VERSION ""

NS_ :

BS_:

BU_: RLPSU DPSU APSU PSB SHVU_RR vHS_B2 FCS EMCU SLB RCM CGW_CCU vDummy_HS_B ATS RLHV PFSU SGU ALBCU DSAU SWRC SHVU_FR RCS RRPSU BLTN_CAM SCM DLBCU OHCL RWPC RRHV WPC HOD ASAU

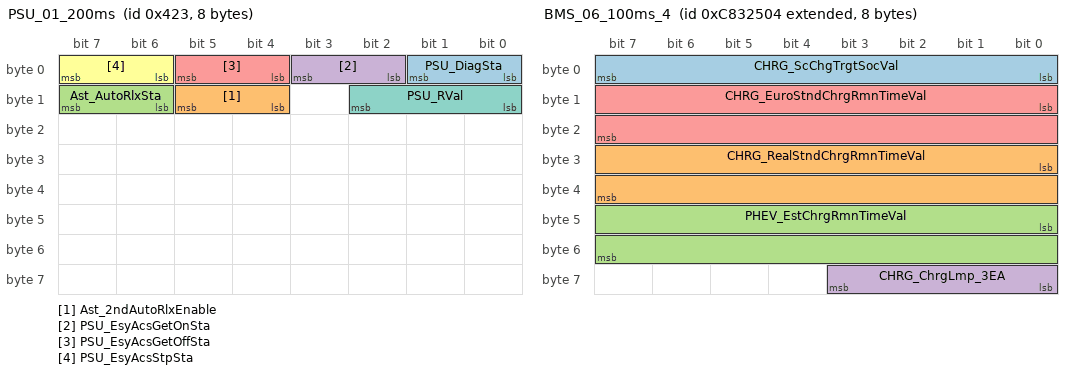
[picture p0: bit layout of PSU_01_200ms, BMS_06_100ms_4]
BO_ 1059 PSU_01_200ms: 8 APSU
 SG_ PSU_DiagSta : 0|2@1+ (1,0) [0|0] ""  Vector__XXX
 SG_ Ast_2ndAutoRlxEnable : 12|2@1+ (1,0) [0|0] ""  RLPSU,RRPSU
 SG_ Ast_AutoRlxSta : 14|2@1+ (1,0) [0|0] ""  RLPSU,RRPSU
 SG_ PSU_EsyAcsGetOnSta : 2|2@1+ (1,0) [0|0] ""  SLB
 SG_ PSU_EsyAcsGetOffSta : 4|2@1+ (1,0) [0|0] ""  SLB
 SG_ PSU_EsyAcsStpSta : 6|2@1+ (1,0) [0|0] ""  SLB
 SG_ PSU_RVal : 8|3@1+ (1,0) [0|0] ""  Vector__XXX

BO_ 2357404932 BMS_06_100ms_4: 8 CGW_CCU
 SG_ CHRG_ScChgTrgtSocVal : 0|8@1+ (0.5,0) [0|0] "%"  Vector__XXX
 SG_ CHRG_RealStndChrgRmnTimeVal : 24|16@1+ (1,0) [0|0] "minute"  Vector__XXX
 SG_ PHEV_EstChrgRmnTimeVal : 40|16@1+ (1,0) [0|0] "min"  Vector__XXX
 SG_ CHRG_ChrgLmp_3EA : 56|4@1+ (1,0) [0|0] "minute"  Vector__XXX
 SG_ CHRG_EuroStndChrgRmnTimeVal : 8|16@1+ (1,0) [0|0] "minute"  Vector__XXX

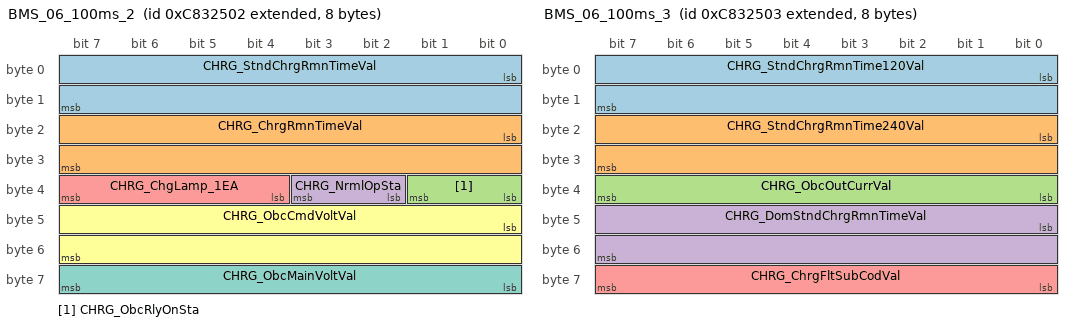
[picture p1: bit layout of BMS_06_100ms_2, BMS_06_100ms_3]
BO_ 2357404930 BMS_06_100ms_2: 8 CGW_CCU
 SG_ CHRG_StndChrgRmnTimeVal : 0|16@1+ (1,0) [0|0] "minute"  Vector__XXX
 SG_ CHRG_ChrgRmnTimeVal : 16|16@1+ (1,0) [0|0] "min"  Vector__XXX
 SG_ CHRG_ObcRlyOnSta : 32|2@1+ (1,0) [0|0] ""  Vector__XXX
 SG_ CHRG_NrmlOpSta : 34|2@1+ (1,0) [0|0] ""  Vector__XXX
 SG_ CHRG_ChgLamp_1EA : 36|4@1+ (1,0) [0|0] ""  Vector__XXX
 SG_ CHRG_ObcCmdVoltVal : 40|16@1+ (0.1,0) [0|0] "V"  Vector__XXX
 SG_ CHRG_ObcMainVoltVal : 56|8@1+ (2,0) [0|0] "V"  Vector__XXX

BO_ 2357404931 BMS_06_100ms_3: 8 CGW_CCU
 SG_ CHRG_StndChrgRmnTime120Val : 0|16@1+ (1,0) [0|0] "minute"  Vector__XXX
 SG_ CHRG_StndChrgRmnTime240Val : 16|16@1+ (1,0) [0|0] "minute"  Vector__XXX
 SG_ CHRG_ObcOutCurrVal : 32|8@1+ (0.1,0) [0|0] "A"  Vector__XXX
 SG_ CHRG_DomStndChrgRmnTimeVal : 40|16@1+ (1,0) [0|0] "minute"  Vector__XXX
 SG_ CHRG_ChrgFltSubCodVal : 56|8@1+ (1,0) [0|0] ""  Vector__XXX

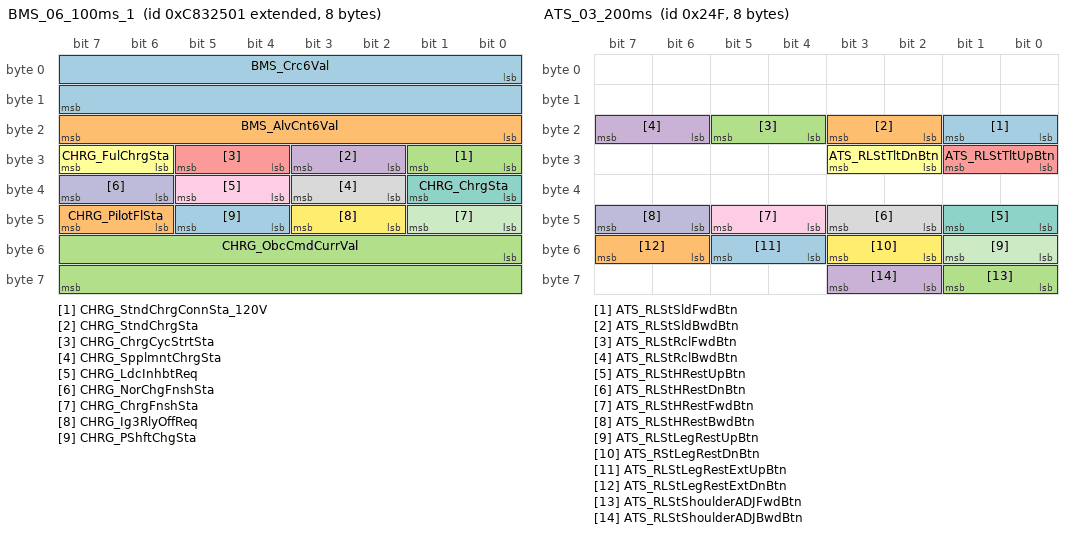
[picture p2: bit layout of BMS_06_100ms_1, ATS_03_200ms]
BO_ 2357404929 BMS_06_100ms_1: 8 CGW_CCU
 SG_ BMS_Crc6Val : 0|16@1+ (1,0) [0|0] ""  Vector__XXX
 SG_ BMS_AlvCnt6Val : 16|8@1+ (1,0) [0|0] ""  Vector__XXX
 SG_ CHRG_StndChrgConnSta_120V : 24|2@1+ (1,0) [0|0] "flag"  Vector__XXX
 SG_ CHRG_StndChrgSta : 26|2@1+ (1,0) [0|0] ""  Vector__XXX
 SG_ CHRG_ChrgCycStrtSta : 28|2@1+ (1,0) [0|0] ""  Vector__XXX
 SG_ CHRG_FulChrgSta : 30|2@1+ (1,0) [0|0] ""  Vector__XXX
 SG_ CHRG_ChrgSta : 32|2@1+ (1,0) [0|0] ""  SWRC
 SG_ CHRG_SpplmntChrgSta : 34|2@1+ (1,0) [0|0] ""  Vector__XXX
 SG_ CHRG_LdcInhbtReq : 36|2@1+ (1,0) [0|0] ""  Vector__XXX
 SG_ CHRG_NorChgFnshSta : 38|2@1+ (1,0) [0|0] ""  Vector__XXX
 SG_ CHRG_ChrgFnshSta : 40|2@1+ (1,0) [0|0] ""  Vector__XXX
 SG_ CHRG_Ig3RlyOffReq : 42|2@1+ (1,0) [0|0] ""  Vector__XXX
 SG_ CHRG_PShftChgSta : 44|2@1+ (1,0) [0|0] "flag"  Vector__XXX
 SG_ CHRG_PilotFlSta : 46|2@1+ (1,0) [0|0] "flag"  Vector__XXX
 SG_ CHRG_ObcCmdCurrVal : 48|16@1+ (0.1,0) [0|0] "A"  Vector__XXX

BO_ 591 ATS_03_200ms: 8 ATS
 SG_ ATS_RLStSldFwdBtn : 16|2@1+ (1,0) [0|0] ""  Vector__XXX
 SG_ ATS_RLStSldBwdBtn : 18|2@1+ (1,0) [0|0] ""  Vector__XXX
 SG_ ATS_RLStRclFwdBtn : 20|2@1+ (1,0) [0|0] ""  Vector__XXX
 SG_ ATS_RLStRclBwdBtn : 22|2@1+ (1,0) [0|0] ""  Vector__XXX
 SG_ ATS_RLStTltUpBtn : 24|2@1+ (1,0) [0|0] ""  Vector__XXX
 SG_ ATS_RLStTltDnBtn : 26|2@1+ (1,0) [0|0] ""  Vector__XXX
 SG_ ATS_RLStHRestUpBtn : 40|2@1+ (1,0) [0|0] ""  Vector__XXX
 SG_ ATS_RLStHRestDnBtn : 42|2@1+ (1,0) [0|0] ""  Vector__XXX
 SG_ ATS_RLStHRestFwdBtn : 44|2@1+ (1,0) [0|0] ""  Vector__XXX
 SG_ ATS_RLStHRestBwdBtn : 46|2@1+ (1,0) [0|0] ""  Vector__XXX
 SG_ ATS_RLStLegRestUpBtn : 48|2@1+ (1,0) [0|0] ""  Vector__XXX
 SG_ ATS_RStLegRestDnBtn : 50|2@1+ (1,0) [0|0] ""  Vector__XXX
 SG_ ATS_RLStLegRestExtUpBtn : 52|2@1+ (1,0) [0|0] ""  Vector__XXX
 SG_ ATS_RLStLegRestExtDnBtn : 54|2@1+ (1,0) [0|0] ""  Vector__XXX
 SG_ ATS_RLStShoulderADJFwdBtn : 56|2@1+ (1,0) [0|0] ""  Vector__XXX
 SG_ ATS_RLStShoulderADJBwdBtn : 58|2@1+ (1,0) [0|0] ""  Vector__XXX

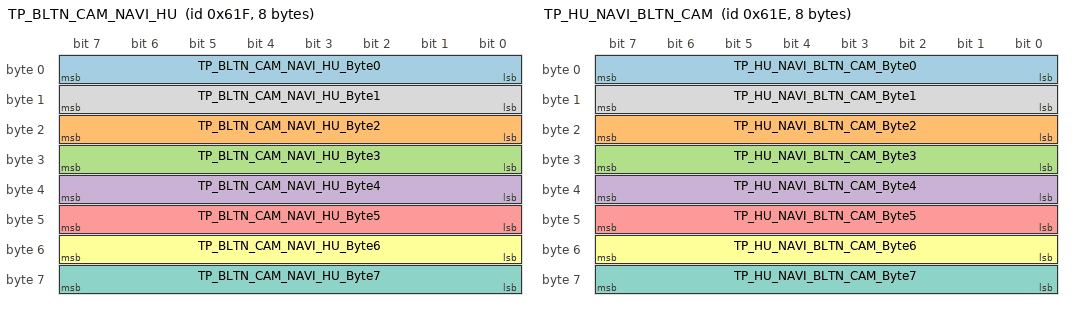
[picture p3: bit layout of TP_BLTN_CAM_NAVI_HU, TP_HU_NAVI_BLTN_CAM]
BO_ 1567 TP_BLTN_CAM_NAVI_HU: 8 BLTN_CAM
 SG_ TP_BLTN_CAM_NAVI_HU_Byte0 : 0|8@1+ (1,0) [0|0] ""  CGW_CCU
 SG_ TP_BLTN_CAM_NAVI_HU_Byte2 : 16|8@1+ (1,0) [0|0] ""  CGW_CCU
 SG_ TP_BLTN_CAM_NAVI_HU_Byte3 : 24|8@1+ (1,0) [0|0] ""  CGW_CCU
 SG_ TP_BLTN_CAM_NAVI_HU_Byte4 : 32|8@1+ (1,0) [0|0] ""  CGW_CCU
 SG_ TP_BLTN_CAM_NAVI_HU_Byte5 : 40|8@1+ (1,0) [0|0] ""  CGW_CCU
 SG_ TP_BLTN_CAM_NAVI_HU_Byte6 : 48|8@1+ (1,0) [0|0] ""  CGW_CCU
 SG_ TP_BLTN_CAM_NAVI_HU_Byte7 : 56|8@1+ (1,0) [0|0] ""  CGW_CCU
 SG_ TP_BLTN_CAM_NAVI_HU_Byte1 : 8|8@1+ (1,0) [0|0] ""  CGW_CCU

BO_ 1566 TP_HU_NAVI_BLTN_CAM: 8 CGW_CCU
 SG_ TP_HU_NAVI_BLTN_CAM_Byte0 : 0|8@1+ (1,0) [0|0] ""  BLTN_CAM
 SG_ TP_HU_NAVI_BLTN_CAM_Byte2 : 16|8@1+ (1,0) [0|0] ""  BLTN_CAM
 SG_ TP_HU_NAVI_BLTN_CAM_Byte3 : 24|8@1+ (1,0) [0|0] ""  BLTN_CAM
 SG_ TP_HU_NAVI_BLTN_CAM_Byte4 : 32|8@1+ (1,0) [0|0] ""  BLTN_CAM
 SG_ TP_HU_NAVI_BLTN_CAM_Byte5 : 40|8@1+ (1,0) [0|0] ""  BLTN_CAM
 SG_ TP_HU_NAVI_BLTN_CAM_Byte6 : 48|8@1+ (1,0) [0|0] ""  BLTN_CAM
 SG_ TP_HU_NAVI_BLTN_CAM_Byte7 : 56|8@1+ (1,0) [0|0] ""  BLTN_CAM
 SG_ TP_HU_NAVI_BLTN_CAM_Byte1 : 8|8@1+ (1,0) [0|0] ""  BLTN_CAM

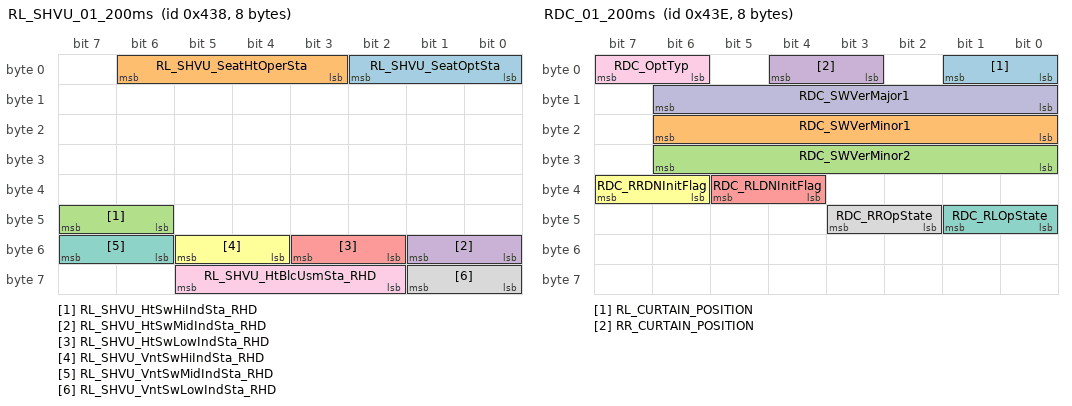
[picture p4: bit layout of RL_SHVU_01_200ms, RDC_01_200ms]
BO_ 1080 RL_SHVU_01_200ms: 8 RLHV
 SG_ RL_SHVU_SeatOptSta : 0|3@1+ (1,0) [0|0] ""  ATS,CGW_CCU
 SG_ RL_SHVU_SeatHtOperSta : 3|4@1+ (1,0) [0|0] ""  ATS,CGW_CCU
 SG_ RL_SHVU_HtSwHiIndSta_RHD : 46|2@1+ (1,0) [0|0] ""  ATS,CGW_CCU,CGW_CCU
 SG_ RL_SHVU_HtSwMidIndSta_RHD : 48|2@1+ (1,0) [0|0] ""  ATS,CGW_CCU
 SG_ RL_SHVU_HtSwLowIndSta_RHD : 50|2@1+ (1,0) [0|0] ""  ATS,CGW_CCU
 SG_ RL_SHVU_VntSwHiIndSta_RHD : 52|2@1+ (1,0) [0|0] ""  ATS,CGW_CCU
 SG_ RL_SHVU_VntSwMidIndSta_RHD : 54|2@1+ (1,0) [0|0] ""  ATS,CGW_CCU
 SG_ RL_SHVU_VntSwLowIndSta_RHD : 56|2@1+ (1,0) [0|0] ""  ATS,CGW_CCU
 SG_ RL_SHVU_HtBlcUsmSta_RHD : 58|4@1+ (1,0) [0|0] ""  ATS,CGW_CCU

BO_ 1086 RDC_01_200ms: 8 CGW_CCU
 SG_ RL_CURTAIN_POSITION : 0|2@1+ (1,0) [0|0] ""  ATS
 SG_ RDC_SWVerMinor1 : 16|7@1+ (1,0) [0|0] ""  Vector__XXX
 SG_ RDC_SWVerMinor2 : 24|7@1+ (1,0) [0|0] ""  Vector__XXX
 SG_ RR_CURTAIN_POSITION : 3|2@1+ (1,0) [0|0] ""  ATS
 SG_ RDC_RLDNInitFlag : 36|2@1+ (1,0) [0|0] ""  Vector__XXX
 SG_ RDC_RRDNInitFlag : 38|2@1+ (1,0) [0|0] ""  Vector__XXX
 SG_ RDC_RLOpState : 40|2@1+ (1,0) [0|0] ""  Vector__XXX
 SG_ RDC_RROpState : 42|2@1+ (1,0) [0|0] ""  Vector__XXX
 SG_ RDC_OptTyp : 6|2@1+ (1,0) [0|0] ""  ATS
 SG_ RDC_SWVerMajor1 : 8|7@1+ (1,0) [0|0] ""  Vector__XXX

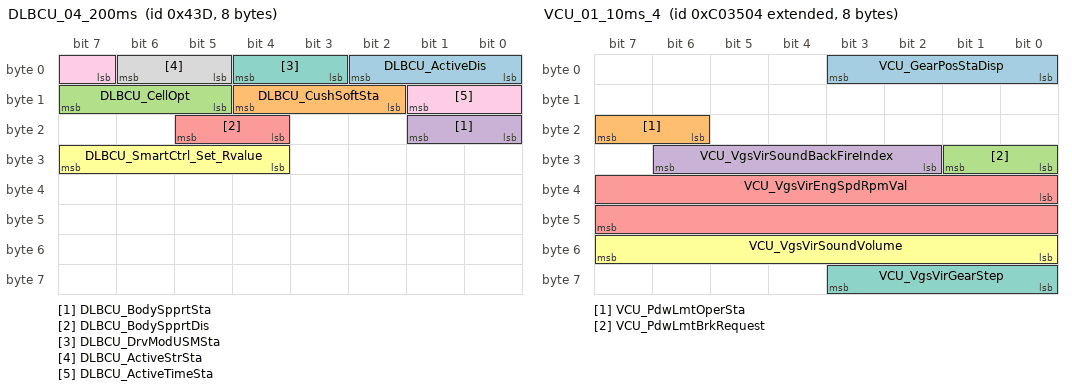
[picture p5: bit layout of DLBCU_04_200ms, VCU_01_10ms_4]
BO_ 1085 DLBCU_04_200ms: 8 DLBCU
 SG_ DLBCU_ActiveDis : 0|3@1+ (1,0) [0|0] ""  DPSU,CGW_CCU
 SG_ DLBCU_CushSoftSta : 10|3@1+ (1,0) [0|0] ""  CGW_CCU
 SG_ DLBCU_CellOpt : 13|3@1+ (1,0) [0|0] ""  Vector__XXX
 SG_ DLBCU_BodySpprtSta : 16|2@1+ (1,0) [0|0] ""  CGW_CCU
 SG_ DLBCU_BodySpprtDis : 20|2@1+ (1,0) [0|0] ""  CGW_CCU
 SG_ DLBCU_SmartCtrl_Set_Rvalue : 28|4@1+ (1,0) [0|0] ""  CGW_CCU
 SG_ DLBCU_DrvModUSMSta : 3|2@1+ (1,0) [0|0] ""  CGW_CCU
 SG_ DLBCU_ActiveStrSta : 5|2@1+ (1,0) [0|0] ""  CGW_CCU
 SG_ DLBCU_ActiveTimeSta : 7|3@1+ (1,0) [0|0] ""  CGW_CCU

BO_ 2160080132 VCU_01_10ms_4: 8 CGW_CCU
 SG_ VCU_GearPosStaDisp : 0|4@1+ (1,0) [0|0] ""  BLTN_CAM
 SG_ VCU_PdwLmtOperSta : 22|2@1+ (1,0) [0|0] ""  Vector__XXX
 SG_ VCU_PdwLmtBrkRequest : 24|2@1+ (1,0) [0|0] ""  Vector__XXX
 SG_ VCU_VgsVirSoundBackFireIndex : 26|5@1+ (1,0) [0|0] ""  Vector__XXX
 SG_ VCU_VgsVirEngSpdRpmVal : 32|16@1- (1,0) [0|0] ""  Vector__XXX
 SG_ VCU_VgsVirSoundVolume : 48|8@1+ (0.392156863,0) [0|0] ""  Vector__XXX
 SG_ VCU_VgsVirGearStep : 56|4@1+ (1,0) [0|0] ""  Vector__XXX

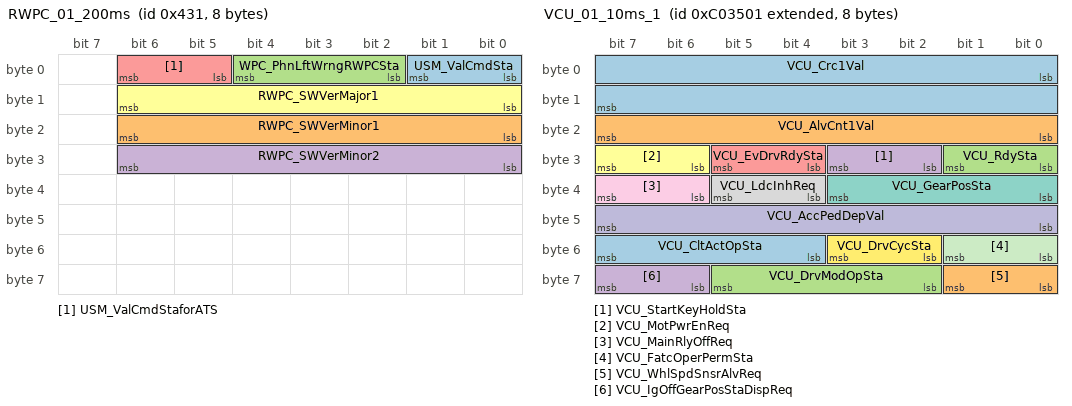
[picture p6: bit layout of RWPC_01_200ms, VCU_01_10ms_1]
BO_ 1073 RWPC_01_200ms: 8 RWPC
 SG_ USM_ValCmdSta : 0|2@1+ (1,0) [0|0] ""  ATS,CGW_CCU
 SG_ RWPC_SWVerMinor1 : 16|7@1+ (1,0) [0|0] ""  CGW_CCU
 SG_ WPC_PhnLftWrngRWPCSta : 2|3@1+ (1,0) [0|0] ""  ATS,CGW_CCU
 SG_ RWPC_SWVerMinor2 : 24|7@1+ (1,0) [0|0] ""  CGW_CCU
 SG_ USM_ValCmdStaforATS : 5|2@1+ (1,0) [0|0] ""  ATS
 SG_ RWPC_SWVerMajor1 : 8|7@1+ (1,0) [0|0] ""  CGW_CCU

BO_ 2160080129 VCU_01_10ms_1: 8 CGW_CCU
 SG_ VCU_Crc1Val : 0|16@1+ (1,0) [0|0] ""  Vector__XXX
 SG_ VCU_AlvCnt1Val : 16|8@1+ (1,0) [0|0] ""  Vector__XXX
 SG_ VCU_RdySta : 24|2@1+ (1,0) [0|3] ""  Vector__XXX
 SG_ VCU_StartKeyHoldSta : 26|2@1+ (1,0) [0|3] ""  Vector__XXX
 SG_ VCU_EvDrvRdySta : 28|2@1+ (1,0) [0|3] ""  WPC,RWPC,SWRC,HOD,BLTN_CAM
 SG_ VCU_MotPwrEnReq : 30|2@1+ (1,0) [0|3] ""  Vector__XXX
 SG_ VCU_GearPosSta : 32|4@1+ (1,0) [0|15] ""  SWRC,APSU,DPSU,PFSU,RRPSU,RLPSU,BLTN_CAM
 SG_ VCU_LdcInhReq : 36|2@1+ (1,0) [0|3] ""  Vector__XXX
 SG_ VCU_MainRlyOffReq : 38|2@1+ (1,0) [0|3] ""  Vector__XXX
 SG_ VCU_AccPedDepVal : 40|8@1+ (0.3921568627,0) [0|100] "%"  BLTN_CAM
 SG_ VCU_FatcOperPermSta : 48|2@1+ (1,0) [0|3] ""  Vector__XXX
 SG_ VCU_DrvCycSta : 50|2@1+ (1,0) [0|3] ""  Vector__XXX
 SG_ VCU_CltActOpSta : 52|4@1+ (1,0) [0|15] ""  Vector__XXX
 SG_ VCU_WhlSpdSnsrAlvReq : 56|2@1+ (1,0) [0|0] "flag"  Vector__XXX
 SG_ VCU_DrvModOpSta : 58|4@1+ (1,0) [0|0] ""  Vector__XXX
 SG_ VCU_IgOffGearPosStaDispReq : 62|2@1+ (1,0) [0|0] "flag"  Vector__XXX

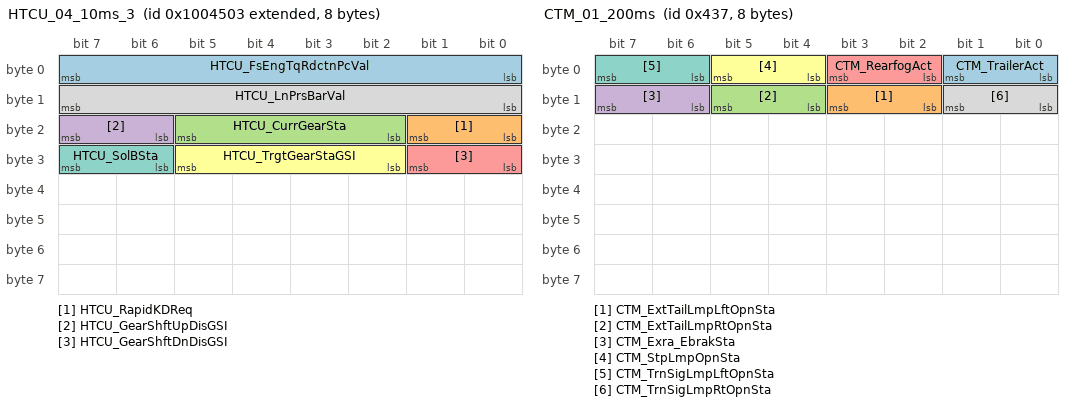
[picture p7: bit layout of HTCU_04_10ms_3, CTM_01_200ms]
BO_ 2164278531 HTCU_04_10ms_3: 8 CGW_CCU
 SG_ HTCU_FsEngTqRdctnPcVal : 0|8@1+ (0.390625,0) [0|0] "%"  Vector__XXX
 SG_ HTCU_RapidKDReq : 16|2@1+ (1,0) [0|0] ""  Vector__XXX
 SG_ HTCU_CurrGearSta : 18|4@1+ (1,0) [0|0] ""  Vector__XXX
 SG_ HTCU_GearShftUpDisGSI : 22|2@1+ (1,0) [0|0] ""  Vector__XXX
 SG_ HTCU_GearShftDnDisGSI : 24|2@1+ (1,0) [0|0] ""  Vector__XXX
 SG_ HTCU_TrgtGearStaGSI : 26|4@1+ (1,0) [0|0] ""  Vector__XXX
 SG_ HTCU_SolBSta : 30|2@1+ (1,0) [0|0] ""  Vector__XXX
 SG_ HTCU_LnPrsBarVal : 8|8@1+ (0.1,0) [0|0] "Bar"  Vector__XXX

BO_ 1079 CTM_01_200ms: 8 CGW_CCU
 SG_ CTM_TrailerAct : 0|2@1+ (1,0) [0|0] ""  BLTN_CAM
 SG_ CTM_ExtTailLmpLftOpnSta : 10|2@1+ (1,0) [0|0] ""  Vector__XXX
 SG_ CTM_ExtTailLmpRtOpnSta : 12|2@1+ (1,0) [0|0] ""  Vector__XXX
 SG_ CTM_Exra_EbrakSta : 14|2@1+ (1,0) [0|0] ""  Vector__XXX
 SG_ CTM_RearfogAct : 2|2@1+ (1,0) [0|0] ""  Vector__XXX
 SG_ CTM_StpLmpOpnSta : 4|2@1+ (1,0) [0|0] ""  Vector__XXX
 SG_ CTM_TrnSigLmpLftOpnSta : 6|2@1+ (1,0) [0|0] ""  Vector__XXX
 SG_ CTM_TrnSigLmpRtOpnSta : 8|2@1+ (1,0) [0|0] ""  Vector__XXX

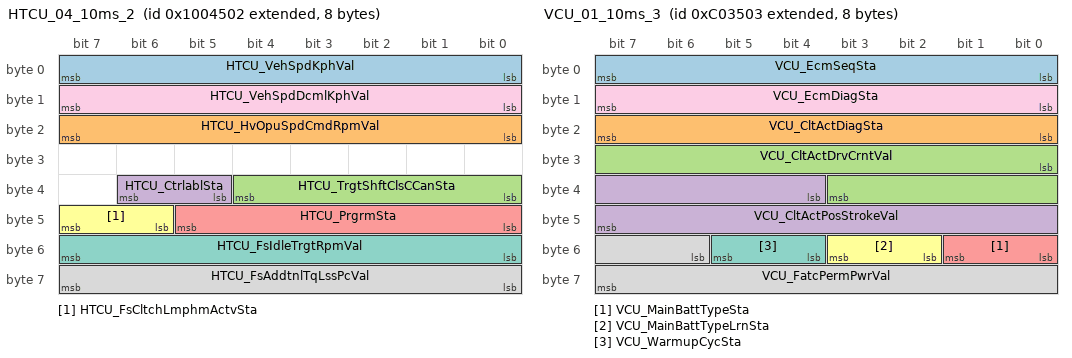
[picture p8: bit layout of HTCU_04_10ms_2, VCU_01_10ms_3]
BO_ 2164278530 HTCU_04_10ms_2: 8 CGW_CCU
 SG_ HTCU_VehSpdKphVal : 0|8@1+ (1,0) [0|0] "kph"  Vector__XXX
 SG_ HTCU_HvOpuSpdCmdRpmVal : 16|8@1+ (20,0) [0|0] "rpm"  Vector__XXX
 SG_ HTCU_TrgtShftClsCCanSta : 32|5@1+ (1,0) [0|0] ""  Vector__XXX
 SG_ HTCU_CtrlablSta : 37|2@1+ (1,0) [0|0] ""  Vector__XXX
 SG_ HTCU_PrgrmSta : 40|6@1+ (1,0) [0|0] ""  Vector__XXX
 SG_ HTCU_FsCltchLmphmActvSta : 46|2@1+ (1,0) [0|0] ""  Vector__XXX
 SG_ HTCU_FsIdleTrgtRpmVal : 48|8@1+ (10,0) [0|0] "rpm"  Vector__XXX
 SG_ HTCU_FsAddtnlTqLssPcVal : 56|8@1+ (0.390625,0) [0|0] "%"  Vector__XXX
 SG_ HTCU_VehSpdDcmlKphVal : 8|8@1+ (0.0078125,0) [0|0] "kph"  Vector__XXX

BO_ 2160080131 VCU_01_10ms_3: 8 CGW_CCU
 SG_ VCU_EcmSeqSta : 0|8@1+ (1,0) [0|255] ""  Vector__XXX
 SG_ VCU_CltActDiagSta : 16|8@1+ (1,0) [0|255] ""  Vector__XXX
 SG_ VCU_CltActDrvCrntVal : 24|12@1- (0.025,0) [-51.2|51.175] "A"  Vector__XXX
 SG_ VCU_CltActPosStrokeVal : 36|12@1- (0.0125,0) [-25.6|25.5875] "mm"  Vector__XXX
 SG_ VCU_MainBattTypeSta : 48|2@1+ (1,0) [0|3] ""  Vector__XXX
 SG_ VCU_MainBattTypeLrnSta : 50|2@1+ (1,0) [0|3] ""  Vector__XXX
 SG_ VCU_WarmupCycSta : 52|2@1+ (1,0) [0|3] ""  Vector__XXX
 SG_ VCU_FatcPermPwrVal : 54|10@1+ (20,0) [0|12700] "W"  Vector__XXX
 SG_ VCU_EcmDiagSta : 8|8@1+ (1,0) [0|255] ""  Vector__XXX

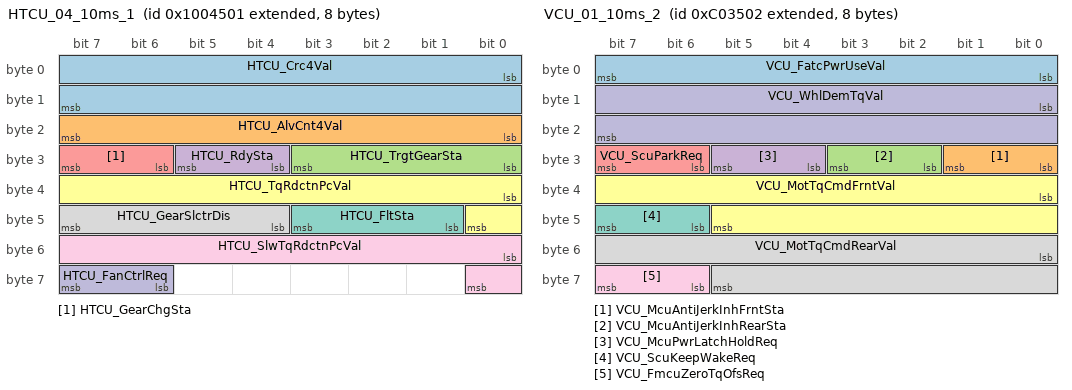
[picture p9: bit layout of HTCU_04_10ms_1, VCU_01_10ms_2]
BO_ 2164278529 HTCU_04_10ms_1: 8 CGW_CCU
 SG_ HTCU_Crc4Val : 0|16@1+ (1,0) [0|0] ""  Vector__XXX
 SG_ HTCU_AlvCnt4Val : 16|8@1+ (1,0) [0|0] ""  Vector__XXX
 SG_ HTCU_TrgtGearSta : 24|4@1+ (1,0) [0|0] ""  Vector__XXX
 SG_ HTCU_RdySta : 28|2@1+ (1,0) [0|0] ""  Vector__XXX
 SG_ HTCU_GearChgSta : 30|2@1+ (1,0) [0|0] ""  Vector__XXX
 SG_ HTCU_TqRdctnPcVal : 32|9@1+ (0.390625,0) [0|0] "%"  Vector__XXX
 SG_ HTCU_FltSta : 41|3@1+ (1,0) [0|0] ""  Vector__XXX
 SG_ HTCU_GearSlctrDis : 44|4@1+ (1,0) [0|0] ""  BLTN_CAM
 SG_ HTCU_SlwTqRdctnPcVal : 48|9@1+ (0.390625,0) [0|0] "%"  Vector__XXX
 SG_ HTCU_FanCtrlReq : 62|2@1+ (1,0) [0|0] ""  Vector__XXX

BO_ 607 ATS_04_200ms: 8 ATS
 SG_ ATS_RRStSldFwdBtn : 16|2@1+ (1,0) [0|0] ""  Vector__XXX
 SG_ ATS_RRStSldBwdBtn : 18|2@1+ (1,0) [0|0] ""  Vector__XXX
 SG_ ATS_RRStRclFwdBtn : 20|2@1+ (1,0) [0|0] ""  Vector__XXX
 SG_ ATS_RRStRclBwdBtn : 22|2@1+ (1,0) [0|0] ""  Vector__XXX
 SG_ ATS_RRStTltUpBtn : 24|2@1+ (1,0) [0|0] ""  Vector__XXX
 SG_ ATS_RRStTltDnBtn : 26|2@1+ (1,0) [0|0] ""  Vector__XXX
 SG_ ATS_RRStLegRestPopBtn : 32|2@1+ (1,0) [0|0] ""  Vector__XXX
 SG_ ATS_RRStFRestPopBtn : 34|2@1+ (1,0) [0|0] ""  Vector__XXX
 SG_ ATS_RRStAstPopBtn : 36|2@1+ (1,0) [0|0] ""  Vector__XXX
 SG_ ATS_RRFauCondiBtn : 38|2@1+ (1,0) [0|0] ""  Vector__XXX
 SG_ ATS_RRStHRestUpBtn : 40|2@1+ (1,0) [0|0] ""  Vector__XXX
 SG_ ATS_RRStHRestDnBtn : 42|2@1+ (1,0) [0|0] ""  Vector__XXX
 SG_ ATS_RRStHRestFwdBtn : 44|2@1+ (1,0) [0|0] ""  Vector__XXX
 SG_ ATS_RRStHRestBwdBtn : 46|2@1+ (1,0) [0|0] ""  Vector__XXX
 SG_ ATS_RRStShoulderADJFwdBtn : 48|2@1+ (1,0) [0|0] ""  Vector__XXX
 SG_ ATS_RRStShoulderADJBwdBtn : 50|2@1+ (1,0) [0|0] ""  Vector__XXX
 SG_ ATS_RRStLegRestUpBtn : 56|2@1+ (1,0) [0|0] ""  Vector__XXX
 SG_ ATS_RRStLegRestDnBtn : 58|2@1+ (1,0) [0|0] ""  Vector__XXX
 SG_ ATS_RRStLegRestExtUpBtn : 60|2@1+ (1,0) [0|0] ""  Vector__XXX
 SG_ ATS_RRStLegRestExtDnBtn : 62|2@1+ (1,0) [0|0] ""  Vector__XXX

BO_ 2160080130 VCU_01_10ms_2: 8 CGW_CCU
 SG_ VCU_FatcPwrUseVal : 0|8@1+ (10,0) [0|2550] "W"  Vector__XXX
 SG_ VCU_McuAntiJerkInhFrntSta : 24|2@1+ (1,0) [0|3] ""  Vector__XXX
 SG_ VCU_McuAntiJerkInhRearSta : 26|2@1+ (1,0) [0|3] ""  Vector__XXX
 SG_ VCU_McuPwrLatchHoldReq : 28|2@1+ (1,0) [0|0] ""  Vector__XXX
 SG_ VCU_ScuParkReq : 30|2@1+ (1,0) [0|0] "flag"  Vector__XXX
 SG_ VCU_MotTqCmdFrntVal : 32|14@1- (0.125,0) [-1024|1023.875] "Nm"  Vector__XXX
 SG_ VCU_ScuKeepWakeReq : 46|2@1+ (1,0) [0|0] "flag"  Vector__XXX
 SG_ VCU_MotTqCmdRearVal : 48|14@1- (0.125,0) [-1024|1023.875] "Nm"  Vector__XXX
 SG_ VCU_FmcuZeroTqOfsReq : 62|2@1+ (1,0) [0|0] "flag"  Vector__XXX
 SG_ VCU_WhlDemTqVal : 8|16@1- (1,0) [-32768|32767] "Nm"  Vector__XXX

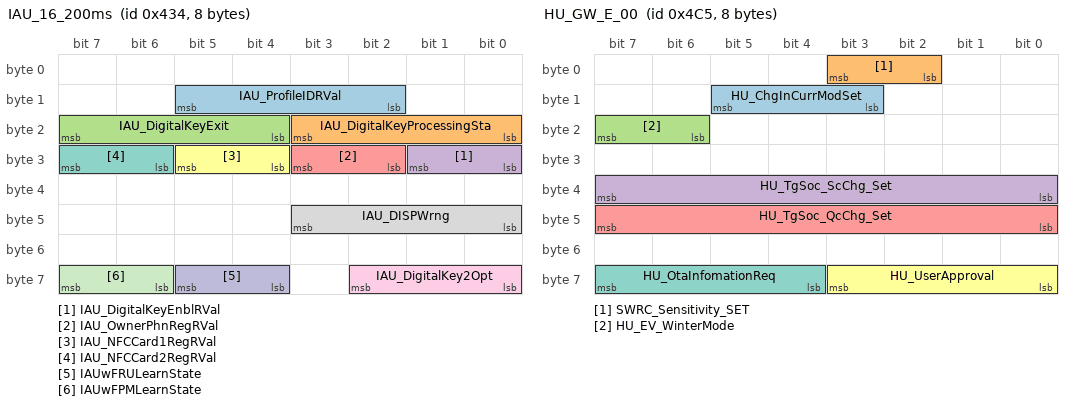
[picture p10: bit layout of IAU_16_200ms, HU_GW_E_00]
BO_ 1076 IAU_16_200ms: 8 CGW_CCU
 SG_ IAU_ProfileIDRVal : 10|4@1+ (1,0) [0|0] ""  WPC,RWPC,DPSU,BLTN_CAM,SGU
 SG_ IAU_DigitalKeyProcessingSta : 16|4@1+ (1,0) [0|0] ""  Vector__XXX
 SG_ IAU_DigitalKeyExit : 20|4@1+ (1,0) [0|0] ""  Vector__XXX
 SG_ IAU_DigitalKeyEnblRVal : 24|2@1+ (1,0) [0|0] ""  Vector__XXX
 SG_ IAU_OwnerPhnRegRVal : 26|2@1+ (1,0) [0|0] ""  Vector__XXX
 SG_ IAU_NFCCard1RegRVal : 28|2@1+ (1,0) [0|0] ""  Vector__XXX
 SG_ IAU_NFCCard2RegRVal : 30|2@1+ (1,0) [0|0] ""  Vector__XXX
 SG_ IAU_DISPWrng : 40|4@1+ (1,0) [0|0] ""  Vector__XXX
 SG_ IAU_DigitalKey2Opt : 56|3@1+ (1,0) [0|0] ""  WPC
 SG_ IAUwFRULearnState : 60|2@1+ (1,0) [0|0] ""  Vector__XXX
 SG_ IAUwFPMLearnState : 62|2@1+ (1,0) [0|0] ""  Vector__XXX

BO_ 1221 HU_GW_E_00: 8 CGW_CCU
 SG_ HU_ChgInCurrModSet : 11|3@1+ (1,0) [0|0] ""  Vector__XXX
 SG_ SWRC_Sensitivity_SET : 2|2@1+ (1,0) [0|0] ""  SWRC
 SG_ HU_EV_WinterMode : 22|2@1+ (1,0) [0|0] ""  Vector__XXX
 SG_ HU_TgSoc_ScChg_Set : 32|8@1+ (0.5,0) [0|100] "%"  Vector__XXX
 SG_ HU_TgSoc_QcChg_Set : 40|8@1+ (0.5,0) [0|100] "%"  Vector__XXX
 SG_ HU_UserApproval : 56|4@1+ (1,0) [0|0] ""  Vector__XXX
 SG_ HU_OtaInfomationReq : 60|4@1+ (1,0) [0|0] ""  Vector__XXX

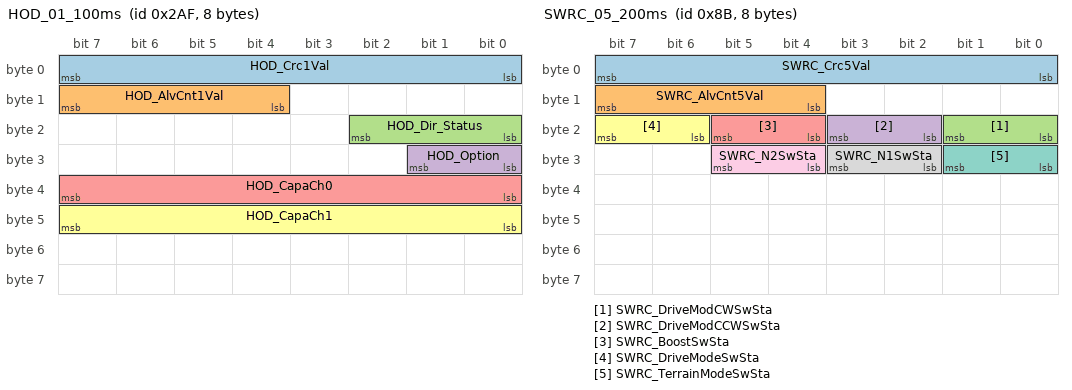
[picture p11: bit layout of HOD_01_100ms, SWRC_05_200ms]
BO_ 687 HOD_01_100ms: 8 HOD
 SG_ HOD_Crc1Val : 0|8@1+ (1,0) [0|0] ""  CGW_CCU
 SG_ HOD_AlvCnt1Val : 12|4@1+ (1,0) [0|0] ""  CGW_CCU
 SG_ HOD_Dir_Status : 16|3@1+ (1,0) [0|0] ""  CGW_CCU
 SG_ HOD_Option : 24|2@1+ (1,0) [0|0] ""  CGW_CCU
 SG_ HOD_CapaCh0 : 32|8@1+ (1,0) [0|0] ""  CGW_CCU
 SG_ HOD_CapaCh1 : 40|8@1+ (1,0) [0|0] ""  CGW_CCU

BO_ 139 SWRC_05_200ms: 8 SWRC
 SG_ SWRC_Crc5Val : 0|8@1+ (1,0) [0|0] ""  CGW_CCU
 SG_ SWRC_AlvCnt5Val : 12|4@1+ (1,0) [0|0] ""  CGW_CCU
 SG_ SWRC_DriveModCWSwSta : 16|2@1+ (1,0) [0|0] ""  CGW_CCU
 SG_ SWRC_DriveModCCWSwSta : 18|2@1+ (1,0) [0|0] ""  CGW_CCU
 SG_ SWRC_BoostSwSta : 20|2@1+ (1,0) [0|0] ""  CGW_CCU
 SG_ SWRC_DriveModeSwSta : 22|2@1+ (1,0) [0|0] ""  CGW_CCU
 SG_ SWRC_TerrainModeSwSta : 24|2@1+ (1,0) [0|0] ""  CGW_CCU
 SG_ SWRC_N1SwSta : 26|2@1+ (1,0) [0|0] ""  CGW_CCU
 SG_ SWRC_N2SwSta : 28|2@1+ (1,0) [0|0] ""  CGW_CCU

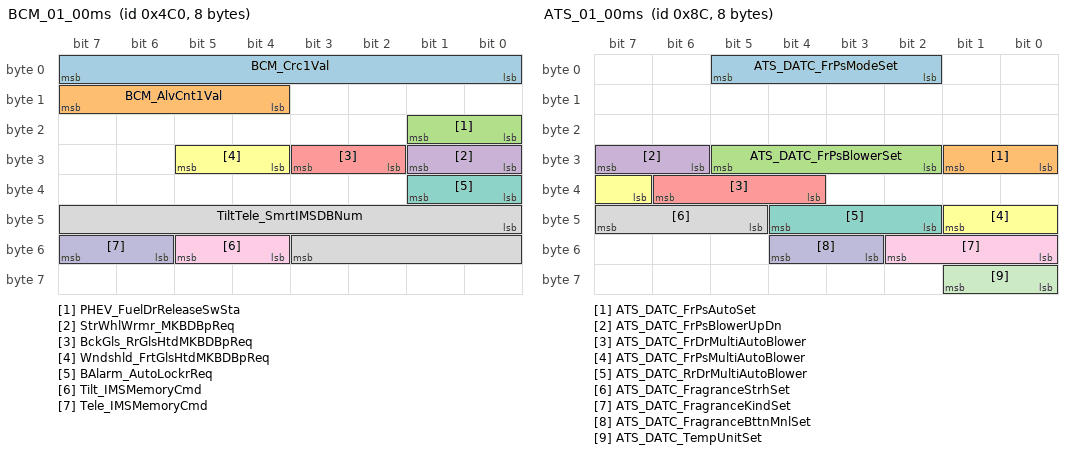
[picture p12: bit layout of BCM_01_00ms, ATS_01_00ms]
BO_ 1216 BCM_01_00ms: 8 CGW_CCU
 SG_ BCM_Crc1Val : 0|8@1+ (1,0) [0|0] ""  Vector__XXX
 SG_ BCM_AlvCnt1Val : 12|4@1+ (1,0) [0|0] ""  Vector__XXX
 SG_ PHEV_FuelDrReleaseSwSta : 16|2@1+ (1,0) [0|0] ""  Vector__XXX
 SG_ StrWhlWrmr_MKBDBpReq : 24|2@1+ (1,0) [0|0] ""  Vector__XXX
 SG_ BckGls_RrGlsHtdMKBDBpReq : 26|2@1+ (1,0) [0|0] ""  Vector__XXX
 SG_ Wndshld_FrtGlsHtdMKBDBpReq : 28|2@1+ (1,0) [0|0] ""  Vector__XXX
 SG_ BAlarm_AutoLockrReq : 32|2@1+ (1,0) [0|0] ""  Vector__XXX
 SG_ TiltTele_SmrtIMSDBNum : 40|12@1+ (1,0) [0|0] ""  SCM
 SG_ Tilt_IMSMemoryCmd : 52|2@1+ (1,0) [0|0] ""  SCM
 SG_ Tele_IMSMemoryCmd : 54|2@1+ (1,0) [0|0] ""  SCM

BO_ 140 ATS_01_00ms: 8 ATS
 SG_ ATS_DATC_FrPsModeSet : 2|4@1+ (1,0) [0|0] ""  CGW_CCU
 SG_ ATS_DATC_FrPsAutoSet : 24|2@1+ (1,0) [0|0] ""  CGW_CCU
 SG_ ATS_DATC_FrPsBlowerSet : 26|4@1+ (1,0) [0|0] ""  CGW_CCU
 SG_ ATS_DATC_FrPsBlowerUpDn : 30|2@1+ (1,0) [0|0] ""  CGW_CCU
 SG_ ATS_DATC_FrDrMultiAutoBlower : 36|3@1+ (1,0) [0|0] ""  CGW_CCU
 SG_ ATS_DATC_FrPsMultiAutoBlower : 39|3@1+ (1,0) [0|0] ""  CGW_CCU
 SG_ ATS_DATC_RrDrMultiAutoBlower : 42|3@1+ (1,0) [0|0] ""  CGW_CCU
 SG_ ATS_DATC_FragranceStrhSet : 45|3@1+ (1,0) [0|0] ""  CGW_CCU
 SG_ ATS_DATC_FragranceKindSet : 48|3@1+ (1,0) [0|0] ""  CGW_CCU
 SG_ ATS_DATC_FragranceBttnMnlSet : 51|2@1+ (1,0) [0|0] ""  CGW_CCU
 SG_ ATS_DATC_TempUnitSet : 56|2@1+ (1,0) [0|0] ""  CGW_CCU

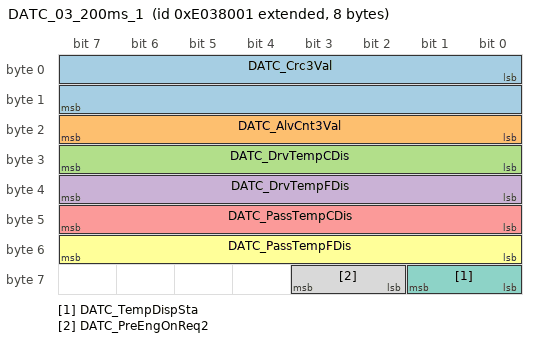
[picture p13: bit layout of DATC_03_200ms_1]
BO_ 2382594049 DATC_03_200ms_1: 8 CGW_CCU
 SG_ DATC_Crc3Val : 0|16@1+ (1,0) [0|0] ""  Vector__XXX
 SG_ DATC_AlvCnt3Val : 16|8@1+ (1,0) [0|0] ""  Vector__XXX
 SG_ DATC_DrvTempCDis : 24|8@1+ (0.5,14) [0|0] "¡É"  ATS
 SG_ DATC_DrvTempFDis : 32|8@1+ (1,56) [0|0] "¢µ"  ATS
 SG_ DATC_PassTempCDis : 40|8@1+ (0.5,14) [0|0] "¡É"  ATS
 SG_ DATC_PassTempFDis : 48|8@1+ (1,56) [0|0] "¢µ"  ATS
 SG_ DATC_TempDispSta : 56|2@1+ (1,0) [0|0] ""  Vector__XXX
 SG_ DATC_PreEngOnReq2 : 58|2@1+ (1,0) [0|0] ""  Vector__XXX

BO_ 1219 HU_BLTN_CAM_E_00: 8 CGW_CCU
 SG_ BLTN_CAM_Rec_OWD_NvalueSet : 0|2@1+ (1,0) [0|0] ""  BLTN_CAM
 SG_ BLTN_CAM_Time_Stm_NvalueSet : 10|2@1+ (1,0) [0|0] ""  BLTN_CAM
 SG_ BLTN_CAM_Spd_Stm_NvalueSet : 12|2@1+ (1,0) [0|0] ""  BLTN_CAM
 SG_ BLTN_CAM_Locatn_Stm_NvalueSet : 14|2@1+ (1,0) [0|0] ""  BLTN_CAM
 SG_ BLTN_CAM_TrnSig_Stm_NvalueSet : 16|2@1+ (1,0) [0|0] ""  BLTN_CAM
 SG_ BLTN_CAM_AclBrk_Stm_NvalueSet : 18|2@1+ (1,0) [0|0] ""  BLTN_CAM
 SG_ BLTN_CAM_Rec_DEV_NvalueSet : 2|2@1+ (1,0) [0|0] ""  BLTN_CAM
 SG_ BLTN_CAM_GearPos_Stm_NvalueSet : 20|2@1+ (1,0) [0|0] ""  BLTN_CAM
 SG_ BLTN_CAM_EVSen_Stm_NvalueSet : 22|2@1+ (1,0) [0|0] ""  BLTN_CAM
 SG_ BLTN_CAM_Strangl_Stm_NvalueSet : 24|2@1+ (1,0) [0|0] ""  BLTN_CAM
 SG_ BLTN_CAM_PrkTime_NvalueSet : 30|8@1+ (1,0) [0|0] "Hour"  BLTN_CAM
 SG_ BLTN_CAM_EV_BfrTime_NvalueSet : 38|5@1+ (1,0) [0|0] ""  BLTN_CAM
 SG_ BLTN_CAM_Rec_OWP_NvalueSet : 4|2@1+ (1,0) [0|0] ""  BLTN_CAM
 SG_ BLTN_CAM_EV_AftTime_NvalueSet : 43|5@1+ (1,0) [0|0] ""  BLTN_CAM
 SG_ BLTN_CAM_TML_Int_NvalueSet : 48|4@1+ (1,0) [0|0] ""  BLTN_CAM
 SG_ BLTN_CAM_Sen_DEV_NvalueSet : 52|4@1+ (1,0) [0|0] ""  BLTN_CAM
 SG_ BLTN_CAM_Sen_PEV_NvalueSet : 56|4@1+ (1,0) [0|0] ""  BLTN_CAM
 SG_ BLTN_CAM_Rec_PEV_NvalueSet : 6|2@1+ (1,0) [0|0] ""  BLTN_CAM
 SG_ BLTN_CAM_AudRec_NvalueSet : 8|2@1+ (1,0) [0|0] ""  BLTN_CAM

BO_TX_BU_ 1080 : RLHV,SHVU_RR,SHVU_FR,RLPSU;
CM_ BO_ 140 "[EC] On Event and On Change";
CM_ SG_ 140 ATS_DATC_FrPsModeSet "Front Passenger side Mode Set";
CM_ SG_ 140 ATS_DATC_FrPsAutoSet "Front Passenger side Auto Set";
CM_ SG_ 140 ATS_DATC_FrPsBlowerSet "Front Passenger side Blower Set";
CM_ SG_ 140 ATS_DATC_FrPsBlowerUpDn "Front Passenger side Blower Up Down";
CM_ SG_ 140 ATS_DATC_FrDrMultiAutoBlower "Front Driver side Multi-Auto Blower set";
CM_ SG_ 140 ATS_DATC_FrPsMultiAutoBlower "Front Passenger side Multi-Auto Blower set";
CM_ SG_ 140 ATS_DATC_RrDrMultiAutoBlower "Rear Driver side Multi-Auto Blower set";
CM_ SG_ 140 ATS_DATC_FragranceStrhSet "Fragrance Strength Set (¹ßÇâ ±â´É Çâ ¼¼±â ¼³Á¤)";
CM_ SG_ 140 ATS_DATC_FragranceKindSet "Fragrance Kind Set (¹ßÇâ ±â´É Çâ Á¾·ù ¼³Á¤)";
CM_ SG_ 140 ATS_DATC_FragranceBttnMnlSet "Fragrance Button Manual Set (¹ßÇâ ±â´É ¹öÆ° ¼öµ¿ ÀÔ·Â)";
CM_ SG_ 140 ATS_DATC_TempUnitSet "Temp Unit Set (¿Âµµ ´ÜÀ§ ¼³Á¤)";
CM_ BO_ 591 "[PE] Periodic and On Event";
CM_ SG_ 591 ATS_RLStSldFwdBtn "Rear Left Power Seat Slide Forward Touch Button";
CM_ SG_ 591 ATS_RLStSldBwdBtn "Rear Left Power Seat Slide Backward Touch Button";
CM_ SG_ 591 ATS_RLStRclFwdBtn "Rear Left Power Seat Recline Forward Touch Button";
CM_ SG_ 591 ATS_RLStRclBwdBtn "Rear Left Power Seat Recline Backward Touch Button";
CM_ SG_ 591 ATS_RLStTltUpBtn "Rear Left Power Seat Tilt Up Touch Button";
CM_ SG_ 591 ATS_RLStTltDnBtn "Rear Left Power Seat Tilt Down Touch Button";
CM_ SG_ 591 ATS_RLStHRestUpBtn "Rear Left Power Seat Head Rest Up Touch Button";
CM_ SG_ 591 ATS_RLStHRestDnBtn "Rear Left Power Seat Head Rest Down Touch Button";
CM_ SG_ 591 ATS_RLStHRestFwdBtn "Rear Left Power Seat Head Rest Forward Touch Button";
CM_ SG_ 591 ATS_RLStHRestBwdBtn "Rear Left Power Seat Head Rest Backward Touch Button";
CM_ SG_ 591 ATS_RLStLegRestUpBtn "Rear Left Power Seat Leg Rest Up Touch Button";
CM_ SG_ 591 ATS_RStLegRestDnBtn "Rear Left Power Seat Leg Rest Down Touch Button";
CM_ SG_ 591 ATS_RLStLegRestExtUpBtn "Rear Left Power Seat Leg Rest Ext. Up Touch Button";
CM_ SG_ 591 ATS_RLStLegRestExtDnBtn "Rear Left Power Seat Leg Rest Ext. Down Touch Button";
CM_ SG_ 591 ATS_RLStShoulderADJFwdBtn "Rear Left Power Seat Shoulder Adjuster Forward Touch Button";
CM_ SG_ 591 ATS_RLStShoulderADJBwdBtn "Rear Left Power Seat Shoulder Adjuster Backward Touch Button";
CM_ BO_ 607 "[PE] Periodic and On Event";
CM_ SG_ 607 ATS_RRStSldFwdBtn "Rear Right Power Seat Slide Forward Touch Button";
CM_ SG_ 607 ATS_RRStSldBwdBtn "Rear Right Power Seat Slide Backward Touch Button";
CM_ SG_ 607 ATS_RRStRclFwdBtn "Rear Right Power Seat Recline Forward Touch Button";
CM_ SG_ 607 ATS_RRStRclBwdBtn "Rear Right Power Seat Recline Backward Touch Button";
CM_ SG_ 607 ATS_RRStTltUpBtn "Rear Right Power Seat Tilt Up Touch Button";
CM_ SG_ 607 ATS_RRStTltDnBtn "Rear Right Power Seat Tilt Down Touch Button";
CM_ SG_ 607 ATS_RRStLegRestPopBtn "Rear Right Leg Rest Move Pop Up Button";
CM_ SG_ 607 ATS_RRStFRestPopBtn "Rear Right Foot Rest Move Pop Up Button";
CM_ SG_ 607 ATS_RRStAstPopBtn "Rear Right Assist Seat Move Pop Up Button";
CM_ SG_ 607 ATS_RRFauCondiBtn "Rear Right FAU Operational Condition Move Button";
CM_ SG_ 607 ATS_RRStHRestUpBtn "Rear Right Power Seat Head Rest Up Touch Button";
CM_ SG_ 607 ATS_RRStHRestDnBtn "Rear Right Power Seat Head Rest Down Touch Button";
CM_ SG_ 607 ATS_RRStHRestFwdBtn "Rear Right Power Seat Head Rest Forward Touch Button";
CM_ SG_ 607 ATS_RRStHRestBwdBtn "Rear Right Power Seat Head Rest Backward Touch Button";
CM_ SG_ 607 ATS_RRStShoulderADJFwdBtn "Rear Right Power Seat Shoulder Adjuster Forward Touch Button";
CM_ SG_ 607 ATS_RRStShoulderADJBwdBtn "Rear Right Power Seat Shoulder Adjuster Backward Touch Button";
CM_ SG_ 607 ATS_RRStLegRestUpBtn "Rear Right Power Seat Leg Rest Up Touch Button";
CM_ SG_ 607 ATS_RRStLegRestDnBtn "Rear Right Power Seat Leg Rest Down Touch Button";
CM_ SG_ 607 ATS_RRStLegRestExtUpBtn "Rear Right Power Seat Leg Rest Ext. Up Touch Button";
CM_ SG_ 607 ATS_RRStLegRestExtDnBtn "Rear Right Power Seat Leg Rest Ext. Down Touch Button";
CM_ BO_ 1216 "[EC] On Event and On Change";
CM_ SG_ 1216 BCM_Crc1Val "BCM_CyclicRedundancyCheck1Value";
CM_ SG_ 1216 BCM_AlvCnt1Val "BCM_AliveCounter1Value";
CM_ SG_ 1216 PHEV_FuelDrReleaseSwSta "PHEV_FuelDoorReleaseSwitchStatus ##2G##BCM - BCMmsg01 - C_FuelDrReleaseSw";
CM_ SG_ 1216 BAlarm_AutoLockrReq "BAlarm_AutoLockRequest ##2G##BCM - BCMmsg01 - C_AutoLockCmd";
CM_ BO_ 2357404929 "[P] Periodic";
CM_ SG_ 2357404929 BMS_Crc6Val "BMS_CyclicRedundancyCheck6Value";
CM_ SG_ 2357404929 BMS_AlvCnt6Val "BMS_AliveCounter6Value";
CM_ SG_ 2357404929 CHRG_StndChrgConnSta_120V "CHRG_StandardChargeConnectStatus";
CM_ SG_ 2357404929 CHRG_StndChrgSta "CHRG_StandardChargeStatus";
CM_ SG_ 2357404929 CHRG_ChrgCycStrtSta "CHRG_ChargingCycleStartStatus";
CM_ SG_ 2357404929 CHRG_FulChrgSta "CHRG_FullyChargeStatus";
CM_ SG_ 2357404929 CHRG_ChrgSta "CHRG_ChargeStatus";
CM_ SG_ 2357404929 CHRG_SpplmntChrgSta "CHRG_SupplementaryChargeStatus";
CM_ SG_ 2357404929 CHRG_LdcInhbtReq "CHRG_LdcInhibitRequest";
CM_ SG_ 2357404929 CHRG_NorChgFnshSta "CHRG_ChargeNormalFinishConditionStatus";
CM_ SG_ 2357404929 CHRG_ChrgFnshSta "CHRG_ChargeFinishStatus";
CM_ SG_ 2357404929 CHRG_Ig3RlyOffReq "CHRG_Ig3RelayOffRequest";
CM_ SG_ 2357404929 CHRG_PShftChgSta "CHRG_PShiftChangeStatus";
CM_ SG_ 2357404929 CHRG_PilotFlSta "CHRG_PilotlineFailStatus";
CM_ SG_ 2357404929 CHRG_ObcCmdCurrVal "CHRG_ObcCommandCurrentValue";
CM_ BO_ 2357404930 "[P] Periodic";
CM_ SG_ 2357404930 CHRG_StndChrgRmnTimeVal "CHRG_StandardChargeRemainedTimeValue";
CM_ SG_ 2357404930 CHRG_ChrgRmnTimeVal "CHRG_ChargeRemainedTimeValue";
CM_ SG_ 2357404930 CHRG_ObcRlyOnSta "CHRG_ObcRelayOnStatus";
CM_ SG_ 2357404930 CHRG_NrmlOpSta "CHRG_NormalOperationStatus";
CM_ SG_ 2357404930 CHRG_ChgLamp_1EA "CHRG_ChargeLampRequest (1EA Lamp)";
CM_ SG_ 2357404930 CHRG_ObcCmdVoltVal "CHRG_ObcCommandVoltageValue";
CM_ SG_ 2357404930 CHRG_ObcMainVoltVal "CHRG_ObcMainVoltageValue";
CM_ BO_ 2357404931 "[P] Periodic";
CM_ SG_ 2357404931 CHRG_StndChrgRmnTime120Val "CHRG_StandardChargeRemainedTime120Value";
CM_ SG_ 2357404931 CHRG_StndChrgRmnTime240Val "CHRG_StandardChargeRemainedTime240Value";
CM_ SG_ 2357404931 CHRG_ObcOutCurrVal "CHRG_ObcOutputCurrentValue";
CM_ SG_ 2357404931 CHRG_DomStndChrgRmnTimeVal "CHRG_DomesticStandardChargeRemainedTime";
CM_ SG_ 2357404931 CHRG_ChrgFltSubCodVal "CHRG_ChargeFaultSubCodeValue";
CM_ BO_ 2357404932 "[P] Periodic";
CM_ SG_ 2357404932 CHRG_ScChgTrgtSocVal "CHRG_TargetStateOfScChargeValue";
CM_ SG_ 2357404932 CHRG_RealStndChrgRmnTimeVal "CHRG_RealStandardChargeRemainedTime";
CM_ SG_ 2357404932 PHEV_EstChrgRmnTimeVal "PHEV_EstimatedChargeRemainedTimeValue";
CM_ SG_ 2357404932 CHRG_ChrgLmp_3EA "CHRG_Charge Lamp(3EA Lamp)";
CM_ SG_ 2357404932 CHRG_EuroStndChrgRmnTimeVal "CHRG_EuroStandardChargeRemainedTime";
CM_ BO_ 1079 "[PE] Periodic and On Event";
CM_ SG_ 1079 CTM_TrailerAct "This signal is used for control the Trailer Act function.";
CM_ SG_ 1079 CTM_ExtTailLmpLftOpnSta "Trailer Exterior Tail Lamp Left OpenStatus";
CM_ SG_ 1079 CTM_ExtTailLmpRtOpnSta "Trailer Exterior Tail Lamp Right OpenStatus";
CM_ SG_ 1079 CTM_Exra_EbrakSta "Trailer Exterior Ebrake Out OnOffStatus";
CM_ SG_ 1079 CTM_RearfogAct "This signal is used for display the rear fog lamp mounted on the trailer.";
CM_ SG_ 1079 CTM_StpLmpOpnSta "Trailer Stop Lamp OpenStatus";
CM_ SG_ 1079 CTM_TrnSigLmpLftOpnSta "Trailer T/SIG Lamp Left OpenStatus";
CM_ SG_ 1079 CTM_TrnSigLmpRtOpnSta "Trailer T/SIG Lamp Right OpenStatus";
CM_ BO_ 2382594049 "[PE] Periodic and On Event";
CM_ SG_ 2382594049 DATC_Crc3Val "DATC_CyclicRedundancyCheck3Value";
CM_ SG_ 2382594049 DATC_AlvCnt3Val "DATC_AliveCounter3Value";
CM_ SG_ 2382594049 DATC_DrvTempCDis "DATC_DriverTemperatureCelciusDisplay";
CM_ SG_ 2382594049 DATC_DrvTempFDis "DATC_DriverTemperatureFahrenheitDisplay";
CM_ SG_ 2382594049 DATC_PassTempCDis "DATC_PassengerTemperatureCelciusDisplay";
CM_ SG_ 2382594049 DATC_PassTempFDis "DATC_PassengerTemperatureFahrenheitDisplay";
CM_ SG_ 2382594049 DATC_TempDispSta "DATCTempDisplayStatus";
CM_ SG_ 2382594049 DATC_PreEngOnReq2 "Pre Engine On Request";
CM_ BO_ 1085 "[PE] Periodic and On Event";
CM_ SG_ 1085 DLBCU_ActiveDis "DLBCU_ActiveModeDisplay";
CM_ SG_ 1085 DLBCU_CushSoftSta "DLBCU_CushionSoftnessStatus";
CM_ SG_ 1085 DLBCU_CellOpt "DLBCU_CellOption Status";
CM_ SG_ 1085 DLBCU_BodySpprtSta "Seat Body Support Function USM R Value";
CM_ SG_ 1085 DLBCU_BodySpprtDis "Seat body Support Function Display Request";
CM_ SG_ 1085 DLBCU_SmartCtrl_Set_Rvalue "ÁÖÇà Áß Çã¸® º¸È£ ±â´É USM µ¿ÀÛ ¼³Á¤ °ª (R Value)";
CM_ SG_ 1085 DLBCU_DrvModUSMSta "DLBCU_DriveModeStatus";
CM_ SG_ 1085 DLBCU_ActiveStrSta "DLBCU_ActiveStrengthStatus";
CM_ SG_ 1085 DLBCU_ActiveTimeSta "DLBCU_ActiveTimeStatus";
CM_ BO_ 687 "[P] Periodic";
CM_ SG_ 687 HOD_Crc1Val "HOD_CyclicRedundancyCheck1Value";
CM_ SG_ 687 HOD_AlvCnt1Val "HOD_AliveCounter1Value";
CM_ SG_ 687 HOD_Dir_Status "hands on-off status";
CM_ SG_ 687 HOD_Option "HOD_Option";
CM_ SG_ 687 HOD_CapaCh0 "Front zone Capacitance value(pF)";
CM_ SG_ 687 HOD_CapaCh1 "Rear zone Capacitance value(pF)";
CM_ BO_ 2164278529 "[P] Periodic";
CM_ SG_ 2164278529 HTCU_Crc4Val "HTCU_CyclicRedundancyCheck4Value";
CM_ SG_ 2164278529 HTCU_AlvCnt4Val "HTCU_AliveCounter4Value";
CM_ SG_ 2164278529 HTCU_TrgtGearSta "HTCU_TargetGearStatus";
CM_ SG_ 2164278529 HTCU_RdySta "HTCU_ReadyStatus";
CM_ SG_ 2164278529 HTCU_GearChgSta "HTCU_GearChangeStatus";
CM_ SG_ 2164278529 HTCU_TqRdctnPcVal "HTCU_TorqueReductionPcValue";
CM_ SG_ 2164278529 HTCU_FltSta "HTCU_FaultStatus";
CM_ SG_ 2164278529 HTCU_GearSlctrDis "HTCU_GearSelectDisplay";
CM_ SG_ 2164278529 HTCU_SlwTqRdctnPcVal "HTCU_SlowTorqueReductionPcValue";
CM_ SG_ 2164278529 HTCU_FanCtrlReq "Fan control request by OPU";
CM_ BO_ 2164278530 "[P] Periodic";
CM_ SG_ 2164278530 HTCU_VehSpdKphVal "HTCU_VehicleSpeedKphValue";
CM_ SG_ 2164278530 HTCU_HvOpuSpdCmdRpmVal "HTCU_HvOpuSpeedCommandRpmValue";
CM_ SG_ 2164278530 HTCU_TrgtShftClsCCanSta "HTCU_TargetShiftClassCCanStatus";
CM_ SG_ 2164278530 HTCU_PrgrmSta "HTCU_ProgramStatus";
CM_ SG_ 2164278530 HTCU_FsCltchLmphmActvSta "HTCU_FsClutchLimphomeActivationStatus";
CM_ SG_ 2164278530 HTCU_FsIdleTrgtRpmVal "HTCU_FsIdleTargetRpmValue";
CM_ SG_ 2164278530 HTCU_FsAddtnlTqLssPcVal "HTCU_FsAdditionalTorqueLossPcValue";
CM_ SG_ 2164278530 HTCU_VehSpdDcmlKphVal "HTCU_VehicleSpeedDecimalKphValue";
CM_ BO_ 2164278531 "[P] Periodic";
CM_ SG_ 2164278531 HTCU_FsEngTqRdctnPcVal "HTCU_FsEngineTorqueReductionPcValue";
CM_ SG_ 2164278531 HTCU_RapidKDReq "HTCU_RapidKDRequest";
CM_ SG_ 2164278531 HTCU_CurrGearSta "HTCU_CurrentGearStatus";
CM_ SG_ 2164278531 HTCU_GearShftUpDisGSI "HTCU_GearShiftUpDisplayGSI";
CM_ SG_ 2164278531 HTCU_GearShftDnDisGSI "HTCU_GearShiftDownDisplayGSI";
CM_ SG_ 2164278531 HTCU_TrgtGearStaGSI "HTCU_TargetGearStatusGSI";
CM_ SG_ 2164278531 HTCU_SolBSta "HTCU_SolenoidBStatus";
CM_ SG_ 2164278531 HTCU_LnPrsBarVal "HTCU_LinePressureBarValue";
CM_ BO_ 1219 "[EC] On Event and On Change";
CM_ SG_ 1219 BLTN_CAM_Rec_OWD_NvalueSet "Record On/Off Set of On While Driving";
CM_ SG_ 1219 BLTN_CAM_Time_Stm_NvalueSet "Record Set of Date and Time Stamp";
CM_ SG_ 1219 BLTN_CAM_Spd_Stm_NvalueSet "Record Set of Speed Stamp";
CM_ SG_ 1219 BLTN_CAM_Locatn_Stm_NvalueSet "Record Set of Location Stamp";
CM_ SG_ 1219 BLTN_CAM_TrnSig_Stm_NvalueSet "Record Set of Turn Signal Stamp";
CM_ SG_ 1219 BLTN_CAM_AclBrk_Stm_NvalueSet "Record Set of Accelerator Brake Stamp";
CM_ SG_ 1219 BLTN_CAM_Rec_DEV_NvalueSet "Record On/Off Set of Driving Event";
CM_ SG_ 1219 BLTN_CAM_GearPos_Stm_NvalueSet "Record Set of Gear Position Stamp";
CM_ SG_ 1219 BLTN_CAM_EVSen_Stm_NvalueSet "Record Set of Event Sensitivity Stamp";
CM_ SG_ 1219 BLTN_CAM_Strangl_Stm_NvalueSet "Record Set of Steering Angle Stamp";
CM_ SG_ 1219 BLTN_CAM_PrkTime_NvalueSet "Parking Operation Setting Time, Resolution : hr";
CM_ SG_ 1219 BLTN_CAM_EV_BfrTime_NvalueSet "Driving Event Time Setting - Before, Resolution : sec";
CM_ SG_ 1219 BLTN_CAM_Rec_OWP_NvalueSet "Record On/Off Set of On While Parked, 0x0(Default) : Parking recording function not supported";
CM_ SG_ 1219 BLTN_CAM_EV_AftTime_NvalueSet "Driving Event Time Setting - After, Resolution : sec";
CM_ SG_ 1219 BLTN_CAM_TML_Int_NvalueSet "Record Set of Time-lapse Interval, Resolution : sec";
CM_ SG_ 1219 BLTN_CAM_Sen_DEV_NvalueSet "Set of Event  Detection Sensitivity of Driving Mode";
CM_ SG_ 1219 BLTN_CAM_Sen_PEV_NvalueSet "Set of Event  Detection Sensitivity of Parking Mode";
CM_ SG_ 1219 BLTN_CAM_Rec_PEV_NvalueSet "Record Set of Parked Event, 0x0(Default) : Parking recording function not supported";
CM_ SG_ 1219 BLTN_CAM_AudRec_NvalueSet "Audio Record On/Off Set";
CM_ BO_ 1221 "[EC] On Event and On Change";
CM_ SG_ 1221 HU_ChgInCurrModSet "Charge current set signal";
CM_ SG_ 1221 SWRC_Sensitivity_SET "SWRC_OpticalSwtich_Sensitivity_Setting";
CM_ SG_ 1221 HU_EV_WinterMode "<For after OS/DE/SK3 EV/AE PE EV>

EV Battery temp. up setting on/off 
- setting signal : CR_Bms_WinterMode";
CM_ SG_ 1221 HU_TgSoc_ScChg_Set "<For after OS/DE/SK3 EV>
Target SOC user setting value for slow charger(SC/AC).
- For EV only";
CM_ SG_ 1221 HU_TgSoc_QcChg_Set "<For after OS/DE/SK3 EV>
Target SOC user setting value for fast charger(QC/DC).
- For EV only";
CM_ BO_ 1076 "[PE] Periodic and On Event";
CM_ SG_ 1076 IAU_ProfileIDRVal "This signal Indicate the Current detected Profile ID by IAU.";
CM_ SG_ 1076 IAU_DigitalKeyProcessingSta "Digital Key USM settitng Process State";
CM_ SG_ 1076 IAU_DigitalKeyExit "Digital Key USM setting Exit Condition";
CM_ SG_ 1076 IAU_DigitalKeyEnblRVal "Digital Key Function Enable / Disable flag (Fob is required for changing flag)";
CM_ SG_ 1076 IAU_OwnerPhnRegRVal "Vehicle Owner's Phone is Registered for Digital Key function";
CM_ SG_ 1076 IAU_NFCCard1RegRVal "NFC Card 1 is Registered for Digital Key function";
CM_ SG_ 1076 IAU_NFCCard2RegRVal "NFC Card 2 is Registered for Digital Key function";
CM_ SG_ 1076 IAU_DigitalKey2Opt "Digital Key2 Option Signal";
CM_ BO_ 1059 "[PE] Periodic and On Event";
CM_ SG_ 1059 PSU_DiagSta "PSU_DiagnosticStatus";
CM_ SG_ 1059 PSU_EsyAcsGetOnSta "PSU_EasyAccessGetOnStatus";
CM_ SG_ 1059 PSU_EsyAcsGetOffSta "PSU_EasyAccessGetOffStatus";
CM_ SG_ 1059 PSU_EsyAcsStpSta "PSU_EasyAccessStopStatus";
CM_ SG_ 1059 PSU_RVal "PSU_RValue";
CM_ BO_ 1086 "[PE] Periodic and On Event";
CM_ SG_ 1086 RL_CURTAIN_POSITION "Rear Left Curtain Status Position Output";
CM_ SG_ 1086 RDC_SWVerMinor1 "Second Word(ASCII) in RDC S/W Ver";
CM_ SG_ 1086 RDC_SWVerMinor2 "Third Word(ASCII) in RDC S/W Ver";
CM_ SG_ 1086 RR_CURTAIN_POSITION "Rear Right Curtain Status Position Output";
CM_ SG_ 1086 RDC_RLDNInitFlag "Rear Left Door Curtain Down Initialized Finish Flag";
CM_ SG_ 1086 RDC_RRDNInitFlag "Rear Right Door Curtain Down Initialized Finish Flag";
CM_ SG_ 1086 RDC_RLOpState "Rear Left Door Curtain Operating State Feedback";
CM_ SG_ 1086 RDC_RROpState "Rear Right Door Curtain Operating State Feedback";
CM_ SG_ 1086 RDC_OptTyp "OPTION FLAG for RDC";
CM_ SG_ 1086 RDC_SWVerMajor1 "First Word(ASCII) in RDC S/W Ver";
CM_ BO_ 1080 "[PE] Periodic and On Event";
CM_ SG_ 1080 RL_SHVU_SeatOptSta "Rear LH Seat Heater/Vent option info";
CM_ SG_ 1080 RL_SHVU_SeatHtOperSta "Rear LH Seat Heater/Vent current operation state";
CM_ SG_ 1080 RL_SHVU_HtSwHiIndSta_RHD "Rear Left_Seat Heater Switch High Indicator Status";
CM_ SG_ 1080 RL_SHVU_HtSwMidIndSta_RHD "Rear Left_Seat Heater Switch Mid Indicator Status";
CM_ SG_ 1080 RL_SHVU_HtSwLowIndSta_RHD "Rear Left_Seat Heater Switch Low Indicator Status";
CM_ SG_ 1080 RL_SHVU_VntSwHiIndSta_RHD "Rear Left Seat Vent Switch High Indicator Status";
CM_ SG_ 1080 RL_SHVU_VntSwMidIndSta_RHD "Rear Left Seat Vent Switch Mid Indicator Status";
CM_ SG_ 1080 RL_SHVU_VntSwLowIndSta_RHD "Rear Left Seat Vent Switch Low Indicator Status";
CM_ SG_ 1080 RL_SHVU_HtBlcUsmSta_RHD "RL Seat Heater Balance Status(RHD)";
CM_ BO_ 1073 "[PE] Periodic and On Event";
CM_ SG_ 1073 USM_ValCmdSta "USM_ValueCommandStatus";
CM_ SG_ 1073 RWPC_SWVerMinor1 "Second Word(ASCII) in RWPC S/W Ver";
CM_ SG_ 1073 WPC_PhnLftWrngRWPCSta "WPC_PhoneLeftWaringRWPCStatus";
CM_ SG_ 1073 RWPC_SWVerMinor2 "Third Word(ASCII) in RWPC S/W Ver";
CM_ SG_ 1073 USM_ValCmdStaforATS "USM_ValueCommandStatus";
CM_ SG_ 1073 RWPC_SWVerMajor1 "First Word(ASCII) in RWPC S/W Ver";
CM_ BO_ 139 "[PE] Periodic and On Event";
CM_ BO_ 1567 "[TP] Transport Protocol";
CM_ BO_ 1566 "[TP] Transport Protocol";
CM_ BO_ 2160080129 "[P] Periodic";
CM_ SG_ 2160080129 VCU_Crc1Val "VCU_CyclicRedundancyCheck1Value";
CM_ SG_ 2160080129 VCU_AlvCnt1Val "VCU_AliveCounter1Value";
CM_ SG_ 2160080129 VCU_RdySta "VCU_ReadyStatus ##2G##VCU - VCU1 - CF_Vcu_Rdy";
CM_ SG_ 2160080129 VCU_StartKeyHoldSta "VCU_StartKeyHoldStatus ##2G##VCU - VCU1 - CF_Vcu_Key_ST";
CM_ SG_ 2160080129 VCU_EvDrvRdySta "VCU_EvDriveReadyStatus ##2G##VCU - VCU1 - CF_Vcu_EvRdy";
CM_ SG_ 2160080129 VCU_MotPwrEnReq "VCU_MotorPowerEnableRequest ##2G##VCU - VCU3 - CF_Vcu_MotPwrEna";
CM_ SG_ 2160080129 VCU_GearPosSta "VCU_GearPositionStatus ##2G##VCU - VCU1 - CF_Vcu_GarSelDisp";
CM_ SG_ 2160080129 VCU_LdcInhReq "VCU_LdcInhibitRequest ##2G##VCU - VCU5 - CF_Vcu_LdcInh";
CM_ SG_ 2160080129 VCU_MainRlyOffReq "VCU_MainRelayCutOffRequest ##2G##VCU - VCU1 - CF_Vcu_RelayOffReq";
CM_ SG_ 2160080129 VCU_AccPedDepVal "VCU_AcceleratorPedalDepthValue ##2G##VCU - VCU1 - CR_Vcu_AccPedDep_Pc";
CM_ SG_ 2160080129 VCU_FatcOperPermSta "VCU_FatcOperatingPermissionStatus ##2G##VCU - VCU20 - CF_Vcu_ClimateOperPerm";
CM_ SG_ 2160080129 VCU_DrvCycSta "VCU_DrivingCycleStatus ##2G##VCU - VCU1 - CF_Vcu_Veh_DC";
CM_ SG_ 2160080129 VCU_CltActOpSta "VCU_ClutchActuatorOperatingStatus";
CM_ SG_ 2160080129 VCU_WhlSpdSnsrAlvReq "VCU_WheelSpeedSensorAliveRequest";
CM_ SG_ 2160080129 VCU_DrvModOpSta "VCU's operating drive mode according to CLU and DMIC signals";
CM_ SG_ 2160080129 VCU_IgOffGearPosStaDispReq "VCU_IgOffGearPositionStatusDispayRequest";
CM_ BO_ 2160080130 "[P] Periodic";
CM_ SG_ 2160080130 VCU_FatcPwrUseVal "VCU_FatcPowerUseValue ##2G##VCU - VCU5 - CR_Vcu_FatcCst";
CM_ SG_ 2160080130 VCU_McuAntiJerkInhFrntSta "VCU_McuAntiJerkInhibitionFrontStatus";
CM_ SG_ 2160080130 VCU_McuAntiJerkInhRearSta "VCU_McuAntiJerkInhibitionRearStatus ##2G##VCU - VCU3 - CF_Vcu_MCUAntiJerkInh";
CM_ SG_ 2160080130 VCU_McuPwrLatchHoldReq "VCU_McuPowerLatchHoldRequest ##2G##VCU - VCU20 - CF_Vcu_McuPwrLatchHoldReq";
CM_ SG_ 2160080130 VCU_ScuParkReq "VCU_ScuParkingRequest ##2G##VCU - VCU12 - CF_Vcu_PARKCMD";
CM_ SG_ 2160080130 VCU_MotTqCmdFrntVal "VCU_MotorTorqueCommandFrontValue";
CM_ SG_ 2160080130 VCU_ScuKeepWakeReq "VCU_ScuKeepWakeRequest ##2G##VCU - VCU12 - CF_Vcu_SSD";
CM_ SG_ 2160080130 VCU_MotTqCmdRearVal "VCU_MotorTorqueCommandRearValue";
CM_ SG_ 2160080130 VCU_FmcuZeroTqOfsReq "VCU_FmcuZeroTorqueOffsetRequest";
CM_ SG_ 2160080130 VCU_WhlDemTqVal "VCU_WheelDemandTorqueValue ##2G##VCU - VCU2 - CR_Vcu_WhlDemTq_Nm";
CM_ BO_ 2160080131 "[P] Periodic";
CM_ SG_ 2160080131 VCU_EcmSeqSta "VCU_EcmSequenceStatus ##2G##VCU - VCU1 - CF_Vcu_IGONStatus";
CM_ SG_ 2160080131 VCU_CltActDiagSta "VCU_ClutchActuatorDiagnosisStatus";
CM_ SG_ 2160080131 VCU_CltActDrvCrntVal "VCU_ClutchActuatorDriveCurrentValue";
CM_ SG_ 2160080131 VCU_CltActPosStrokeVal "VCU_ClutchActuatorPositionStrokeValue";
CM_ SG_ 2160080131 VCU_MainBattTypeSta "VCU_MainBatteryTypeStatus ##2G##VCU - VCU18 - CF_Vcu_MainBattType";
CM_ SG_ 2160080131 VCU_MainBattTypeLrnSta "VCU_MainBatteryTypeLearnStatus ##2G##VCU - VCU18 - CF_Vcu_MainBattTypeLrnSts";
CM_ SG_ 2160080131 VCU_WarmupCycSta "VCU_WarmupCycleStatus ##2G##VCU - VCU1 - CF_Vcu_WarmupCyc";
CM_ SG_ 2160080131 VCU_FatcPermPwrVal "VCU_FatcPermissionPowerValue ##2G##VCU - VCU5 - CR_Vcu_ClimatePerm_W";
CM_ SG_ 2160080131 VCU_EcmDiagSta "VCU_EcmDiagnosisStatus";
CM_ BO_ 2160080132 "[P] Periodic";
CM_ SG_ 2160080132 VCU_GearPosStaDisp "VCU_GearPositionStatusDisp";
CM_ SG_ 2160080132 VCU_PdwLmtOperSta "Status of PDW Torque Limit";
CM_ SG_ 2160080132 VCU_PdwLmtBrkRequest "Request brake torque for PDW Torque Limit";
CM_ SG_ 2160080132 VCU_VgsVirSoundBackFireIndex "Virtual sound back fire noise index for VGS mode";
CM_ SG_ 2160080132 VCU_VgsVirEngSpdRpmVal "Virtual engine speed for VGS mode";
CM_ SG_ 2160080132 VCU_VgsVirSoundVolume "Virtual engine sound volume for VGS mode[%]";
CM_ SG_ 2160080132 VCU_VgsVirGearStep "Shift gear when entering VGS mode";
BA_DEF_ BO_ "DiagState" ENUM "No","Yes" ;
BA_DEF_ BO_ "DiagResponse" ENUM "No","Yes" ;
BA_DEF_ BO_ "DiagRequest" ENUM "No","Yes" ;
BA_DEF_ BO_ "TpMessage" ENUM "No","Yes" ;
BA_DEF_ BO_ "UsrMsgIDSforwardDeviation" INT 0 100 ;
BA_DEF_ BO_ "UsrMsgIDSbackwardDeviation" INT 50 1000 ;
BA_DEF_ BO_ "GenMsgCycleTime" INT 0 2000 ;
BA_DEF_ BO_ "GenMsgStartDelayTime" INT 0 2000 ;
BA_DEF_ BO_ "GenMsgSendType" ENUM "Cyclic","NoMsgSendType" ;
BA_DEF_ BO_ "GenMsgCycleTimeFast" INT 0 500 ;
BA_DEF_ BO_ "GenMsgDelayTime" INT 0 20 ;
BA_DEF_ BO_ "GenMsgILSupport" ENUM "No","Yes" ;
BA_DEF_ BO_ "GenMsgNrOfRepetition" INT 0 3 ;
BA_DEF_ BO_ "NmMessage" ENUM "No","Yes" ;
BA_DEF_ BO_ "NWM-Botschaft" ENUM "No","Yes" ;
BA_DEF_ BO_ "TpTxIndex" INT 0 255 ;
BA_DEF_ BO_ "VFrameFormat" ENUM "StandardCAN","ExtendedCAN","reserved","reserved","reserved","reserved","reserved","reserved","reserved","reserved","reserved","reserved","reserved","reserved","StandardCAN_FD","ExtendedCAN_FD" ;
BA_DEF_ SG_ "UserSigValidity" ENUM "B+","ACC","IG","IG1","IG2","IG3","IG1 or IG2","IG1 or IG3","Undef" ;
BA_DEF_ SG_ "TimeoutValue" STRING ;
BA_DEF_ SG_ "UsrSigPurpose" ENUM "Undef","FN","DIAG","DIAG(Req)","DIAG(Res)","DIAG(Phy)","DEV","CCP(Req)","CCP(Res)","NM","TP" ;
BA_DEF_ SG_ "GenSigStartValue" INT 0 1215752192 ;
BA_DEF_ SG_ "NetworkRequest" ENUM "Yes","No" ;
BA_DEF_ SG_ "NetworkRequestHoldingTime" INT 0 65535 ;
BA_DEF_ SG_ "Description" STRING ;
BA_DEF_ SG_ "Version" STRING ;
BA_DEF_ SG_ "GenSigEnvVarType" ENUM "Int","Float","Undef" ;
BA_DEF_ SG_ "GenSigSendType" ENUM "Cyclic","OnWrite","OnWriteWithRepetition","OnChange","OnChangeWithRepetition","IfActive","IfActiveWithRepetition","NoSigSendType","OnChangeAndIfActive","OnChangeAndIfActiveWithRepetition" ;
BA_DEF_ SG_ "GwSigLatencyTime" INT 0 65536 ;
BA_DEF_ SG_ "GwSigMissingSourceType" ENUM "Undef","OldValue","DefaultValue","InitialValue" ;
BA_DEF_ SG_ "NWM-WakeupAllowed" ENUM "<n.a.>" ;
BA_DEF_ SG_ "RoutingFactor" INT 1 1215752192 ;
BA_DEF_REL_ BU_SG_REL_ "GenSigTimeoutTime" INT 0 7000 ;
BA_DEF_DEF_ "DiagState" "No" ;
BA_DEF_DEF_ "DiagResponse" "No" ;
BA_DEF_DEF_ "DiagRequest" "No" ;
BA_DEF_DEF_ "TpMessage" "No" ;
BA_DEF_DEF_ "UsrMsgIDSforwardDeviation" 10 ;
BA_DEF_DEF_ "UsrMsgIDSbackwardDeviation" 100 ;
BA_DEF_DEF_ "GenMsgCycleTime" 200 ;
BA_DEF_DEF_ "GenMsgStartDelayTime" 0 ;
BA_DEF_DEF_ "GenMsgSendType" "NoMsgSendType" ;
BA_DEF_DEF_ "GenMsgCycleTimeFast" 40 ;
BA_DEF_DEF_ "GenMsgDelayTime" 20 ;
BA_DEF_DEF_ "GenMsgILSupport" "Yes" ;
BA_DEF_DEF_ "GenMsgNrOfRepetition" 3 ;
BA_DEF_DEF_ "NmMessage" "No" ;
BA_DEF_DEF_ "NWM-Botschaft" "No" ;
BA_DEF_DEF_ "TpTxIndex" 0 ;
BA_DEF_DEF_ "VFrameFormat" "StandardCAN" ;
BA_DEF_DEF_ "UserSigValidity" "IG" ;
BA_DEF_DEF_ "TimeoutValue" "" ;
BA_DEF_DEF_ "UsrSigPurpose" "FN" ;
BA_DEF_DEF_ "GenSigStartValue" 0 ;
BA_DEF_DEF_ "NetworkRequest" "No" ;
BA_DEF_DEF_ "NetworkRequestHoldingTime" 0 ;
BA_DEF_DEF_ "Description" "" ;
BA_DEF_DEF_ "Version" "" ;
BA_DEF_DEF_ "GenSigEnvVarType" "Undef" ;
BA_DEF_DEF_ "GenSigSendType" "NoSigSendType" ;
BA_DEF_DEF_ "GwSigLatencyTime" 40 ;
BA_DEF_DEF_ "GwSigMissingSourceType" "Undef" ;
BA_DEF_DEF_ "NWM-WakeupAllowed" "<n.a.>" ;
BA_DEF_DEF_ "RoutingFactor" 1 ;
BA_DEF_DEF_REL_ "GenSigTimeoutTime" 500 ;
BA_ "GenMsgCycleTime" BO_ 140 0;
BA_ "Description" SG_ 140 ATS_DATC_FrPsModeSet "Àü¼® Á¶¼ö¼® Ãø ¸ðµå ¼³Á¤";
BA_ "GenSigSendType" SG_ 140 ATS_DATC_FrPsModeSet 4;
BA_ "UserSigValidity" SG_ 140 ATS_DATC_FrPsModeSet 3;
BA_REL_ "GenSigTimeoutTime" BU_SG_REL_ CGW_CCU SG_ 140 ATS_DATC_FrPsModeSet 0;
BA_ "Version" SG_ 140 ATS_DATC_FrPsModeSet "19.12.08";
BA_ "Description" SG_ 140 ATS_DATC_FrPsAutoSet "Àü¼® Á¶¼ö¼® Ãø AUTO ¼³Á¤";
BA_ "GenSigSendType" SG_ 140 ATS_DATC_FrPsAutoSet 4;
BA_ "UserSigValidity" SG_ 140 ATS_DATC_FrPsAutoSet 3;
BA_REL_ "GenSigTimeoutTime" BU_SG_REL_ CGW_CCU SG_ 140 ATS_DATC_FrPsAutoSet 0;
BA_ "Version" SG_ 140 ATS_DATC_FrPsAutoSet "19.12.08";
BA_ "Description" SG_ 140 ATS_DATC_FrPsBlowerSet "Àü¼® Á¶¼ö¼® Ãø ºí·Î¿ö ´Ü¼ö ¼³Á¤";
BA_ "GenSigSendType" SG_ 140 ATS_DATC_FrPsBlowerSet 4;
BA_ "GenSigStartValue" SG_ 140 ATS_DATC_FrPsBlowerSet 15;
BA_ "UserSigValidity" SG_ 140 ATS_DATC_FrPsBlowerSet 3;
BA_REL_ "GenSigTimeoutTime" BU_SG_REL_ CGW_CCU SG_ 140 ATS_DATC_FrPsBlowerSet 0;
BA_ "Version" SG_ 140 ATS_DATC_FrPsBlowerSet "19.12.08";
BA_ "Description" SG_ 140 ATS_DATC_FrPsBlowerUpDn "Àü¼® Á¶¼ö¼® Ãø ºí·Î¿ö Áõ°¨ ¼³Á¤";
BA_ "GenSigSendType" SG_ 140 ATS_DATC_FrPsBlowerUpDn 4;
BA_ "UserSigValidity" SG_ 140 ATS_DATC_FrPsBlowerUpDn 3;
BA_REL_ "GenSigTimeoutTime" BU_SG_REL_ CGW_CCU SG_ 140 ATS_DATC_FrPsBlowerUpDn 0;
BA_ "Version" SG_ 140 ATS_DATC_FrPsBlowerUpDn "19.12.08";
BA_ "Description" SG_ 140 ATS_DATC_FrDrMultiAutoBlower "Àü¼® ¿îÀü¼® Ãø ¸ÖÆ¼¿ÀÅäºí·Î¿ö ¼³Á¤";
BA_ "GenSigSendType" SG_ 140 ATS_DATC_FrDrMultiAutoBlower 4;
BA_ "UserSigValidity" SG_ 140 ATS_DATC_FrDrMultiAutoBlower 3;
BA_REL_ "GenSigTimeoutTime" BU_SG_REL_ CGW_CCU SG_ 140 ATS_DATC_FrDrMultiAutoBlower 0;
BA_ "Version" SG_ 140 ATS_DATC_FrDrMultiAutoBlower "19.12.08";
BA_ "Description" SG_ 140 ATS_DATC_FrPsMultiAutoBlower "Àü¼® Á¶¼ö¼® Ãø ¸ÖÆ¼¿ÀÅäºí·Î¿ö ¼³Á¤";
BA_ "GenSigSendType" SG_ 140 ATS_DATC_FrPsMultiAutoBlower 4;
BA_ "UserSigValidity" SG_ 140 ATS_DATC_FrPsMultiAutoBlower 3;
BA_REL_ "GenSigTimeoutTime" BU_SG_REL_ CGW_CCU SG_ 140 ATS_DATC_FrPsMultiAutoBlower 0;
BA_ "Version" SG_ 140 ATS_DATC_FrPsMultiAutoBlower "19.12.08";
BA_ "Description" SG_ 140 ATS_DATC_RrDrMultiAutoBlower "ÈÄ¼® ¿îÀü¼® Ãø ¸ÖÆ¼¿ÀÅäºí·Î¿ö ¼³Á¤";
BA_ "GenSigSendType" SG_ 140 ATS_DATC_RrDrMultiAutoBlower 4;
BA_ "UserSigValidity" SG_ 140 ATS_DATC_RrDrMultiAutoBlower 3;
BA_REL_ "GenSigTimeoutTime" BU_SG_REL_ CGW_CCU SG_ 140 ATS_DATC_RrDrMultiAutoBlower 0;
BA_ "Version" SG_ 140 ATS_DATC_RrDrMultiAutoBlower "19.12.08";
BA_ "Description" SG_ 140 ATS_DATC_FragranceStrhSet "Fragrance Strength Set (¹ßÇâ ±â´É Çâ ¼¼±â ¼³Á¤)";
BA_ "GenSigSendType" SG_ 140 ATS_DATC_FragranceStrhSet 4;
BA_ "GenSigStartValue" SG_ 140 ATS_DATC_FragranceStrhSet 7;
BA_ "UserSigValidity" SG_ 140 ATS_DATC_FragranceStrhSet 3;
BA_REL_ "GenSigTimeoutTime" BU_SG_REL_ CGW_CCU SG_ 140 ATS_DATC_FragranceStrhSet 0;
BA_ "Version" SG_ 140 ATS_DATC_FragranceStrhSet "20.03.01";
BA_ "Description" SG_ 140 ATS_DATC_FragranceKindSet "Fragrance Kind Set (¹ßÇâ ±â´É Çâ Á¾·ù ¼³Á¤)";
BA_ "GenSigSendType" SG_ 140 ATS_DATC_FragranceKindSet 4;
BA_ "GenSigStartValue" SG_ 140 ATS_DATC_FragranceKindSet 7;
BA_ "UserSigValidity" SG_ 140 ATS_DATC_FragranceKindSet 3;
BA_REL_ "GenSigTimeoutTime" BU_SG_REL_ CGW_CCU SG_ 140 ATS_DATC_FragranceKindSet 0;
BA_ "Version" SG_ 140 ATS_DATC_FragranceKindSet "20.03.01";
BA_ "Description" SG_ 140 ATS_DATC_FragranceBttnMnlSet "Fragrance Button Manual Set (¹ßÇâ ±â´É ¹öÆ° ¼öµ¿ ÀÔ·Â)";
BA_ "GenSigSendType" SG_ 140 ATS_DATC_FragranceBttnMnlSet 4;
BA_ "GenSigStartValue" SG_ 140 ATS_DATC_FragranceBttnMnlSet 3;
BA_ "UserSigValidity" SG_ 140 ATS_DATC_FragranceBttnMnlSet 3;
BA_REL_ "GenSigTimeoutTime" BU_SG_REL_ CGW_CCU SG_ 140 ATS_DATC_FragranceBttnMnlSet 0;
BA_ "Version" SG_ 140 ATS_DATC_FragranceBttnMnlSet "20.03.01";
BA_ "Description" SG_ 140 ATS_DATC_TempUnitSet "Temp Unit Set (¿Âµµ ´ÜÀ§ ¼³Á¤)";
BA_ "GenSigSendType" SG_ 140 ATS_DATC_TempUnitSet 4;
BA_ "GenSigStartValue" SG_ 140 ATS_DATC_TempUnitSet 3;
BA_ "UserSigValidity" SG_ 140 ATS_DATC_TempUnitSet 3;
BA_REL_ "GenSigTimeoutTime" BU_SG_REL_ CGW_CCU SG_ 140 ATS_DATC_TempUnitSet 0;
BA_ "Version" SG_ 140 ATS_DATC_TempUnitSet "20.04.02";
BA_ "GenMsgSendType" BO_ 591 0;
BA_ "Description" SG_ 591 ATS_RLStSldFwdBtn "ÈÄ¼® LH ½½¶óÀÌµù Àü¹æ ÀÌµ¿";
BA_ "GenSigSendType" SG_ 591 ATS_RLStSldFwdBtn 4;
BA_ "UserSigValidity" SG_ 591 ATS_RLStSldFwdBtn 3;
BA_ "NetworkRequest" SG_ 591 ATS_RLStSldFwdBtn 0;
BA_ "NetworkRequestHoldingTime" SG_ 591 ATS_RLStSldFwdBtn 5000;
BA_ "Version" SG_ 591 ATS_RLStSldFwdBtn "19.09.02";
BA_ "Description" SG_ 591 ATS_RLStSldBwdBtn "ÈÄ¼® LH ½½¶óÀÌµù ÈÄ¹æ ÀÌµ¿";
BA_ "GenSigSendType" SG_ 591 ATS_RLStSldBwdBtn 4;
BA_ "UserSigValidity" SG_ 591 ATS_RLStSldBwdBtn 3;
BA_ "NetworkRequest" SG_ 591 ATS_RLStSldBwdBtn 0;
BA_ "NetworkRequestHoldingTime" SG_ 591 ATS_RLStSldBwdBtn 5000;
BA_ "Version" SG_ 591 ATS_RLStSldBwdBtn "19.09.02";
BA_ "Description" SG_ 591 ATS_RLStRclFwdBtn "ÈÄ¼® LH ¸®Å¬¶óÀÌ´× Àü¹æ ÀÌµ¿";
BA_ "GenSigSendType" SG_ 591 ATS_RLStRclFwdBtn 4;
BA_ "UserSigValidity" SG_ 591 ATS_RLStRclFwdBtn 3;
BA_ "NetworkRequest" SG_ 591 ATS_RLStRclFwdBtn 0;
BA_ "NetworkRequestHoldingTime" SG_ 591 ATS_RLStRclFwdBtn 5000;
BA_ "Version" SG_ 591 ATS_RLStRclFwdBtn "19.09.02";
BA_ "Description" SG_ 591 ATS_RLStRclBwdBtn "ÈÄ¼® LH ¸®Å¬¶óÀÌ´× ÈÄ¹æ ÀÌµ¿";
BA_ "GenSigSendType" SG_ 591 ATS_RLStRclBwdBtn 4;
BA_ "UserSigValidity" SG_ 591 ATS_RLStRclBwdBtn 3;
BA_ "NetworkRequest" SG_ 591 ATS_RLStRclBwdBtn 0;
BA_ "NetworkRequestHoldingTime" SG_ 591 ATS_RLStRclBwdBtn 5000;
BA_ "Version" SG_ 591 ATS_RLStRclBwdBtn "19.09.02";
BA_ "Description" SG_ 591 ATS_RLStTltUpBtn "ÈÄ¼® LH Æ¿Æ® ¾÷ ÀÌµ¿";
BA_ "GenSigSendType" SG_ 591 ATS_RLStTltUpBtn 4;
BA_ "UserSigValidity" SG_ 591 ATS_RLStTltUpBtn 3;
BA_ "NetworkRequest" SG_ 591 ATS_RLStTltUpBtn 0;
BA_ "NetworkRequestHoldingTime" SG_ 591 ATS_RLStTltUpBtn 5000;
BA_ "Version" SG_ 591 ATS_RLStTltUpBtn "19.09.02";
BA_ "Description" SG_ 591 ATS_RLStTltDnBtn "ÈÄ¼® LH Æ¿Æ® ´Ù¿î ÀÌµ¿";
BA_ "GenSigSendType" SG_ 591 ATS_RLStTltDnBtn 4;
BA_ "UserSigValidity" SG_ 591 ATS_RLStTltDnBtn 3;
BA_ "NetworkRequest" SG_ 591 ATS_RLStTltDnBtn 0;
BA_ "NetworkRequestHoldingTime" SG_ 591 ATS_RLStTltDnBtn 5000;
BA_ "Version" SG_ 591 ATS_RLStTltDnBtn "19.09.02";
BA_ "Description" SG_ 591 ATS_RLStHRestUpBtn "ÈÄ¼® LH Çìµå·¹½ºÆ® ¾÷ ÀÌµ¿";
BA_ "GenSigSendType" SG_ 591 ATS_RLStHRestUpBtn 4;
BA_ "UserSigValidity" SG_ 591 ATS_RLStHRestUpBtn 3;
BA_ "NetworkRequest" SG_ 591 ATS_RLStHRestUpBtn 0;
BA_ "NetworkRequestHoldingTime" SG_ 591 ATS_RLStHRestUpBtn 5000;
BA_ "Version" SG_ 591 ATS_RLStHRestUpBtn "19.09.02";
BA_ "Description" SG_ 591 ATS_RLStHRestDnBtn "ÈÄ¼® LH Çìµå·¹½ºÆ® ´Ù¿î ÀÌµ¿";
BA_ "GenSigSendType" SG_ 591 ATS_RLStHRestDnBtn 4;
BA_ "UserSigValidity" SG_ 591 ATS_RLStHRestDnBtn 3;
BA_ "NetworkRequest" SG_ 591 ATS_RLStHRestDnBtn 0;
BA_ "NetworkRequestHoldingTime" SG_ 591 ATS_RLStHRestDnBtn 5000;
BA_ "Version" SG_ 591 ATS_RLStHRestDnBtn "19.09.02";
BA_ "Description" SG_ 591 ATS_RLStHRestFwdBtn "ÈÄ¼® LH Çìµå·¹½ºÆ® Àü¹æ ÀÌµ¿";
BA_ "GenSigSendType" SG_ 591 ATS_RLStHRestFwdBtn 4;
BA_ "UserSigValidity" SG_ 591 ATS_RLStHRestFwdBtn 3;
BA_ "NetworkRequest" SG_ 591 ATS_RLStHRestFwdBtn 0;
BA_ "NetworkRequestHoldingTime" SG_ 591 ATS_RLStHRestFwdBtn 5000;
BA_ "Version" SG_ 591 ATS_RLStHRestFwdBtn "19.09.02";
BA_ "Description" SG_ 591 ATS_RLStHRestBwdBtn "ÈÄ¼® LH Çìµå·¹½ºÆ® ÈÄ¹æ ÀÌµ¿";
BA_ "GenSigSendType" SG_ 591 ATS_RLStHRestBwdBtn 4;
BA_ "UserSigValidity" SG_ 591 ATS_RLStHRestBwdBtn 3;
BA_ "NetworkRequest" SG_ 591 ATS_RLStHRestBwdBtn 0;
BA_ "NetworkRequestHoldingTime" SG_ 591 ATS_RLStHRestBwdBtn 5000;
BA_ "Version" SG_ 591 ATS_RLStHRestBwdBtn "19.09.02";
BA_ "Description" SG_ 591 ATS_RLStLegRestUpBtn "ÈÄ¼® LH ·¹±×·¹½ºÆ® UP";
BA_ "GenSigSendType" SG_ 591 ATS_RLStLegRestUpBtn 4;
BA_ "UserSigValidity" SG_ 591 ATS_RLStLegRestUpBtn 3;
BA_ "NetworkRequest" SG_ 591 ATS_RLStLegRestUpBtn 0;
BA_ "NetworkRequestHoldingTime" SG_ 591 ATS_RLStLegRestUpBtn 5000;
BA_ "Version" SG_ 591 ATS_RLStLegRestUpBtn "19.11.09";
BA_ "Description" SG_ 591 ATS_RStLegRestDnBtn "ÈÄ¼® LH ·¹±×·¹½ºÆ® DOWN";
BA_ "GenSigSendType" SG_ 591 ATS_RStLegRestDnBtn 4;
BA_ "UserSigValidity" SG_ 591 ATS_RStLegRestDnBtn 3;
BA_ "NetworkRequest" SG_ 591 ATS_RStLegRestDnBtn 0;
BA_ "NetworkRequestHoldingTime" SG_ 591 ATS_RStLegRestDnBtn 5000;
BA_ "Version" SG_ 591 ATS_RStLegRestDnBtn "19.11.09";
BA_ "Description" SG_ 591 ATS_RLStLegRestExtUpBtn "ÈÄ¼® LH ·¹±×·¹½ºÆ® EXT";
BA_ "GenSigSendType" SG_ 591 ATS_RLStLegRestExtUpBtn 4;
BA_ "UserSigValidity" SG_ 591 ATS_RLStLegRestExtUpBtn 3;
BA_ "NetworkRequest" SG_ 591 ATS_RLStLegRestExtUpBtn 0;
BA_ "NetworkRequestHoldingTime" SG_ 591 ATS_RLStLegRestExtUpBtn 5000;
BA_ "Version" SG_ 591 ATS_RLStLegRestExtUpBtn "19.11.09";
BA_ "Description" SG_ 591 ATS_RLStLegRestExtDnBtn "ÈÄ¼® LH ·¹±×·¹½ºÆ® EXT BWD";
BA_ "GenSigSendType" SG_ 591 ATS_RLStLegRestExtDnBtn 4;
BA_ "UserSigValidity" SG_ 591 ATS_RLStLegRestExtDnBtn 3;
BA_ "NetworkRequest" SG_ 591 ATS_RLStLegRestExtDnBtn 0;
BA_ "NetworkRequestHoldingTime" SG_ 591 ATS_RLStLegRestExtDnBtn 5000;
BA_ "Version" SG_ 591 ATS_RLStLegRestExtDnBtn "19.11.09";
BA_ "Description" SG_ 591 ATS_RLStShoulderADJFwdBtn "ÈÄ¼® LH ¼ñ´õ¾îÁ®½ºÅÍ FWD";
BA_ "GenSigSendType" SG_ 591 ATS_RLStShoulderADJFwdBtn 4;
BA_ "UserSigValidity" SG_ 591 ATS_RLStShoulderADJFwdBtn 3;
BA_ "NetworkRequest" SG_ 591 ATS_RLStShoulderADJFwdBtn 0;
BA_ "NetworkRequestHoldingTime" SG_ 591 ATS_RLStShoulderADJFwdBtn 5000;
BA_ "Version" SG_ 591 ATS_RLStShoulderADJFwdBtn "20.03.02";
BA_ "Description" SG_ 591 ATS_RLStShoulderADJBwdBtn "ÈÄ¼® LH ¼ñ´õ¾îÁ®½ºÅÍ BWD";
BA_ "GenSigSendType" SG_ 591 ATS_RLStShoulderADJBwdBtn 4;
BA_ "UserSigValidity" SG_ 591 ATS_RLStShoulderADJBwdBtn 3;
BA_ "NetworkRequest" SG_ 591 ATS_RLStShoulderADJBwdBtn 0;
BA_ "NetworkRequestHoldingTime" SG_ 591 ATS_RLStShoulderADJBwdBtn 5000;
BA_ "Version" SG_ 591 ATS_RLStShoulderADJBwdBtn "20.03.02";
BA_ "GenMsgSendType" BO_ 607 0;
BA_ "Description" SG_ 607 ATS_RRStSldFwdBtn "ÈÄ¼® RH ½½¶óÀÌµù Àü¹æ ÀÌµ¿";
BA_ "GenSigSendType" SG_ 607 ATS_RRStSldFwdBtn 4;
BA_ "UserSigValidity" SG_ 607 ATS_RRStSldFwdBtn 3;
BA_ "NetworkRequest" SG_ 607 ATS_RRStSldFwdBtn 0;
BA_ "NetworkRequestHoldingTime" SG_ 607 ATS_RRStSldFwdBtn 5000;
BA_ "Version" SG_ 607 ATS_RRStSldFwdBtn "19.09.02";
BA_ "Description" SG_ 607 ATS_RRStSldBwdBtn "ÈÄ¼® RH ½½¶óÀÌµù ÈÄ¹æ ÀÌµ¿";
BA_ "GenSigSendType" SG_ 607 ATS_RRStSldBwdBtn 4;
BA_ "UserSigValidity" SG_ 607 ATS_RRStSldBwdBtn 3;
BA_ "NetworkRequest" SG_ 607 ATS_RRStSldBwdBtn 0;
BA_ "NetworkRequestHoldingTime" SG_ 607 ATS_RRStSldBwdBtn 5000;
BA_ "Version" SG_ 607 ATS_RRStSldBwdBtn "19.09.02";
BA_ "Description" SG_ 607 ATS_RRStRclFwdBtn "ÈÄ¼® RH ¸®Å¬¶óÀÌ´× Àü¹æ ÀÌµ¿";
BA_ "GenSigSendType" SG_ 607 ATS_RRStRclFwdBtn 4;
BA_ "UserSigValidity" SG_ 607 ATS_RRStRclFwdBtn 3;
BA_ "NetworkRequest" SG_ 607 ATS_RRStRclFwdBtn 0;
BA_ "NetworkRequestHoldingTime" SG_ 607 ATS_RRStRclFwdBtn 5000;
BA_ "Version" SG_ 607 ATS_RRStRclFwdBtn "19.09.02";
BA_ "Description" SG_ 607 ATS_RRStRclBwdBtn "ÈÄ¼® RH ¸®Å¬¶óÀÌ´× ÈÄ¹æ ÀÌµ¿";
BA_ "GenSigSendType" SG_ 607 ATS_RRStRclBwdBtn 4;
BA_ "UserSigValidity" SG_ 607 ATS_RRStRclBwdBtn 3;
BA_ "NetworkRequest" SG_ 607 ATS_RRStRclBwdBtn 0;
BA_ "NetworkRequestHoldingTime" SG_ 607 ATS_RRStRclBwdBtn 5000;
BA_ "Version" SG_ 607 ATS_RRStRclBwdBtn "19.09.02";
BA_ "Description" SG_ 607 ATS_RRStTltUpBtn "ÈÄ¼® RH Æ¿Æ® ¾÷ ÀÌµ¿";
BA_ "GenSigSendType" SG_ 607 ATS_RRStTltUpBtn 4;
BA_ "UserSigValidity" SG_ 607 ATS_RRStTltUpBtn 3;
BA_ "NetworkRequest" SG_ 607 ATS_RRStTltUpBtn 0;
BA_ "NetworkRequestHoldingTime" SG_ 607 ATS_RRStTltUpBtn 5000;
BA_ "Version" SG_ 607 ATS_RRStTltUpBtn "19.09.02";
BA_ "Description" SG_ 607 ATS_RRStTltDnBtn "ÈÄ¼® RH Æ¿Æ® ´Ù¿î ÀÌµ¿";
BA_ "GenSigSendType" SG_ 607 ATS_RRStTltDnBtn 4;
BA_ "UserSigValidity" SG_ 607 ATS_RRStTltDnBtn 3;
BA_ "NetworkRequest" SG_ 607 ATS_RRStTltDnBtn 0;
BA_ "NetworkRequestHoldingTime" SG_ 607 ATS_RRStTltDnBtn 5000;
BA_ "Version" SG_ 607 ATS_RRStTltDnBtn "19.09.02";
BA_ "Description" SG_ 607 ATS_RRStLegRestPopBtn "Rear Right Leg Rest Move Pop Up Button";
BA_ "GenSigSendType" SG_ 607 ATS_RRStLegRestPopBtn 4;
BA_ "UserSigValidity" SG_ 607 ATS_RRStLegRestPopBtn 3;
BA_ "NetworkRequest" SG_ 607 ATS_RRStLegRestPopBtn 0;
BA_ "NetworkRequestHoldingTime" SG_ 607 ATS_RRStLegRestPopBtn 5000;
BA_ "Version" SG_ 607 ATS_RRStLegRestPopBtn "20.07.01";
BA_ "Description" SG_ 607 ATS_RRStFRestPopBtn "Rear Right Foot Rest Move Pop Up Button";
BA_ "GenSigSendType" SG_ 607 ATS_RRStFRestPopBtn 4;
BA_ "UserSigValidity" SG_ 607 ATS_RRStFRestPopBtn 3;
BA_ "NetworkRequest" SG_ 607 ATS_RRStFRestPopBtn 0;
BA_ "NetworkRequestHoldingTime" SG_ 607 ATS_RRStFRestPopBtn 5000;
BA_ "Version" SG_ 607 ATS_RRStFRestPopBtn "20.07.01";
BA_ "Description" SG_ 607 ATS_RRStAstPopBtn "Rear Right Assist Seat Move Pop Up Button";
BA_ "GenSigSendType" SG_ 607 ATS_RRStAstPopBtn 4;
BA_ "UserSigValidity" SG_ 607 ATS_RRStAstPopBtn 3;
BA_ "NetworkRequest" SG_ 607 ATS_RRStAstPopBtn 0;
BA_ "NetworkRequestHoldingTime" SG_ 607 ATS_RRStAstPopBtn 5000;
BA_ "Version" SG_ 607 ATS_RRStAstPopBtn "20.07.01";
BA_ "Description" SG_ 607 ATS_RRFauCondiBtn "Rear Right FAU Operational Condition Move Button";
BA_ "GenSigSendType" SG_ 607 ATS_RRFauCondiBtn 4;
BA_ "UserSigValidity" SG_ 607 ATS_RRFauCondiBtn 3;
BA_ "NetworkRequest" SG_ 607 ATS_RRFauCondiBtn 0;
BA_ "NetworkRequestHoldingTime" SG_ 607 ATS_RRFauCondiBtn 5000;
BA_ "Version" SG_ 607 ATS_RRFauCondiBtn "20.07.01";
BA_ "Description" SG_ 607 ATS_RRStHRestUpBtn "ÈÄ¼® RH Çìµå·¹½ºÆ® ¾÷ ÀÌµ¿";
BA_ "GenSigSendType" SG_ 607 ATS_RRStHRestUpBtn 4;
BA_ "UserSigValidity" SG_ 607 ATS_RRStHRestUpBtn 3;
BA_ "NetworkRequest" SG_ 607 ATS_RRStHRestUpBtn 0;
BA_ "NetworkRequestHoldingTime" SG_ 607 ATS_RRStHRestUpBtn 5000;
BA_ "Version" SG_ 607 ATS_RRStHRestUpBtn "19.09.02";
BA_ "Description" SG_ 607 ATS_RRStHRestDnBtn "ÈÄ¼® RH Çìµå·¹½ºÆ® ´Ù¿î ÀÌµ¿";
BA_ "GenSigSendType" SG_ 607 ATS_RRStHRestDnBtn 4;
BA_ "UserSigValidity" SG_ 607 ATS_RRStHRestDnBtn 3;
BA_ "NetworkRequest" SG_ 607 ATS_RRStHRestDnBtn 0;
BA_ "NetworkRequestHoldingTime" SG_ 607 ATS_RRStHRestDnBtn 5000;
BA_ "Version" SG_ 607 ATS_RRStHRestDnBtn "19.09.02";
BA_ "Description" SG_ 607 ATS_RRStHRestFwdBtn "ÈÄ¼® RH Çìµå·¹½ºÆ® Àü¹æ ÀÌµ¿";
BA_ "GenSigSendType" SG_ 607 ATS_RRStHRestFwdBtn 4;
BA_ "UserSigValidity" SG_ 607 ATS_RRStHRestFwdBtn 3;
BA_ "NetworkRequest" SG_ 607 ATS_RRStHRestFwdBtn 0;
BA_ "NetworkRequestHoldingTime" SG_ 607 ATS_RRStHRestFwdBtn 5000;
BA_ "Version" SG_ 607 ATS_RRStHRestFwdBtn "19.09.02";
BA_ "Description" SG_ 607 ATS_RRStHRestBwdBtn "ÈÄ¼® RH Çìµå·¹½ºÆ® ÈÄ¹æ ÀÌµ¿";
BA_ "GenSigSendType" SG_ 607 ATS_RRStHRestBwdBtn 4;
BA_ "UserSigValidity" SG_ 607 ATS_RRStHRestBwdBtn 3;
BA_ "NetworkRequest" SG_ 607 ATS_RRStHRestBwdBtn 0;
BA_ "NetworkRequestHoldingTime" SG_ 607 ATS_RRStHRestBwdBtn 5000;
BA_ "Version" SG_ 607 ATS_RRStHRestBwdBtn "19.09.02";
BA_ "Description" SG_ 607 ATS_RRStShoulderADJFwdBtn "ÈÄ¼® RH ¼ñ´õ¾îÁ®½ºÅÍ FWD ÀÌµ¿";
BA_ "GenSigSendType" SG_ 607 ATS_RRStShoulderADJFwdBtn 4;
BA_ "UserSigValidity" SG_ 607 ATS_RRStShoulderADJFwdBtn 3;
BA_ "NetworkRequest" SG_ 607 ATS_RRStShoulderADJFwdBtn 0;
BA_ "NetworkRequestHoldingTime" SG_ 607 ATS_RRStShoulderADJFwdBtn 5000;
BA_ "Version" SG_ 607 ATS_RRStShoulderADJFwdBtn "20.03.02";
BA_ "Description" SG_ 607 ATS_RRStShoulderADJBwdBtn "ÈÄ¼® RH ¼ñ´õ¾îÁ®½ºÅÍ BWD ÀÌµ¿";
BA_ "GenSigSendType" SG_ 607 ATS_RRStShoulderADJBwdBtn 4;
BA_ "UserSigValidity" SG_ 607 ATS_RRStShoulderADJBwdBtn 3;
BA_ "NetworkRequest" SG_ 607 ATS_RRStShoulderADJBwdBtn 0;
BA_ "NetworkRequestHoldingTime" SG_ 607 ATS_RRStShoulderADJBwdBtn 5000;
BA_ "Version" SG_ 607 ATS_RRStShoulderADJBwdBtn "20.03.02";
BA_ "Description" SG_ 607 ATS_RRStLegRestUpBtn "ÈÄ¼® RH ·¹±×·¹½ºÆ® ¾÷ ÀÌµ¿";
BA_ "GenSigSendType" SG_ 607 ATS_RRStLegRestUpBtn 4;
BA_ "UserSigValidity" SG_ 607 ATS_RRStLegRestUpBtn 3;
BA_ "NetworkRequest" SG_ 607 ATS_RRStLegRestUpBtn 0;
BA_ "NetworkRequestHoldingTime" SG_ 607 ATS_RRStLegRestUpBtn 5000;
BA_ "Version" SG_ 607 ATS_RRStLegRestUpBtn "19.09.02";
BA_ "Description" SG_ 607 ATS_RRStLegRestDnBtn "ÈÄ¼® RH ·¹±×·¹½ºÆ® ´Ù¿î ÀÌµ¿";
BA_ "GenSigSendType" SG_ 607 ATS_RRStLegRestDnBtn 4;
BA_ "UserSigValidity" SG_ 607 ATS_RRStLegRestDnBtn 3;
BA_ "NetworkRequest" SG_ 607 ATS_RRStLegRestDnBtn 0;
BA_ "NetworkRequestHoldingTime" SG_ 607 ATS_RRStLegRestDnBtn 5000;
BA_ "Version" SG_ 607 ATS_RRStLegRestDnBtn "19.09.02";
BA_ "Description" SG_ 607 ATS_RRStLegRestExtUpBtn "ÈÄ¼® RH ·¹±×·¹½ºÆ® Àü¹æ ÀÍ½ºÅÙ¼Ç ÀÌµ¿";
BA_ "GenSigSendType" SG_ 607 ATS_RRStLegRestExtUpBtn 4;
BA_ "UserSigValidity" SG_ 607 ATS_RRStLegRestExtUpBtn 3;
BA_ "NetworkRequest" SG_ 607 ATS_RRStLegRestExtUpBtn 0;
BA_ "NetworkRequestHoldingTime" SG_ 607 ATS_RRStLegRestExtUpBtn 5000;
BA_ "Version" SG_ 607 ATS_RRStLegRestExtUpBtn "19.09.02";
BA_ "Description" SG_ 607 ATS_RRStLegRestExtDnBtn "ÈÄ¼® RH ·¹±×·¹½ºÆ® ÈÄ¹æ ÀÍ½ºÅÙ¼Ç ÀÌµ¿";
BA_ "GenSigSendType" SG_ 607 ATS_RRStLegRestExtDnBtn 4;
BA_ "UserSigValidity" SG_ 607 ATS_RRStLegRestExtDnBtn 3;
BA_ "NetworkRequest" SG_ 607 ATS_RRStLegRestExtDnBtn 0;
BA_ "NetworkRequestHoldingTime" SG_ 607 ATS_RRStLegRestExtDnBtn 5000;
BA_ "Version" SG_ 607 ATS_RRStLegRestExtDnBtn "19.09.02";
BA_ "GenMsgCycleTime" BO_ 1216 0;
BA_ "Description" SG_ 1216 BCM_Crc1Val "The data area for CRC calculation is based on the data length (DLC) of the message DB.

The CRC shall be calculated over the entire data block (excluding the CRC bytes) including the user data, alive counter and Data ID 

 

- CRC Polynomial (0x1D) , Initial Value : 0x00, XOR value : 0xFF, Data ID Mode : Both, Data ID : Message ID + 0xF800 

- The initial value is for CRC calculation and the message should be sent with the calculated result value. 

The mathematical expression to 8 bit CRC polynomial is given here. G(x) = x8 + x4 + x3 + x2 + 1";
BA_ "GenSigSendType" SG_ 1216 BCM_Crc1Val 4;
BA_ "GenSigStartValue" SG_ 1216 BCM_Crc1Val 255;
BA_ "UserSigValidity" SG_ 1216 BCM_Crc1Val 0;
BA_ "Version" SG_ 1216 BCM_Crc1Val "18.11.08";
BA_ "Description" SG_ 1216 BCM_AlvCnt1Val "For the first transmission request for a data element the counter shall be initialized with 0 and shall be incremented by 1

for every subsequent send request. When the counter reaches the maximum value(0xE), then it shall restart with 0 for the next send request";
BA_ "GenSigSendType" SG_ 1216 BCM_AlvCnt1Val 4;
BA_ "UserSigValidity" SG_ 1216 BCM_AlvCnt1Val 0;
BA_ "Version" SG_ 1216 BCM_AlvCnt1Val "18.11.08";
BA_ "Description" SG_ 1216 PHEV_FuelDrReleaseSwSta "- Fuel Filler Door Release SW";
BA_ "GenSigSendType" SG_ 1216 PHEV_FuelDrReleaseSwSta 4;
BA_ "UserSigValidity" SG_ 1216 PHEV_FuelDrReleaseSwSta 0;
BA_ "NetworkRequest" SG_ 1216 PHEV_FuelDrReleaseSwSta 0;
BA_ "NetworkRequestHoldingTime" SG_ 1216 PHEV_FuelDrReleaseSwSta 5000;
BA_ "Version" SG_ 1216 PHEV_FuelDrReleaseSwSta "17.12.00";
BA_ "Description" SG_ 1216 StrWhlWrmr_MKBDBpReq "Steering Wheel Warmer Switch Beep Command";
BA_ "GenSigSendType" SG_ 1216 StrWhlWrmr_MKBDBpReq 4;
BA_ "UserSigValidity" SG_ 1216 StrWhlWrmr_MKBDBpReq 0;
BA_ "NetworkRequest" SG_ 1216 StrWhlWrmr_MKBDBpReq 0;
BA_ "NetworkRequestHoldingTime" SG_ 1216 StrWhlWrmr_MKBDBpReq 5000;
BA_ "Version" SG_ 1216 StrWhlWrmr_MKBDBpReq "20.08.02";
BA_ "Description" SG_ 1216 BckGls_RrGlsHtdMKBDBpReq "Rear Defogger Switch Beep Request";
BA_ "GenSigSendType" SG_ 1216 BckGls_RrGlsHtdMKBDBpReq 4;
BA_ "UserSigValidity" SG_ 1216 BckGls_RrGlsHtdMKBDBpReq 0;
BA_ "NetworkRequest" SG_ 1216 BckGls_RrGlsHtdMKBDBpReq 0;
BA_ "NetworkRequestHoldingTime" SG_ 1216 BckGls_RrGlsHtdMKBDBpReq 5000;
BA_ "Version" SG_ 1216 BckGls_RrGlsHtdMKBDBpReq "20.08.02";
BA_ "Description" SG_ 1216 Wndshld_FrtGlsHtdMKBDBpReq "Front Heated Glass Switch Beep Request";
BA_ "GenSigSendType" SG_ 1216 Wndshld_FrtGlsHtdMKBDBpReq 4;
BA_ "UserSigValidity" SG_ 1216 Wndshld_FrtGlsHtdMKBDBpReq 0;
BA_ "NetworkRequest" SG_ 1216 Wndshld_FrtGlsHtdMKBDBpReq 0;
BA_ "NetworkRequestHoldingTime" SG_ 1216 Wndshld_FrtGlsHtdMKBDBpReq 5000;
BA_ "Version" SG_ 1216 Wndshld_FrtGlsHtdMKBDBpReq "20.08.02";
BA_ "Description" SG_ 1216 BAlarm_AutoLockrReq "-Lock request by Auto Locking

 (BurglarAlarmFunction)";
BA_ "GenSigSendType" SG_ 1216 BAlarm_AutoLockrReq 4;
BA_ "UserSigValidity" SG_ 1216 BAlarm_AutoLockrReq 0;
BA_ "NetworkRequest" SG_ 1216 BAlarm_AutoLockrReq 0;
BA_ "NetworkRequestHoldingTime" SG_ 1216 BAlarm_AutoLockrReq 5000;
BA_ "Version" SG_ 1216 BAlarm_AutoLockrReq "17.12.00";
BA_ "Description" SG_ 1216 TiltTele_SmrtIMSDBNum "Smart IMS DB Number Information";
BA_ "GenSigSendType" SG_ 1216 TiltTele_SmrtIMSDBNum 4;
BA_ "UserSigValidity" SG_ 1216 TiltTele_SmrtIMSDBNum 0;
BA_REL_ "GenSigTimeoutTime" BU_SG_REL_ SCM SG_ 1216 TiltTele_SmrtIMSDBNum 0;
BA_ "NetworkRequest" SG_ 1216 TiltTele_SmrtIMSDBNum 0;
BA_ "NetworkRequestHoldingTime" SG_ 1216 TiltTele_SmrtIMSDBNum 5000;
BA_ "Version" SG_ 1216 TiltTele_SmrtIMSDBNum "20.08.02";
BA_ "Description" SG_ 1216 Tilt_IMSMemoryCmd "Command for IMS Memory";
BA_ "GenSigSendType" SG_ 1216 Tilt_IMSMemoryCmd 4;
BA_ "UserSigValidity" SG_ 1216 Tilt_IMSMemoryCmd 0;
BA_REL_ "GenSigTimeoutTime" BU_SG_REL_ SCM SG_ 1216 Tilt_IMSMemoryCmd 0;
BA_ "NetworkRequest" SG_ 1216 Tilt_IMSMemoryCmd 0;
BA_ "NetworkRequestHoldingTime" SG_ 1216 Tilt_IMSMemoryCmd 5000;
BA_ "Version" SG_ 1216 Tilt_IMSMemoryCmd "20.08.07";
BA_ "Description" SG_ 1216 Tele_IMSMemoryCmd "Command for IMS Memory";
BA_ "GenSigSendType" SG_ 1216 Tele_IMSMemoryCmd 4;
BA_ "UserSigValidity" SG_ 1216 Tele_IMSMemoryCmd 0;
BA_REL_ "GenSigTimeoutTime" BU_SG_REL_ SCM SG_ 1216 Tele_IMSMemoryCmd 0;
BA_ "NetworkRequest" SG_ 1216 Tele_IMSMemoryCmd 0;
BA_ "NetworkRequestHoldingTime" SG_ 1216 Tele_IMSMemoryCmd 5000;
BA_ "Version" SG_ 1216 Tele_IMSMemoryCmd "20.08.07";
BA_ "GenMsgSendType" BO_ 2357404929 0;
BA_ "GenMsgCycleTimeFast" BO_ 2357404929 0;
BA_ "GenMsgNrOfRepetition" BO_ 2357404929 0;
BA_ "VFrameFormat" BO_ 2357404929 1;
BA_ "Description" SG_ 2357404929 BMS_Crc6Val "The data area for CRC calculation is based on the data length (DLC) of the message DB.

The CRC shall be calculated over the entire data block (excluding the CRC bytes) including the user data, alive counter and Data ID

 

- CRC Polynomial (0x1021) , Initial Value : 0xFFFF, XOR value : 0x0000, Data ID : Message ID + 0xF800 

- The initial value is for CRC calculation and the message should be sent with the calculated result value. 

- The mathematical expression to 16 bit CRC polynomial is given here. G(x) = x16 + x12 + x5 + 1";
BA_ "GenSigStartValue" SG_ 2357404929 BMS_Crc6Val 65535;
BA_ "UserSigValidity" SG_ 2357404929 BMS_Crc6Val 3;
BA_ "RoutingFactor" SG_ 2357404929 BMS_Crc6Val 2;
BA_ "Version" SG_ 2357404929 BMS_Crc6Val "18.11.08";
BA_ "Description" SG_ 2357404929 BMS_AlvCnt6Val "For the first transmission request for a data element the counter shall be initialized with 0 and shall be incremented by 1 for every subsequent send request. 

When the counter reaches the maximum value(0xFF), then it shall restart with 0 for the next send request";
BA_ "UserSigValidity" SG_ 2357404929 BMS_AlvCnt6Val 5;
BA_ "RoutingFactor" SG_ 2357404929 BMS_AlvCnt6Val 2;
BA_ "Version" SG_ 2357404929 BMS_AlvCnt6Val "18.11.08";
BA_ "Description" SG_ 2357404929 CHRG_StndChrgConnSta_120V "Standard Charging(120V) Connector Status  (CF_Bms_StdCha_120V)";
BA_ "UserSigValidity" SG_ 2357404929 CHRG_StndChrgConnSta_120V 7;
BA_ "RoutingFactor" SG_ 2357404929 CHRG_StndChrgConnSta_120V 2;
BA_ "Version" SG_ 2357404929 CHRG_StndChrgConnSta_120V "18.08.07";
BA_ "Description" SG_ 2357404929 CHRG_StndChrgSta "BMS sets this Flag when Battery is standard mode charging (CF_Bms_StdCha)";
BA_ "UserSigValidity" SG_ 2357404929 CHRG_StndChrgSta 7;
BA_ "RoutingFactor" SG_ 2357404929 CHRG_StndChrgSta 2;
BA_ "Version" SG_ 2357404929 CHRG_StndChrgSta "18.08.07";
BA_ "Description" SG_ 2357404929 CHRG_ChrgCycStrtSta "Charging Cycle Start (CF_Bms_Charging_ST)";
BA_ "UserSigValidity" SG_ 2357404929 CHRG_ChrgCycStrtSta 7;
BA_ "RoutingFactor" SG_ 2357404929 CHRG_ChrgCycStrtSta 2;
BA_ "Version" SG_ 2357404929 CHRG_ChrgCycStrtSta "18.08.07";
BA_ "Description" SG_ 2357404929 CHRG_FulChrgSta "0:None, 1:Fully Charged";
BA_ "UserSigValidity" SG_ 2357404929 CHRG_FulChrgSta 7;
BA_ "RoutingFactor" SG_ 2357404929 CHRG_FulChrgSta 2;
BA_ "Version" SG_ 2357404929 CHRG_FulChrgSta "18.08.07";
BA_ "Description" SG_ 2357404929 CHRG_ChrgSta "0:None, 1:Charging";
BA_ "UserSigValidity" SG_ 2357404929 CHRG_ChrgSta 7;
BA_REL_ "GenSigTimeoutTime" BU_SG_REL_ SWRC SG_ 2357404929 CHRG_ChrgSta 1500;
BA_ "RoutingFactor" SG_ 2357404929 CHRG_ChrgSta 2;
BA_ "Version" SG_ 2357404929 CHRG_ChrgSta "18.08.07";
BA_ "Description" SG_ 2357404929 CHRG_SpplmntChrgSta "Supplementary Charge Status (CF_Bms_SupplyChgStat)";
BA_ "UserSigValidity" SG_ 2357404929 CHRG_SpplmntChrgSta 7;
BA_ "RoutingFactor" SG_ 2357404929 CHRG_SpplmntChrgSta 2;
BA_ "Version" SG_ 2357404929 CHRG_SpplmntChrgSta "18.08.07";
BA_ "Description" SG_ 2357404929 CHRG_LdcInhbtReq "LDC Output Inhibit request";
BA_ "UserSigValidity" SG_ 2357404929 CHRG_LdcInhbtReq 7;
BA_ "RoutingFactor" SG_ 2357404929 CHRG_LdcInhbtReq 2;
BA_ "Version" SG_ 2357404929 CHRG_LdcInhbtReq "18.08.07";
BA_ "Description" SG_ 2357404929 CHRG_NorChgFnshSta "CHRG_ChargeNormalFinishConditionStatus (CF_BMS_ChgFinished)";
BA_ "UserSigValidity" SG_ 2357404929 CHRG_NorChgFnshSta 7;
BA_ "RoutingFactor" SG_ 2357404929 CHRG_NorChgFnshSta 2;
BA_ "Version" SG_ 2357404929 CHRG_NorChgFnshSta "18.08.07";
BA_ "Description" SG_ 2357404929 CHRG_ChrgFnshSta "Standard Charge finish flag (CF_BMS_ChgFinished)";
BA_ "UserSigValidity" SG_ 2357404929 CHRG_ChrgFnshSta 7;
BA_ "RoutingFactor" SG_ 2357404929 CHRG_ChrgFnshSta 2;
BA_ "Version" SG_ 2357404929 CHRG_ChrgFnshSta "18.08.07";
BA_ "Description" SG_ 2357404929 CHRG_Ig3RlyOffReq "IG3 Rly Off Requset";
BA_ "UserSigValidity" SG_ 2357404929 CHRG_Ig3RlyOffReq 7;
BA_ "RoutingFactor" SG_ 2357404929 CHRG_Ig3RlyOffReq 2;
BA_ "Version" SG_ 2357404929 CHRG_Ig3RlyOffReq "17.11.00";
BA_ "Description" SG_ 2357404929 CHRG_PShftChgSta "The Flag To Change P Shift";
BA_ "UserSigValidity" SG_ 2357404929 CHRG_PShftChgSta 7;
BA_ "RoutingFactor" SG_ 2357404929 CHRG_PShftChgSta 2;
BA_ "Version" SG_ 2357404929 CHRG_PShftChgSta "17.11.00";
BA_ "Description" SG_ 2357404929 CHRG_PilotFlSta "Notify Pilotline Fail To Cluster (CF_Bms_Notify_Pilotfail)";
BA_ "UserSigValidity" SG_ 2357404929 CHRG_PilotFlSta 7;
BA_ "RoutingFactor" SG_ 2357404929 CHRG_PilotFlSta 2;
BA_ "Version" SG_ 2357404929 CHRG_PilotFlSta "18.08.07";
BA_ "Description" SG_ 2357404929 CHRG_ObcCmdCurrVal "CC target current command (CR_Bms_ObcCmdCurrt_A)";
BA_ "UserSigValidity" SG_ 2357404929 CHRG_ObcCmdCurrVal 7;
BA_ "RoutingFactor" SG_ 2357404929 CHRG_ObcCmdCurrVal 2;
BA_ "Version" SG_ 2357404929 CHRG_ObcCmdCurrVal "18.08.07";
BA_ "GenMsgSendType" BO_ 2357404930 0;
BA_ "GenMsgCycleTimeFast" BO_ 2357404930 0;
BA_ "GenMsgNrOfRepetition" BO_ 2357404930 0;
BA_ "VFrameFormat" BO_ 2357404930 1;
BA_ "Description" SG_ 2357404930 CHRG_StndChrgRmnTimeVal "Standard Charging remained time (CR_Bms_ScChgRemainedTime_min)";
BA_ "UserSigValidity" SG_ 2357404930 CHRG_StndChrgRmnTimeVal 7;
BA_ "RoutingFactor" SG_ 2357404930 CHRG_StndChrgRmnTimeVal 2;
BA_ "Version" SG_ 2357404930 CHRG_StndChrgRmnTimeVal "18.08.07";
BA_ "Description" SG_ 2357404930 CHRG_ChrgRmnTimeVal "Charging remained time (CR_Bms_ChgRemainedTime_min)";
BA_ "UserSigValidity" SG_ 2357404930 CHRG_ChrgRmnTimeVal 7;
BA_ "RoutingFactor" SG_ 2357404930 CHRG_ChrgRmnTimeVal 2;
BA_ "Version" SG_ 2357404930 CHRG_ChrgRmnTimeVal "18.08.07";
BA_ "Description" SG_ 2357404930 CHRG_ObcRlyOnSta "OBC Relay ON status :0x0:Off, 0x1:On";
BA_ "UserSigValidity" SG_ 2357404930 CHRG_ObcRlyOnSta 7;
BA_ "RoutingFactor" SG_ 2357404930 CHRG_ObcRlyOnSta 2;
BA_ "Version" SG_ 2357404930 CHRG_ObcRlyOnSta "18.08.07";
BA_ "Description" SG_ 2357404930 CHRG_NrmlOpSta "BMS Normal Operation Flag

 <Signal Value Table>

 * Normal operation: 0¡æ1¡æ0¡æ1¡æ... (repetitive change 0¡ê1)

 * Abnormal operation: 0 or 1 fixed";
BA_ "UserSigValidity" SG_ 2357404930 CHRG_NrmlOpSta 7;
BA_ "RoutingFactor" SG_ 2357404930 CHRG_NrmlOpSta 2;
BA_ "Version" SG_ 2357404930 CHRG_NrmlOpSta "17.11.00";
BA_ "Description" SG_ 2357404930 CHRG_ChgLamp_1EA "Charging Lamp Request (1EA Lamp)";
BA_ "UserSigValidity" SG_ 2357404930 CHRG_ChgLamp_1EA 7;
BA_ "RoutingFactor" SG_ 2357404930 CHRG_ChgLamp_1EA 2;
BA_ "Version" SG_ 2357404930 CHRG_ChgLamp_1EA "18.08.07";
BA_ "Description" SG_ 2357404930 CHRG_ObcCmdVoltVal "CV target voltage command (CR_Bms_ObcCmdVolt_V)";
BA_ "UserSigValidity" SG_ 2357404930 CHRG_ObcCmdVoltVal 7;
BA_ "RoutingFactor" SG_ 2357404930 CHRG_ObcCmdVoltVal 2;
BA_ "Version" SG_ 2357404930 CHRG_ObcCmdVoltVal "18.08.07";
BA_ "Description" SG_ 2357404930 CHRG_ObcMainVoltVal "The Mains Voltage of OBC



¡Ø Start Value : Physical value";
BA_ "UserSigValidity" SG_ 2357404930 CHRG_ObcMainVoltVal 7;
BA_ "RoutingFactor" SG_ 2357404930 CHRG_ObcMainVoltVal 2;
BA_ "Version" SG_ 2357404930 CHRG_ObcMainVoltVal "17.11.00";
BA_ "GenMsgSendType" BO_ 2357404931 0;
BA_ "GenMsgCycleTimeFast" BO_ 2357404931 0;
BA_ "GenMsgNrOfRepetition" BO_ 2357404931 0;
BA_ "VFrameFormat" BO_ 2357404931 1;
BA_ "Description" SG_ 2357404931 CHRG_StndChrgRmnTime120Val "Standard Charging(120V) Remained Time (CR_Bms_ScChgRemainedTime_120V)";
BA_ "UserSigValidity" SG_ 2357404931 CHRG_StndChrgRmnTime120Val 7;
BA_ "RoutingFactor" SG_ 2357404931 CHRG_StndChrgRmnTime120Val 2;
BA_ "Version" SG_ 2357404931 CHRG_StndChrgRmnTime120Val "18.08.07";
BA_ "Description" SG_ 2357404931 CHRG_StndChrgRmnTime240Val "Standard Charging(240V) Remained Time";
BA_ "UserSigValidity" SG_ 2357404931 CHRG_StndChrgRmnTime240Val 7;
BA_ "RoutingFactor" SG_ 2357404931 CHRG_StndChrgRmnTime240Val 2;
BA_ "Version" SG_ 2357404931 CHRG_StndChrgRmnTime240Val "17.11.00";
BA_ "Description" SG_ 2357404931 CHRG_ObcOutCurrVal "The OutCurrent Of Obc 



¡Ø Start Value : Physical value";
BA_ "UserSigValidity" SG_ 2357404931 CHRG_ObcOutCurrVal 7;
BA_ "RoutingFactor" SG_ 2357404931 CHRG_ObcOutCurrVal 2;
BA_ "Version" SG_ 2357404931 CHRG_ObcOutCurrVal "17.11.00";
BA_ "Description" SG_ 2357404931 CHRG_DomStndChrgRmnTimeVal "Standard Charging Remained Time-ICCB Domestic";
BA_ "UserSigValidity" SG_ 2357404931 CHRG_DomStndChrgRmnTimeVal 7;
BA_ "RoutingFactor" SG_ 2357404931 CHRG_DomStndChrgRmnTimeVal 2;
BA_ "Version" SG_ 2357404931 CHRG_DomStndChrgRmnTimeVal "17.11.00";
BA_ "Description" SG_ 2357404931 CHRG_ChrgFltSubCodVal "Charging Diagnosis Sub Code";
BA_ "UserSigValidity" SG_ 2357404931 CHRG_ChrgFltSubCodVal 7;
BA_ "RoutingFactor" SG_ 2357404931 CHRG_ChrgFltSubCodVal 2;
BA_ "Version" SG_ 2357404931 CHRG_ChrgFltSubCodVal "17.11.00";
BA_ "GenMsgSendType" BO_ 2357404932 0;
BA_ "GenMsgCycleTimeFast" BO_ 2357404932 0;
BA_ "GenMsgNrOfRepetition" BO_ 2357404932 0;
BA_ "VFrameFormat" BO_ 2357404932 1;
BA_ "Description" SG_ 2357404932 CHRG_ScChgTrgtSocVal "CHRG_Target State Of ScChargeValue (CR_Bms_ScChgTagetSoc)";
BA_ "UserSigValidity" SG_ 2357404932 CHRG_ScChgTrgtSocVal 7;
BA_ "RoutingFactor" SG_ 2357404932 CHRG_ScChgTrgtSocVal 2;
BA_ "Version" SG_ 2357404932 CHRG_ScChgTrgtSocVal "19.01.00";
BA_ "Description" SG_ 2357404932 CHRG_RealStndChrgRmnTimeVal "Standard Charging Remained Time - Real Calculation Time";
BA_ "UserSigValidity" SG_ 2357404932 CHRG_RealStndChrgRmnTimeVal 7;
BA_ "RoutingFactor" SG_ 2357404932 CHRG_RealStndChrgRmnTimeVal 2;
BA_ "Version" SG_ 2357404932 CHRG_RealStndChrgRmnTimeVal "17.11.00";
BA_ "Description" SG_ 2357404932 PHEV_EstChrgRmnTimeVal "Remained Charging Estmate Time for Low Cost Charging";
BA_ "UserSigValidity" SG_ 2357404932 PHEV_EstChrgRmnTimeVal 7;
BA_ "RoutingFactor" SG_ 2357404932 PHEV_EstChrgRmnTimeVal 2;
BA_ "Version" SG_ 2357404932 PHEV_EstChrgRmnTimeVal "17.11.00";
BA_ "Description" SG_ 2357404932 CHRG_ChrgLmp_3EA "CHRG_Charge Lamp(3EA Lamp)";
BA_ "UserSigValidity" SG_ 2357404932 CHRG_ChrgLmp_3EA 7;
BA_ "RoutingFactor" SG_ 2357404932 CHRG_ChrgLmp_3EA 2;
BA_ "Version" SG_ 2357404932 CHRG_ChrgLmp_3EA "18.08.07";
BA_ "Description" SG_ 2357404932 CHRG_EuroStndChrgRmnTimeVal "Standard Charging Remained Time-ICCB Europe";
BA_ "UserSigValidity" SG_ 2357404932 CHRG_EuroStndChrgRmnTimeVal 7;
BA_ "RoutingFactor" SG_ 2357404932 CHRG_EuroStndChrgRmnTimeVal 2;
BA_ "Version" SG_ 2357404932 CHRG_EuroStndChrgRmnTimeVal "17.11.00";
BA_ "GenMsgSendType" BO_ 1079 0;
BA_ "Description" SG_ 1079 CTM_TrailerAct "This signal is used for control the Trailer Act function.";
BA_ "GenSigSendType" SG_ 1079 CTM_TrailerAct 4;
BA_ "UserSigValidity" SG_ 1079 CTM_TrailerAct 3;
BA_REL_ "GenSigTimeoutTime" BU_SG_REL_ BLTN_CAM SG_ 1079 CTM_TrailerAct 1500;
BA_ "NetworkRequest" SG_ 1079 CTM_TrailerAct 0;
BA_ "Version" SG_ 1079 CTM_TrailerAct "18.04.01";
BA_ "Description" SG_ 1079 CTM_ExtTailLmpLftOpnSta "Trailer Exterior Tail Lamp Left OpenStatus";
BA_ "GenSigSendType" SG_ 1079 CTM_ExtTailLmpLftOpnSta 4;
BA_ "UserSigValidity" SG_ 1079 CTM_ExtTailLmpLftOpnSta 3;
BA_ "NetworkRequest" SG_ 1079 CTM_ExtTailLmpLftOpnSta 0;
BA_ "Version" SG_ 1079 CTM_ExtTailLmpLftOpnSta "18.10.07";
BA_ "Description" SG_ 1079 CTM_ExtTailLmpRtOpnSta "Trailer Exterior Tail Lamp Right OpenStatus";
BA_ "GenSigSendType" SG_ 1079 CTM_ExtTailLmpRtOpnSta 4;
BA_ "UserSigValidity" SG_ 1079 CTM_ExtTailLmpRtOpnSta 3;
BA_ "NetworkRequest" SG_ 1079 CTM_ExtTailLmpRtOpnSta 0;
BA_ "Version" SG_ 1079 CTM_ExtTailLmpRtOpnSta "18.10.07";
BA_ "Description" SG_ 1079 CTM_Exra_EbrakSta "Trailer Ebrake Controller ActiveStatus";
BA_ "GenSigSendType" SG_ 1079 CTM_Exra_EbrakSta 4;
BA_ "UserSigValidity" SG_ 1079 CTM_Exra_EbrakSta 0;
BA_ "Version" SG_ 1079 CTM_Exra_EbrakSta "21.06.10";
BA_ "Description" SG_ 1079 CTM_RearfogAct "This signal is used for display the rear fog lamp mounted on the trailer.";
BA_ "GenSigSendType" SG_ 1079 CTM_RearfogAct 4;
BA_ "UserSigValidity" SG_ 1079 CTM_RearfogAct 3;
BA_ "NetworkRequest" SG_ 1079 CTM_RearfogAct 0;
BA_ "Version" SG_ 1079 CTM_RearfogAct "18.10.07";
BA_ "Description" SG_ 1079 CTM_StpLmpOpnSta "Trailer Stop Lamp OpenStatus";
BA_ "GenSigSendType" SG_ 1079 CTM_StpLmpOpnSta 4;
BA_ "UserSigValidity" SG_ 1079 CTM_StpLmpOpnSta 3;
BA_ "NetworkRequest" SG_ 1079 CTM_StpLmpOpnSta 0;
BA_ "Version" SG_ 1079 CTM_StpLmpOpnSta "18.10.07";
BA_ "Description" SG_ 1079 CTM_TrnSigLmpLftOpnSta "Trailer T/SIG Lamp Left OpenStatus";
BA_ "GenSigSendType" SG_ 1079 CTM_TrnSigLmpLftOpnSta 4;
BA_ "UserSigValidity" SG_ 1079 CTM_TrnSigLmpLftOpnSta 3;
BA_ "NetworkRequest" SG_ 1079 CTM_TrnSigLmpLftOpnSta 0;
BA_ "Version" SG_ 1079 CTM_TrnSigLmpLftOpnSta "18.10.07";
BA_ "Description" SG_ 1079 CTM_TrnSigLmpRtOpnSta "Trailer T/SIG Lamp Right OpenStatus";
BA_ "GenSigSendType" SG_ 1079 CTM_TrnSigLmpRtOpnSta 4;
BA_ "UserSigValidity" SG_ 1079 CTM_TrnSigLmpRtOpnSta 3;
BA_ "NetworkRequest" SG_ 1079 CTM_TrnSigLmpRtOpnSta 0;
BA_ "Version" SG_ 1079 CTM_TrnSigLmpRtOpnSta "18.10.07";
BA_ "GenMsgSendType" BO_ 2382594049 0;
BA_ "VFrameFormat" BO_ 2382594049 1;
BA_ "Description" SG_ 2382594049 DATC_Crc3Val "The data area for CRC calculation is based on the data length (DLC) of the message DB.

The CRC shall be calculated over the entire data block (excluding the CRC bytes) including the user data, alive counter and Data ID

 

- CRC Polynomial (0x1021) , Initial Value : 0xFFFF, XOR value : 0x0000, Data ID : Message ID + 0xF800 

- The initial value is for CRC calculation and the message should be sent with the calculated result value. 

- The mathematical expression to 16 bit CRC polynomial is given here. G(x) = x16 + x12 + x5 + 1";
BA_ "GenSigSendType" SG_ 2382594049 DATC_Crc3Val 4;
BA_ "GenSigStartValue" SG_ 2382594049 DATC_Crc3Val 65535;
BA_ "UserSigValidity" SG_ 2382594049 DATC_Crc3Val 3;
BA_ "Version" SG_ 2382594049 DATC_Crc3Val "18.11.08";
BA_ "Description" SG_ 2382594049 DATC_AlvCnt3Val "For the first transmission request for a data element the counter shall be initialized with 0 and shall be incremented by 1 for every subsequent send request. 

When the counter reaches the maximum value(0xFF), then it shall restart with 0 for the next send request";
BA_ "GenSigSendType" SG_ 2382594049 DATC_AlvCnt3Val 4;
BA_ "UserSigValidity" SG_ 2382594049 DATC_AlvCnt3Val 3;
BA_ "Version" SG_ 2382594049 DATC_AlvCnt3Val "18.11.08";
BA_ "Description" SG_ 2382594049 DATC_DrvTempCDis "This signal indicates setting temperature (¡É) of Driver Side.";
BA_ "GenSigSendType" SG_ 2382594049 DATC_DrvTempCDis 4;
BA_ "UserSigValidity" SG_ 2382594049 DATC_DrvTempCDis 6;
BA_REL_ "GenSigTimeoutTime" BU_SG_REL_ ATS SG_ 2382594049 DATC_DrvTempCDis 1500;
BA_ "Version" SG_ 2382594049 DATC_DrvTempCDis "18.05.01";
BA_ "Description" SG_ 2382594049 DATC_DrvTempFDis "This signal indicates setting temperature (¢µ) of Driver Side.";
BA_ "GenSigSendType" SG_ 2382594049 DATC_DrvTempFDis 4;
BA_ "UserSigValidity" SG_ 2382594049 DATC_DrvTempFDis 6;
BA_REL_ "GenSigTimeoutTime" BU_SG_REL_ ATS SG_ 2382594049 DATC_DrvTempFDis 1500;
BA_ "Version" SG_ 2382594049 DATC_DrvTempFDis "18.05.01";
BA_ "Description" SG_ 2382594049 DATC_PassTempCDis "This signal indicates setting temperature (¡É) of Passenger Side.";
BA_ "GenSigSendType" SG_ 2382594049 DATC_PassTempCDis 4;
BA_ "UserSigValidity" SG_ 2382594049 DATC_PassTempCDis 6;
BA_REL_ "GenSigTimeoutTime" BU_SG_REL_ ATS SG_ 2382594049 DATC_PassTempCDis 1500;
BA_ "Version" SG_ 2382594049 DATC_PassTempCDis "18.05.01";
BA_ "Description" SG_ 2382594049 DATC_PassTempFDis "This signal indicates setting temperature (¢µ) of Passenger Side.";
BA_ "GenSigSendType" SG_ 2382594049 DATC_PassTempFDis 4;
BA_ "UserSigValidity" SG_ 2382594049 DATC_PassTempFDis 6;
BA_REL_ "GenSigTimeoutTime" BU_SG_REL_ ATS SG_ 2382594049 DATC_PassTempFDis 1500;
BA_ "Version" SG_ 2382594049 DATC_PassTempFDis "18.05.01";
BA_ "Description" SG_ 2382594049 DATC_TempDispSta "This signal is an information display of the set temperature range of DATC.";
BA_ "GenSigSendType" SG_ 2382594049 DATC_TempDispSta 4;
BA_ "UserSigValidity" SG_ 2382594049 DATC_TempDispSta 7;
BA_ "Version" SG_ 2382594049 DATC_TempDispSta "17.11.00";
BA_ "Description" SG_ 2382594049 DATC_PreEngOnReq2 "Pre Engine On Request";
BA_ "GenSigSendType" SG_ 2382594049 DATC_PreEngOnReq2 4;
BA_ "UserSigValidity" SG_ 2382594049 DATC_PreEngOnReq2 4;
BA_ "Version" SG_ 2382594049 DATC_PreEngOnReq2 "20.04.03";
BA_ "GenMsgSendType" BO_ 1085 0;
BA_ "Description" SG_ 1085 DLBCU_ActiveDis "¿¡¾î¼­Æ÷Æ®¸ðµå AVN Ç¥½Ã";
BA_ "GenSigSendType" SG_ 1085 DLBCU_ActiveDis 4;
BA_ "UserSigValidity" SG_ 1085 DLBCU_ActiveDis 1;
BA_REL_ "GenSigTimeoutTime" BU_SG_REL_ DPSU SG_ 1085 DLBCU_ActiveDis 1500;
BA_REL_ "GenSigTimeoutTime" BU_SG_REL_ CGW_CCU SG_ 1085 DLBCU_ActiveDis 1500;
BA_ "NetworkRequest" SG_ 1085 DLBCU_ActiveDis 0;
BA_ "NetworkRequestHoldingTime" SG_ 1085 DLBCU_ActiveDis 5000;
BA_ "Version" SG_ 1085 DLBCU_ActiveDis "18.09.01";
BA_ "Description" SG_ 1085 DLBCU_CushSoftSta "Äí¼Ç ¼ÒÇÁÆ®´Ï½º Signal ÇÇµå¹é to AVN";
BA_ "GenSigSendType" SG_ 1085 DLBCU_CushSoftSta 4;
BA_ "UserSigValidity" SG_ 1085 DLBCU_CushSoftSta 1;
BA_REL_ "GenSigTimeoutTime" BU_SG_REL_ CGW_CCU SG_ 1085 DLBCU_CushSoftSta 1500;
BA_ "NetworkRequest" SG_ 1085 DLBCU_CushSoftSta 0;
BA_ "NetworkRequestHoldingTime" SG_ 1085 DLBCU_CushSoftSta 5000;
BA_ "Version" SG_ 1085 DLBCU_CushSoftSta "18.10.11";
BA_ "Description" SG_ 1085 DLBCU_CellOpt "½ÃÆ® °ø¾Ð ½Ã½ºÅÛ »ç¾ç Á¤º¸ ½ÅÈ£(3Cell:·´¸Ó¼­Æ÷Æ®/5Cell:·³¹öº¼½ºÅÍ/7Cell:·³¹öº¼½ºÅÍÄí¼Ç)";
BA_ "GenSigSendType" SG_ 1085 DLBCU_CellOpt 4;
BA_ "UserSigValidity" SG_ 1085 DLBCU_CellOpt 0;
BA_ "NetworkRequest" SG_ 1085 DLBCU_CellOpt 0;
BA_ "NetworkRequestHoldingTime" SG_ 1085 DLBCU_CellOpt 5000;
BA_ "Version" SG_ 1085 DLBCU_CellOpt "18.09.01";
BA_ "Description" SG_ 1085 DLBCU_BodySpprtSta "Seat Body Support Function USM R Value";
BA_ "GenSigSendType" SG_ 1085 DLBCU_BodySpprtSta 4;
BA_ "UserSigValidity" SG_ 1085 DLBCU_BodySpprtSta 1;
BA_REL_ "GenSigTimeoutTime" BU_SG_REL_ CGW_CCU SG_ 1085 DLBCU_BodySpprtSta 1500;
BA_ "Version" SG_ 1085 DLBCU_BodySpprtSta "18.10.09";
BA_ "Description" SG_ 1085 DLBCU_BodySpprtDis "Seat Body Support Function Display Request";
BA_ "GenSigSendType" SG_ 1085 DLBCU_BodySpprtDis 4;
BA_ "UserSigValidity" SG_ 1085 DLBCU_BodySpprtDis 1;
BA_REL_ "GenSigTimeoutTime" BU_SG_REL_ CGW_CCU SG_ 1085 DLBCU_BodySpprtDis 1500;
BA_ "Version" SG_ 1085 DLBCU_BodySpprtDis "18.10.09";
BA_ "Description" SG_ 1085 DLBCU_SmartCtrl_Set_Rvalue "ÁÖÇà Áß Çã¸® º¸È£ ±â´É USM µ¿ÀÛ ¼³Á¤ °ª (R Value)";
BA_ "GenSigSendType" SG_ 1085 DLBCU_SmartCtrl_Set_Rvalue 4;
BA_ "UserSigValidity" SG_ 1085 DLBCU_SmartCtrl_Set_Rvalue 0;
BA_REL_ "GenSigTimeoutTime" BU_SG_REL_ CGW_CCU SG_ 1085 DLBCU_SmartCtrl_Set_Rvalue 1500;
BA_ "Version" SG_ 1085 DLBCU_SmartCtrl_Set_Rvalue "20.09.00";
BA_ "Description" SG_ 1085 DLBCU_DrvModUSMSta "µå¶óÀÌºê ¸ðµå ¿¬µ¿ Signal ÇÇµå¹é to AVN";
BA_ "GenSigSendType" SG_ 1085 DLBCU_DrvModUSMSta 4;
BA_ "UserSigValidity" SG_ 1085 DLBCU_DrvModUSMSta 1;
BA_REL_ "GenSigTimeoutTime" BU_SG_REL_ CGW_CCU SG_ 1085 DLBCU_DrvModUSMSta 1500;
BA_ "NetworkRequest" SG_ 1085 DLBCU_DrvModUSMSta 0;
BA_ "NetworkRequestHoldingTime" SG_ 1085 DLBCU_DrvModUSMSta 5000;
BA_ "Version" SG_ 1085 DLBCU_DrvModUSMSta "18.03.07";
BA_ "Description" SG_ 1085 DLBCU_ActiveStrSta "¿¡¾î¼­Æ÷Æ® ¸ðµå °­µµ Signal ÇÇµå¹é to AVN";
BA_ "GenSigSendType" SG_ 1085 DLBCU_ActiveStrSta 4;
BA_ "UserSigValidity" SG_ 1085 DLBCU_ActiveStrSta 1;
BA_REL_ "GenSigTimeoutTime" BU_SG_REL_ CGW_CCU SG_ 1085 DLBCU_ActiveStrSta 1500;
BA_ "NetworkRequest" SG_ 1085 DLBCU_ActiveStrSta 0;
BA_ "NetworkRequestHoldingTime" SG_ 1085 DLBCU_ActiveStrSta 5000;
BA_ "Version" SG_ 1085 DLBCU_ActiveStrSta "18.03.07";
BA_ "Description" SG_ 1085 DLBCU_ActiveTimeSta "¿¡¾î¼­Æ÷Æ® Àç»ý½Ã°£ Signal ÇÇµå¹é to AVN";
BA_ "GenSigSendType" SG_ 1085 DLBCU_ActiveTimeSta 4;
BA_ "UserSigValidity" SG_ 1085 DLBCU_ActiveTimeSta 1;
BA_REL_ "GenSigTimeoutTime" BU_SG_REL_ CGW_CCU SG_ 1085 DLBCU_ActiveTimeSta 1500;
BA_ "NetworkRequest" SG_ 1085 DLBCU_ActiveTimeSta 0;
BA_ "NetworkRequestHoldingTime" SG_ 1085 DLBCU_ActiveTimeSta 5000;
BA_ "Version" SG_ 1085 DLBCU_ActiveTimeSta "18.03.07";
BA_ "GenMsgSendType" BO_ 687 0;
BA_ "GenMsgCycleTime" BO_ 687 100;
BA_ "GenMsgCycleTimeFast" BO_ 687 0;
BA_ "GenMsgNrOfRepetition" BO_ 687 0;
BA_ "Description" SG_ 687 HOD_Crc1Val "The data area for CRC calculation is based on the data length (DLC) of the message DB.

The CRC shall be calculated over the entire data block (excluding the CRC bytes) including the user data, alive counter and Data ID 

 

- CRC Polynomial (0x1D) , Initial Value : 0x00, XOR value : 0xFF, Data ID Mode : Both, Data ID : Message ID + 0xF800 

- The initial value is for CRC calculation and the message should be sent with the calculated result value. 

The mathematical expression to 8 bit CRC polynomial is given here. G(x) = x8 + x4 + x3 + x2 + 1";
BA_ "GenSigStartValue" SG_ 687 HOD_Crc1Val 255;
BA_ "UserSigValidity" SG_ 687 HOD_Crc1Val 3;
BA_REL_ "GenSigTimeoutTime" BU_SG_REL_ CGW_CCU SG_ 687 HOD_Crc1Val 1500;
BA_ "Version" SG_ 687 HOD_Crc1Val "19.08.08";
BA_ "Description" SG_ 687 HOD_AlvCnt1Val "For the first transmission request for a data element the counter shall be initialized with 0 and shall be incremented by 1

for every subsequent send request. When the counter reaches the maximum value(0xE), then it shall restart with 0 for the next send request";
BA_ "UserSigValidity" SG_ 687 HOD_AlvCnt1Val 3;
BA_REL_ "GenSigTimeoutTime" BU_SG_REL_ CGW_CCU SG_ 687 HOD_AlvCnt1Val 1500;
BA_ "Version" SG_ 687 HOD_AlvCnt1Val "19.08.08";
BA_ "Description" SG_ 687 HOD_Dir_Status "This signal indicates the status of hands on/off";
BA_ "GenSigStartValue" SG_ 687 HOD_Dir_Status 7;
BA_ "UserSigValidity" SG_ 687 HOD_Dir_Status 3;
BA_REL_ "GenSigTimeoutTime" BU_SG_REL_ CGW_CCU SG_ 687 HOD_Dir_Status 1500;
BA_ "Version" SG_ 687 HOD_Dir_Status "20.01.01";
BA_ "Description" SG_ 687 HOD_Option "This signal is a checkable signal that the HOD is applied.

This signal should be fixed 0x1.";
BA_ "UserSigValidity" SG_ 687 HOD_Option 3;
BA_REL_ "GenSigTimeoutTime" BU_SG_REL_ CGW_CCU SG_ 687 HOD_Option 1500;
BA_ "Version" SG_ 687 HOD_Option "20.01.01";
BA_ "Description" SG_ 687 HOD_CapaCh0 "This signal is a Front Capacitance value(pF)";
BA_ "UserSigValidity" SG_ 687 HOD_CapaCh0 3;
BA_REL_ "GenSigTimeoutTime" BU_SG_REL_ CGW_CCU SG_ 687 HOD_CapaCh0 1500;
BA_ "Version" SG_ 687 HOD_CapaCh0 "21.01.01";
BA_ "Description" SG_ 687 HOD_CapaCh1 "This signal is a Rear Capacitance value(pF)";
BA_ "UserSigValidity" SG_ 687 HOD_CapaCh1 3;
BA_REL_ "GenSigTimeoutTime" BU_SG_REL_ CGW_CCU SG_ 687 HOD_CapaCh1 1500;
BA_ "Version" SG_ 687 HOD_CapaCh1 "21.01.01";
BA_ "GenMsgSendType" BO_ 2164278529 0;
BA_ "GenMsgCycleTime" BO_ 2164278529 50;
BA_ "GenMsgCycleTimeFast" BO_ 2164278529 0;
BA_ "GenMsgNrOfRepetition" BO_ 2164278529 0;
BA_ "VFrameFormat" BO_ 2164278529 1;
BA_ "Description" SG_ 2164278529 HTCU_Crc4Val "The data area for CRC calculation is based on the data length (DLC) of the message DB.

The CRC shall be calculated over the entire data block (excluding the CRC bytes) including the user data, alive counter and Data ID

 

- CRC Polynomial (0x1021) , Initial Value : 0xFFFF, XOR value : 0x0000, Data ID : Message ID + 0xF800 

- The initial value is for CRC calculation and the message should be sent with the calculated result value. 

- The mathematical expression to 16 bit CRC polynomial is given here. G(x) = x16 + x12 + x5 + 1";
BA_ "GenSigStartValue" SG_ 2164278529 HTCU_Crc4Val 65535;
BA_ "UserSigValidity" SG_ 2164278529 HTCU_Crc4Val 3;
BA_ "RoutingFactor" SG_ 2164278529 HTCU_Crc4Val 5;
BA_ "Version" SG_ 2164278529 HTCU_Crc4Val "18.11.08";
BA_ "Description" SG_ 2164278529 HTCU_AlvCnt4Val "For the first transmission request for a data element the counter shall be initialized with 0 and shall be incremented by 1 for every subsequent send request. 

When the counter reaches the maximum value(0xFF), then it shall restart with 0 for the next send request";
BA_ "UserSigValidity" SG_ 2164278529 HTCU_AlvCnt4Val 3;
BA_ "RoutingFactor" SG_ 2164278529 HTCU_AlvCnt4Val 5;
BA_ "Version" SG_ 2164278529 HTCU_AlvCnt4Val "18.11.08";
BA_ "Description" SG_ 2164278529 HTCU_TrgtGearSta "HTCU_TrgtGearSta informs about the speed, which is currently engaged in the gearbox, or, in case of a gear change (HTCU_GearChgSta), which speed is reached.

Note: Gear changes covering more than one speed are also possible.

In the P and N positions, the frictional connection is interrupted hydraulically.

Depending on the type of error, the 3rd or 4th (forward) speed, and the R (reverse) speed are engaged in the limp home program.";
BA_ "UserSigValidity" SG_ 2164278529 HTCU_TrgtGearSta 3;
BA_ "RoutingFactor" SG_ 2164278529 HTCU_TrgtGearSta 5;
BA_ "Version" SG_ 2164278529 HTCU_TrgtGearSta "18.12.07";
BA_ "Description" SG_ 2164278529 HTCU_RdySta "Flag that the HTCU is ready to work. (In fact, this flag is true from the moment that CAN is working. So, normally no ¡°false¡± will be sent on CAN.) This flag does not show that everything is alright in the HTCU. This information is given in the warning and fault flags.";
BA_ "UserSigValidity" SG_ 2164278529 HTCU_RdySta 3;
BA_ "RoutingFactor" SG_ 2164278529 HTCU_RdySta 5;
BA_ "Version" SG_ 2164278529 HTCU_RdySta "18.08.02";
BA_ "Description" SG_ 2164278529 HTCU_GearChgSta "HTCU_GearChgSta indicates whether a gear change is being executed in the gearbox.

Note : Gear change means a gear shift at D-range and Garage shift(PRND).";
BA_ "UserSigValidity" SG_ 2164278529 HTCU_GearChgSta 3;
BA_ "RoutingFactor" SG_ 2164278529 HTCU_GearChgSta 5;
BA_ "Version" SG_ 2164278529 HTCU_GearChgSta "18.08.02";
BA_ "Description" SG_ 2164278529 HTCU_TqRdctnPcVal "The HTCU requests a torque reduction via the signal CR_Tcu_TqInt_Pc to the ECU and MCU.

The requested torque HTCU_TqRdctnPcVal refers to a maximum torque CR_Ems_TqStd_Nm. This conversion into a physical quantity provides a range of CR_Ems_TqStd_Nm of 0 ..199.61%.

There is no specific phase relationship between the output and any other signal.

Conversion : (PH) = 0.390625 * (HEX) [%]";
BA_ "GenSigStartValue" SG_ 2164278529 HTCU_TqRdctnPcVal 511;
BA_ "UserSigValidity" SG_ 2164278529 HTCU_TqRdctnPcVal 3;
BA_ "RoutingFactor" SG_ 2164278529 HTCU_TqRdctnPcVal 5;
BA_ "Version" SG_ 2164278529 HTCU_TqRdctnPcVal "18.08.02";
BA_ "Description" SG_ 2164278529 HTCU_FltSta "HTCU_FltSta informs about status of transmission control.



<Value Description>

Bit 0: HTCU Diagnostic failure

Bit 1: HTCU Diagnostic failure ? Limphome activated

Bit 2: OPU/EOP Diagnostic failure";
BA_ "UserSigValidity" SG_ 2164278529 HTCU_FltSta 3;
BA_ "RoutingFactor" SG_ 2164278529 HTCU_FltSta 5;
BA_ "Version" SG_ 2164278529 HTCU_FltSta "18.08.02";
BA_ "Description" SG_ 2164278529 HTCU_GearSlctrDis "Position (P, R, N..), which was identified by the gear selector.

In case the gear selector is in a intermediate position, the last clear recognized position is used.

There is no specific phase relationship between the output and any other signal.";
BA_ "GenSigStartValue" SG_ 2164278529 HTCU_GearSlctrDis 9;
BA_ "UserSigValidity" SG_ 2164278529 HTCU_GearSlctrDis 3;
BA_ "RoutingFactor" SG_ 2164278529 HTCU_GearSlctrDis 5;
BA_ "Version" SG_ 2164278529 HTCU_GearSlctrDis "18.08.02";
BA_ "Description" SG_ 2164278529 HTCU_SlwTqRdctnPcVal "The HTCU requests a slow torque reduction via the signal HTCU_TqRdctnPcVal to the ECU and MCU.";
BA_ "GenSigStartValue" SG_ 2164278529 HTCU_SlwTqRdctnPcVal 511;
BA_ "UserSigValidity" SG_ 2164278529 HTCU_SlwTqRdctnPcVal 3;
BA_ "RoutingFactor" SG_ 2164278529 HTCU_SlwTqRdctnPcVal 5;
BA_ "Version" SG_ 2164278529 HTCU_SlwTqRdctnPcVal "18.08.02";
BA_ "Description" SG_ 2164278529 HTCU_FanCtrlReq "Fan control request by OPU";
BA_ "TimeoutValue" SG_ 2164278529 HTCU_FanCtrlReq "0x0";
BA_ "UserSigValidity" SG_ 2164278529 HTCU_FanCtrlReq 3;
BA_ "RoutingFactor" SG_ 2164278529 HTCU_FanCtrlReq 5;
BA_ "Version" SG_ 2164278529 HTCU_FanCtrlReq "21.07.00";
BA_ "GenMsgSendType" BO_ 2164278530 0;
BA_ "GenMsgCycleTime" BO_ 2164278530 50;
BA_ "GenMsgCycleTimeFast" BO_ 2164278530 0;
BA_ "GenMsgNrOfRepetition" BO_ 2164278530 0;
BA_ "VFrameFormat" BO_ 2164278530 1;
BA_ "Description" SG_ 2164278530 HTCU_VehSpdKphVal "The vehicle speed calculated by HTCU is transferred.

If a vehicle has no vehicle speed sensor, no wheel speed sensor and no ABS(ESC) then it is impossible for an EMS to calculate veficle speed. In this case a HTCU should calculate vehicle speed and send to other ECUs.

The calculation can be done with output speed of gearbox, final gear ratio and fixed actual radius of a tire.";
BA_ "UserSigValidity" SG_ 2164278530 HTCU_VehSpdKphVal 3;
BA_ "RoutingFactor" SG_ 2164278530 HTCU_VehSpdKphVal 5;
BA_ "Version" SG_ 2164278530 HTCU_VehSpdKphVal "18.08.02";
BA_ "Description" SG_ 2164278530 HTCU_HvOpuSpdCmdRpmVal "CR_Tcu_OpuSpdCmd_Rpm informs about the external oil pump speed.";
BA_ "UserSigValidity" SG_ 2164278530 HTCU_HvOpuSpdCmdRpmVal 3;
BA_ "RoutingFactor" SG_ 2164278530 HTCU_HvOpuSpdCmdRpmVal 5;
BA_ "Version" SG_ 2164278530 HTCU_HvOpuSpdCmdRpmVal "17.11.00";
BA_ "UserSigValidity" SG_ 2164278530 HTCU_TrgtShftClsCCanSta 3;
BA_ "RoutingFactor" SG_ 2164278530 HTCU_TrgtShftClsCCanSta 5;
BA_ "Version" SG_ 2164278530 HTCU_TrgtShftClsCCanSta "17.11.00";
BA_ "Description" SG_ 2164278530 HTCU_CtrlablSta "This signal indicates the status of the TCU control which normally works by hydraulic pressure in the T/M";
BA_ "UserSigValidity" SG_ 2164278530 HTCU_CtrlablSta 3;
BA_ "RoutingFactor" SG_ 2164278530 HTCU_CtrlablSta 5;
BA_ "Version" SG_ 2164278530 HTCU_CtrlablSta "20.10.02";
BA_ "Description" SG_ 2164278530 HTCU_PrgrmSta "This signal informs about current program status in HTCU";
BA_ "UserSigValidity" SG_ 2164278530 HTCU_PrgrmSta 3;
BA_ "RoutingFactor" SG_ 2164278530 HTCU_PrgrmSta 5;
BA_ "Version" SG_ 2164278530 HTCU_PrgrmSta "17.11.00";
BA_ "Description" SG_ 2164278530 HTCU_FsCltchLmphmActvSta "This signal informs about engine clutch limp-home control activation";
BA_ "UserSigValidity" SG_ 2164278530 HTCU_FsCltchLmphmActvSta 3;
BA_ "RoutingFactor" SG_ 2164278530 HTCU_FsCltchLmphmActvSta 5;
BA_ "Version" SG_ 2164278530 HTCU_FsCltchLmphmActvSta "17.11.00";
BA_ "Description" SG_ 2164278530 HTCU_FsIdleTrgtRpmVal "Request idle target rpm for engine clutch limp-home control";
BA_ "UserSigValidity" SG_ 2164278530 HTCU_FsIdleTrgtRpmVal 3;
BA_ "RoutingFactor" SG_ 2164278530 HTCU_FsIdleTrgtRpmVal 5;
BA_ "Version" SG_ 2164278530 HTCU_FsIdleTrgtRpmVal "17.11.00";
BA_ "Description" SG_ 2164278530 HTCU_FsAddtnlTqLssPcVal "Additional torque loss for engine clutch limp-home control";
BA_ "UserSigValidity" SG_ 2164278530 HTCU_FsAddtnlTqLssPcVal 3;
BA_ "RoutingFactor" SG_ 2164278530 HTCU_FsAddtnlTqLssPcVal 5;
BA_ "Version" SG_ 2164278530 HTCU_FsAddtnlTqLssPcVal "17.11.00";
BA_ "Description" SG_ 2164278530 HTCU_VehSpdDcmlKphVal "The signal HTCU_VehSpdDcmlKphVal means the value which is below decimal point of the vehicle speed.

For instance, if a vehicle speed is 13.75Km/h, HTCU_VehSpdKphVal means 13Km/h and HTCU_VehSpdDcmlKphVal means 0.75Km/h.

(Min ~ Max: 0.00 ~ 0.99)";
BA_ "UserSigValidity" SG_ 2164278530 HTCU_VehSpdDcmlKphVal 3;
BA_ "RoutingFactor" SG_ 2164278530 HTCU_VehSpdDcmlKphVal 5;
BA_ "Version" SG_ 2164278530 HTCU_VehSpdDcmlKphVal "18.12.07";
BA_ "GenMsgSendType" BO_ 2164278531 0;
BA_ "GenMsgCycleTime" BO_ 2164278531 50;
BA_ "GenMsgCycleTimeFast" BO_ 2164278531 0;
BA_ "GenMsgNrOfRepetition" BO_ 2164278531 0;
BA_ "VFrameFormat" BO_ 2164278531 1;
BA_ "Description" SG_ 2164278531 HTCU_FsEngTqRdctnPcVal "This signal informs about engine torque reduction request for engine clutch limp-home control";
BA_ "GenSigStartValue" SG_ 2164278531 HTCU_FsEngTqRdctnPcVal 255;
BA_ "UserSigValidity" SG_ 2164278531 HTCU_FsEngTqRdctnPcVal 3;
BA_ "RoutingFactor" SG_ 2164278531 HTCU_FsEngTqRdctnPcVal 5;
BA_ "Version" SG_ 2164278531 HTCU_FsEngTqRdctnPcVal "19.02.06";
BA_ "Description" SG_ 2164278531 HTCU_RapidKDReq "Rapid K/D Shift Request";
BA_ "UserSigValidity" SG_ 2164278531 HTCU_RapidKDReq 3;
BA_ "RoutingFactor" SG_ 2164278531 HTCU_RapidKDReq 5;
BA_ "Version" SG_ 2164278531 HTCU_RapidKDReq "17.11.00";
BA_ "UserSigValidity" SG_ 2164278531 HTCU_CurrGearSta 3;
BA_ "RoutingFactor" SG_ 2164278531 HTCU_CurrGearSta 5;
BA_ "Version" SG_ 2164278531 HTCU_CurrGearSta "18.12.07";
BA_ "Description" SG_ 2164278531 HTCU_GearShftUpDisGSI "Gear Shift-up display status for Gear shift indicator (EU Regulations)";
BA_ "UserSigValidity" SG_ 2164278531 HTCU_GearShftUpDisGSI 3;
BA_ "RoutingFactor" SG_ 2164278531 HTCU_GearShftUpDisGSI 5;
BA_ "Version" SG_ 2164278531 HTCU_GearShftUpDisGSI "18.08.01";
BA_ "Description" SG_ 2164278531 HTCU_GearShftDnDisGSI "Gear Shift-down display status for Gear shift indicator (EU Regulations)";
BA_ "UserSigValidity" SG_ 2164278531 HTCU_GearShftDnDisGSI 3;
BA_ "RoutingFactor" SG_ 2164278531 HTCU_GearShftDnDisGSI 5;
BA_ "Version" SG_ 2164278531 HTCU_GearShftDnDisGSI "18.08.01";
BA_ "Description" SG_ 2164278531 HTCU_TrgtGearStaGSI "Target Gear for Gear shift indicator (EU Regulations)";
BA_ "UserSigValidity" SG_ 2164278531 HTCU_TrgtGearStaGSI 3;
BA_ "RoutingFactor" SG_ 2164278531 HTCU_TrgtGearStaGSI 5;
BA_ "Version" SG_ 2164278531 HTCU_TrgtGearStaGSI "19.02.06";
BA_ "Description" SG_ 2164278531 HTCU_SolBSta "Status of On/Off Solenoid B";
BA_ "UserSigValidity" SG_ 2164278531 HTCU_SolBSta 3;
BA_ "RoutingFactor" SG_ 2164278531 HTCU_SolBSta 5;
BA_ "Version" SG_ 2164278531 HTCU_SolBSta "18.08.01";
BA_ "Description" SG_ 2164278531 HTCU_LnPrsBarVal "This signal informs about the Transmission valve body line pressure command from HTCU";
BA_ "UserSigValidity" SG_ 2164278531 HTCU_LnPrsBarVal 3;
BA_ "RoutingFactor" SG_ 2164278531 HTCU_LnPrsBarVal 5;
BA_ "Version" SG_ 2164278531 HTCU_LnPrsBarVal "17.11.00";
BA_ "GenMsgCycleTime" BO_ 1219 0;
BA_ "Description" SG_ 1219 BLTN_CAM_Rec_OWD_NvalueSet "Record On/Off Set of On While Driving";
BA_ "GenSigSendType" SG_ 1219 BLTN_CAM_Rec_OWD_NvalueSet 4;
BA_ "UserSigValidity" SG_ 1219 BLTN_CAM_Rec_OWD_NvalueSet 0;
BA_REL_ "GenSigTimeoutTime" BU_SG_REL_ BLTN_CAM SG_ 1219 BLTN_CAM_Rec_OWD_NvalueSet 0;
BA_ "Version" SG_ 1219 BLTN_CAM_Rec_OWD_NvalueSet "21.05.02";
BA_ "Description" SG_ 1219 BLTN_CAM_Time_Stm_NvalueSet "Record Set of Date and Time Stamp";
BA_ "GenSigSendType" SG_ 1219 BLTN_CAM_Time_Stm_NvalueSet 4;
BA_ "UserSigValidity" SG_ 1219 BLTN_CAM_Time_Stm_NvalueSet 0;
BA_REL_ "GenSigTimeoutTime" BU_SG_REL_ BLTN_CAM SG_ 1219 BLTN_CAM_Time_Stm_NvalueSet 0;
BA_ "Version" SG_ 1219 BLTN_CAM_Time_Stm_NvalueSet "21.05.02";
BA_ "Description" SG_ 1219 BLTN_CAM_Spd_Stm_NvalueSet "Record Set of Speed Stamp";
BA_ "GenSigSendType" SG_ 1219 BLTN_CAM_Spd_Stm_NvalueSet 4;
BA_ "UserSigValidity" SG_ 1219 BLTN_CAM_Spd_Stm_NvalueSet 0;
BA_REL_ "GenSigTimeoutTime" BU_SG_REL_ BLTN_CAM SG_ 1219 BLTN_CAM_Spd_Stm_NvalueSet 0;
BA_ "Version" SG_ 1219 BLTN_CAM_Spd_Stm_NvalueSet "21.11.07";
BA_ "Description" SG_ 1219 BLTN_CAM_Locatn_Stm_NvalueSet "Record Set of Location Stamp";
BA_ "GenSigSendType" SG_ 1219 BLTN_CAM_Locatn_Stm_NvalueSet 4;
BA_ "UserSigValidity" SG_ 1219 BLTN_CAM_Locatn_Stm_NvalueSet 0;
BA_REL_ "GenSigTimeoutTime" BU_SG_REL_ BLTN_CAM SG_ 1219 BLTN_CAM_Locatn_Stm_NvalueSet 0;
BA_ "Version" SG_ 1219 BLTN_CAM_Locatn_Stm_NvalueSet "21.05.02";
BA_ "Description" SG_ 1219 BLTN_CAM_TrnSig_Stm_NvalueSet "Record Set of Turn Signal Stamp";
BA_ "GenSigSendType" SG_ 1219 BLTN_CAM_TrnSig_Stm_NvalueSet 4;
BA_ "UserSigValidity" SG_ 1219 BLTN_CAM_TrnSig_Stm_NvalueSet 0;
BA_REL_ "GenSigTimeoutTime" BU_SG_REL_ BLTN_CAM SG_ 1219 BLTN_CAM_TrnSig_Stm_NvalueSet 0;
BA_ "Version" SG_ 1219 BLTN_CAM_TrnSig_Stm_NvalueSet "21.05.02";
BA_ "Description" SG_ 1219 BLTN_CAM_AclBrk_Stm_NvalueSet "Record Set of Accelerator Brake Stamp";
BA_ "GenSigSendType" SG_ 1219 BLTN_CAM_AclBrk_Stm_NvalueSet 4;
BA_ "UserSigValidity" SG_ 1219 BLTN_CAM_AclBrk_Stm_NvalueSet 0;
BA_REL_ "GenSigTimeoutTime" BU_SG_REL_ BLTN_CAM SG_ 1219 BLTN_CAM_AclBrk_Stm_NvalueSet 0;
BA_ "Version" SG_ 1219 BLTN_CAM_AclBrk_Stm_NvalueSet "21.11.07";
BA_ "Description" SG_ 1219 BLTN_CAM_Rec_DEV_NvalueSet "Record On/Off Set of Driving Event";
BA_ "GenSigSendType" SG_ 1219 BLTN_CAM_Rec_DEV_NvalueSet 4;
BA_ "UserSigValidity" SG_ 1219 BLTN_CAM_Rec_DEV_NvalueSet 0;
BA_REL_ "GenSigTimeoutTime" BU_SG_REL_ BLTN_CAM SG_ 1219 BLTN_CAM_Rec_DEV_NvalueSet 0;
BA_ "Version" SG_ 1219 BLTN_CAM_Rec_DEV_NvalueSet "21.05.02";
BA_ "Description" SG_ 1219 BLTN_CAM_GearPos_Stm_NvalueSet "Record Set of Gear Position Stamp";
BA_ "GenSigSendType" SG_ 1219 BLTN_CAM_GearPos_Stm_NvalueSet 4;
BA_ "UserSigValidity" SG_ 1219 BLTN_CAM_GearPos_Stm_NvalueSet 0;
BA_REL_ "GenSigTimeoutTime" BU_SG_REL_ BLTN_CAM SG_ 1219 BLTN_CAM_GearPos_Stm_NvalueSet 0;
BA_ "Version" SG_ 1219 BLTN_CAM_GearPos_Stm_NvalueSet "21.11.07";
BA_ "Description" SG_ 1219 BLTN_CAM_EVSen_Stm_NvalueSet "Record Set of Event Sensitivity Stamp";
BA_ "GenSigSendType" SG_ 1219 BLTN_CAM_EVSen_Stm_NvalueSet 4;
BA_ "UserSigValidity" SG_ 1219 BLTN_CAM_EVSen_Stm_NvalueSet 0;
BA_REL_ "GenSigTimeoutTime" BU_SG_REL_ BLTN_CAM SG_ 1219 BLTN_CAM_EVSen_Stm_NvalueSet 0;
BA_ "Version" SG_ 1219 BLTN_CAM_EVSen_Stm_NvalueSet "21.05.02";
BA_ "Description" SG_ 1219 BLTN_CAM_Strangl_Stm_NvalueSet "Record Set of Steering Angle Stamp";
BA_ "GenSigSendType" SG_ 1219 BLTN_CAM_Strangl_Stm_NvalueSet 4;
BA_ "UserSigValidity" SG_ 1219 BLTN_CAM_Strangl_Stm_NvalueSet 0;
BA_REL_ "GenSigTimeoutTime" BU_SG_REL_ BLTN_CAM SG_ 1219 BLTN_CAM_Strangl_Stm_NvalueSet 0;
BA_ "Version" SG_ 1219 BLTN_CAM_Strangl_Stm_NvalueSet "21.07.05";
BA_ "Description" SG_ 1219 BLTN_CAM_PrkTime_NvalueSet "Parking Operation Setting Time, Resolution : hr";
BA_ "GenSigSendType" SG_ 1219 BLTN_CAM_PrkTime_NvalueSet 4;
BA_ "UserSigValidity" SG_ 1219 BLTN_CAM_PrkTime_NvalueSet 0;
BA_REL_ "GenSigTimeoutTime" BU_SG_REL_ BLTN_CAM SG_ 1219 BLTN_CAM_PrkTime_NvalueSet 0;
BA_ "Version" SG_ 1219 BLTN_CAM_PrkTime_NvalueSet "21.11.07";
BA_ "Description" SG_ 1219 BLTN_CAM_EV_BfrTime_NvalueSet "Driving Event Time Setting - Before, Resolution : sec";
BA_ "GenSigSendType" SG_ 1219 BLTN_CAM_EV_BfrTime_NvalueSet 4;
BA_ "UserSigValidity" SG_ 1219 BLTN_CAM_EV_BfrTime_NvalueSet 0;
BA_REL_ "GenSigTimeoutTime" BU_SG_REL_ BLTN_CAM SG_ 1219 BLTN_CAM_EV_BfrTime_NvalueSet 0;
BA_ "Version" SG_ 1219 BLTN_CAM_EV_BfrTime_NvalueSet "21.05.02";
BA_ "Description" SG_ 1219 BLTN_CAM_Rec_OWP_NvalueSet "Record On/Off Set of On While Parked, 0x0(Default) : Parking recording function not supported";
BA_ "GenSigSendType" SG_ 1219 BLTN_CAM_Rec_OWP_NvalueSet 4;
BA_ "UserSigValidity" SG_ 1219 BLTN_CAM_Rec_OWP_NvalueSet 0;
BA_REL_ "GenSigTimeoutTime" BU_SG_REL_ BLTN_CAM SG_ 1219 BLTN_CAM_Rec_OWP_NvalueSet 0;
BA_ "Version" SG_ 1219 BLTN_CAM_Rec_OWP_NvalueSet "21.05.02";
BA_ "Description" SG_ 1219 BLTN_CAM_EV_AftTime_NvalueSet "Driving Event Time Setting - After, Resolution : sec";
BA_ "GenSigSendType" SG_ 1219 BLTN_CAM_EV_AftTime_NvalueSet 4;
BA_ "UserSigValidity" SG_ 1219 BLTN_CAM_EV_AftTime_NvalueSet 0;
BA_REL_ "GenSigTimeoutTime" BU_SG_REL_ BLTN_CAM SG_ 1219 BLTN_CAM_EV_AftTime_NvalueSet 0;
BA_ "Version" SG_ 1219 BLTN_CAM_EV_AftTime_NvalueSet "21.05.02";
BA_ "Description" SG_ 1219 BLTN_CAM_TML_Int_NvalueSet "Record Set of Time-lapse Interval, Resolution : sec";
BA_ "GenSigSendType" SG_ 1219 BLTN_CAM_TML_Int_NvalueSet 4;
BA_ "UserSigValidity" SG_ 1219 BLTN_CAM_TML_Int_NvalueSet 0;
BA_REL_ "GenSigTimeoutTime" BU_SG_REL_ BLTN_CAM SG_ 1219 BLTN_CAM_TML_Int_NvalueSet 0;
BA_ "Version" SG_ 1219 BLTN_CAM_TML_Int_NvalueSet "21.05.02";
BA_ "Description" SG_ 1219 BLTN_CAM_Sen_DEV_NvalueSet "Set of Event  Detection Sensitivity of Driving Mode";
BA_ "GenSigSendType" SG_ 1219 BLTN_CAM_Sen_DEV_NvalueSet 4;
BA_ "UserSigValidity" SG_ 1219 BLTN_CAM_Sen_DEV_NvalueSet 0;
BA_REL_ "GenSigTimeoutTime" BU_SG_REL_ BLTN_CAM SG_ 1219 BLTN_CAM_Sen_DEV_NvalueSet 0;
BA_ "Version" SG_ 1219 BLTN_CAM_Sen_DEV_NvalueSet "21.05.02";
BA_ "Description" SG_ 1219 BLTN_CAM_Sen_PEV_NvalueSet "Set of Event  Detection Sensitivity of Parking Mode";
BA_ "GenSigSendType" SG_ 1219 BLTN_CAM_Sen_PEV_NvalueSet 4;
BA_ "UserSigValidity" SG_ 1219 BLTN_CAM_Sen_PEV_NvalueSet 0;
BA_REL_ "GenSigTimeoutTime" BU_SG_REL_ BLTN_CAM SG_ 1219 BLTN_CAM_Sen_PEV_NvalueSet 0;
BA_ "Version" SG_ 1219 BLTN_CAM_Sen_PEV_NvalueSet "21.05.02";
BA_ "Description" SG_ 1219 BLTN_CAM_Rec_PEV_NvalueSet "Record Set of Parked Event, 0x0(Default) : Parking recording function not supported";
BA_ "GenSigSendType" SG_ 1219 BLTN_CAM_Rec_PEV_NvalueSet 4;
BA_ "UserSigValidity" SG_ 1219 BLTN_CAM_Rec_PEV_NvalueSet 0;
BA_REL_ "GenSigTimeoutTime" BU_SG_REL_ BLTN_CAM SG_ 1219 BLTN_CAM_Rec_PEV_NvalueSet 0;
BA_ "Version" SG_ 1219 BLTN_CAM_Rec_PEV_NvalueSet "21.05.02";
BA_ "Description" SG_ 1219 BLTN_CAM_AudRec_NvalueSet "Audio Record On/Off Set";
BA_ "GenSigSendType" SG_ 1219 BLTN_CAM_AudRec_NvalueSet 4;
BA_ "UserSigValidity" SG_ 1219 BLTN_CAM_AudRec_NvalueSet 0;
BA_REL_ "GenSigTimeoutTime" BU_SG_REL_ BLTN_CAM SG_ 1219 BLTN_CAM_AudRec_NvalueSet 0;
BA_ "Version" SG_ 1219 BLTN_CAM_AudRec_NvalueSet "21.06.10";
BA_ "GenMsgCycleTime" BO_ 1221 0;
BA_ "Description" SG_ 1221 HU_ChgInCurrModSet "Charge current set signal";
BA_ "GenSigSendType" SG_ 1221 HU_ChgInCurrModSet 4;
BA_ "UserSigValidity" SG_ 1221 HU_ChgInCurrModSet 7;
BA_ "Version" SG_ 1221 HU_ChgInCurrModSet "19.08.06";
BA_ "Description" SG_ 1221 SWRC_Sensitivity_SET "This signal is for the SWRC Optical Switch Sensitivity Setting";
BA_ "GenSigSendType" SG_ 1221 SWRC_Sensitivity_SET 4;
BA_ "GenSigStartValue" SG_ 1221 SWRC_Sensitivity_SET 3;
BA_ "UserSigValidity" SG_ 1221 SWRC_Sensitivity_SET 3;
BA_REL_ "GenSigTimeoutTime" BU_SG_REL_ SWRC SG_ 1221 SWRC_Sensitivity_SET 0;
BA_ "Version" SG_ 1221 SWRC_Sensitivity_SET "19.12.00";
BA_ "Description" SG_ 1221 HU_EV_WinterMode "18.08.09_";
BA_ "GenSigSendType" SG_ 1221 HU_EV_WinterMode 4;
BA_ "GenSigStartValue" SG_ 1221 HU_EV_WinterMode 3;
BA_ "UserSigValidity" SG_ 1221 HU_EV_WinterMode 7;
BA_ "Version" SG_ 1221 HU_EV_WinterMode "18.09.04";
BA_ "Description" SG_ 1221 HU_TgSoc_ScChg_Set "18.08.09_";
BA_ "GenSigSendType" SG_ 1221 HU_TgSoc_ScChg_Set 4;
BA_ "GenSigStartValue" SG_ 1221 HU_TgSoc_ScChg_Set 255;
BA_ "UserSigValidity" SG_ 1221 HU_TgSoc_ScChg_Set 7;
BA_ "Version" SG_ 1221 HU_TgSoc_ScChg_Set "18.09.04";
BA_ "Description" SG_ 1221 HU_TgSoc_QcChg_Set "18.08.09_";
BA_ "GenSigSendType" SG_ 1221 HU_TgSoc_QcChg_Set 4;
BA_ "GenSigStartValue" SG_ 1221 HU_TgSoc_QcChg_Set 255;
BA_ "UserSigValidity" SG_ 1221 HU_TgSoc_QcChg_Set 7;
BA_ "Version" SG_ 1221 HU_TgSoc_QcChg_Set "18.09.04";
BA_ "Description" SG_ 1221 HU_UserApproval "Signal to send user decision on OTA approval.";
BA_ "GenSigSendType" SG_ 1221 HU_UserApproval 4;
BA_ "UserSigValidity" SG_ 1221 HU_UserApproval 0;
BA_ "Version" SG_ 1221 HU_UserApproval "21.03.01";
BA_ "Description" SG_ 1221 HU_OtaInfomationReq "Á¦¾î±â OTA °ü·Ã ÇÊ¿ä Á¤º¸¸¦ ¿äÃ»ÇÏ´Â ½ÅÈ£ (SW ¹öÀü, What's New, Download ÁøÇàÀ², Update ÁøÇàÀ²)";
BA_ "GenSigSendType" SG_ 1221 HU_OtaInfomationReq 4;
BA_ "UserSigValidity" SG_ 1221 HU_OtaInfomationReq 0;
BA_ "Version" SG_ 1221 HU_OtaInfomationReq "19.12.01";
BA_ "GenMsgSendType" BO_ 1076 0;
BA_ "GenSigSendType" SG_ 1076 IAU_ProfileIDRVal 4;
BA_ "UserSigValidity" SG_ 1076 IAU_ProfileIDRVal 0;
BA_REL_ "GenSigTimeoutTime" BU_SG_REL_ WPC SG_ 1076 IAU_ProfileIDRVal 1500;
BA_REL_ "GenSigTimeoutTime" BU_SG_REL_ RWPC SG_ 1076 IAU_ProfileIDRVal 1500;
BA_REL_ "GenSigTimeoutTime" BU_SG_REL_ DPSU SG_ 1076 IAU_ProfileIDRVal 1500;
BA_REL_ "GenSigTimeoutTime" BU_SG_REL_ BLTN_CAM SG_ 1076 IAU_ProfileIDRVal 1500;
BA_REL_ "GenSigTimeoutTime" BU_SG_REL_ SGU SG_ 1076 IAU_ProfileIDRVal 1500;
BA_ "NetworkRequest" SG_ 1076 IAU_ProfileIDRVal 0;
BA_ "NetworkRequestHoldingTime" SG_ 1076 IAU_ProfileIDRVal 5000;
BA_ "Version" SG_ 1076 IAU_ProfileIDRVal "20.05.02";
BA_ "GenSigSendType" SG_ 1076 IAU_DigitalKeyProcessingSta 4;
BA_ "UserSigValidity" SG_ 1076 IAU_DigitalKeyProcessingSta 3;
BA_ "NetworkRequest" SG_ 1076 IAU_DigitalKeyProcessingSta 0;
BA_ "NetworkRequestHoldingTime" SG_ 1076 IAU_DigitalKeyProcessingSta 5000;
BA_ "Version" SG_ 1076 IAU_DigitalKeyProcessingSta "20.11.02";
BA_ "Description" SG_ 1076 IAU_DigitalKeyExit "Digital Key USM setting Exit Condition";
BA_ "GenSigSendType" SG_ 1076 IAU_DigitalKeyExit 4;
BA_ "UserSigValidity" SG_ 1076 IAU_DigitalKeyExit 3;
BA_ "NetworkRequest" SG_ 1076 IAU_DigitalKeyExit 0;
BA_ "NetworkRequestHoldingTime" SG_ 1076 IAU_DigitalKeyExit 5000;
BA_ "Version" SG_ 1076 IAU_DigitalKeyExit "20.09.00";
BA_ "GenSigSendType" SG_ 1076 IAU_DigitalKeyEnblRVal 4;
BA_ "UserSigValidity" SG_ 1076 IAU_DigitalKeyEnblRVal 0;
BA_ "NetworkRequest" SG_ 1076 IAU_DigitalKeyEnblRVal 0;
BA_ "NetworkRequestHoldingTime" SG_ 1076 IAU_DigitalKeyEnblRVal 5000;
BA_ "Version" SG_ 1076 IAU_DigitalKeyEnblRVal "20.05.02";
BA_ "GenSigSendType" SG_ 1076 IAU_OwnerPhnRegRVal 4;
BA_ "UserSigValidity" SG_ 1076 IAU_OwnerPhnRegRVal 0;
BA_ "NetworkRequest" SG_ 1076 IAU_OwnerPhnRegRVal 0;
BA_ "NetworkRequestHoldingTime" SG_ 1076 IAU_OwnerPhnRegRVal 5000;
BA_ "Version" SG_ 1076 IAU_OwnerPhnRegRVal "20.05.02";
BA_ "GenSigSendType" SG_ 1076 IAU_NFCCard1RegRVal 4;
BA_ "UserSigValidity" SG_ 1076 IAU_NFCCard1RegRVal 0;
BA_ "NetworkRequest" SG_ 1076 IAU_NFCCard1RegRVal 0;
BA_ "NetworkRequestHoldingTime" SG_ 1076 IAU_NFCCard1RegRVal 5000;
BA_ "Version" SG_ 1076 IAU_NFCCard1RegRVal "17.12.08";
BA_ "GenSigSendType" SG_ 1076 IAU_NFCCard2RegRVal 4;
BA_ "UserSigValidity" SG_ 1076 IAU_NFCCard2RegRVal 0;
BA_ "NetworkRequest" SG_ 1076 IAU_NFCCard2RegRVal 0;
BA_ "NetworkRequestHoldingTime" SG_ 1076 IAU_NFCCard2RegRVal 5000;
BA_ "Version" SG_ 1076 IAU_NFCCard2RegRVal "17.12.08";
BA_ "Description" SG_ 1076 IAU_DISPWrng "This siganl warning from IAU";
BA_ "GenSigSendType" SG_ 1076 IAU_DISPWrng 4;
BA_ "UserSigValidity" SG_ 1076 IAU_DISPWrng 0;
BA_ "NetworkRequest" SG_ 1076 IAU_DISPWrng 0;
BA_ "NetworkRequestHoldingTime" SG_ 1076 IAU_DISPWrng 5000;
BA_ "Version" SG_ 1076 IAU_DISPWrng "20.08.07";
BA_ "Description" SG_ 1076 IAU_DigitalKey2Opt "This signal describe Digital Key capability";
BA_ "GenSigSendType" SG_ 1076 IAU_DigitalKey2Opt 4;
BA_ "UserSigValidity" SG_ 1076 IAU_DigitalKey2Opt 0;
BA_REL_ "GenSigTimeoutTime" BU_SG_REL_ WPC SG_ 1076 IAU_DigitalKey2Opt 1500;
BA_ "NetworkRequest" SG_ 1076 IAU_DigitalKey2Opt 0;
BA_ "NetworkRequestHoldingTime" SG_ 1076 IAU_DigitalKey2Opt 5000;
BA_ "Version" SG_ 1076 IAU_DigitalKey2Opt "20.08.00";
BA_ "Description" SG_ 1076 IAUwFRULearnState "This signal indicates learning process stste between IAU and FRU";
BA_ "GenSigSendType" SG_ 1076 IAUwFRULearnState 4;
BA_ "UserSigValidity" SG_ 1076 IAUwFRULearnState 0;
BA_ "NetworkRequest" SG_ 1076 IAUwFRULearnState 0;
BA_ "NetworkRequestHoldingTime" SG_ 1076 IAUwFRULearnState 5000;
BA_ "Version" SG_ 1076 IAUwFRULearnState "20.04.05";
BA_ "Description" SG_ 1076 IAUwFPMLearnState "This signal indicates learning process stste between IAU and FPM";
BA_ "GenSigSendType" SG_ 1076 IAUwFPMLearnState 4;
BA_ "UserSigValidity" SG_ 1076 IAUwFPMLearnState 0;
BA_ "NetworkRequest" SG_ 1076 IAUwFPMLearnState 0;
BA_ "NetworkRequestHoldingTime" SG_ 1076 IAUwFPMLearnState 5000;
BA_ "Version" SG_ 1076 IAUwFPMLearnState "20.04.05";
BA_ "GenMsgSendType" BO_ 1059 0;
BA_ "Description" SG_ 1059 PSU_DiagSta "(Old)C_PSU_DiagState";
BA_ "GenSigSendType" SG_ 1059 PSU_DiagSta 4;
BA_ "UserSigValidity" SG_ 1059 PSU_DiagSta 0;
BA_ "NetworkRequest" SG_ 1059 PSU_DiagSta 0;
BA_ "NetworkRequestHoldingTime" SG_ 1059 PSU_DiagSta 5000;
BA_ "Version" SG_ 1059 PSU_DiagSta "21.07.06";
BA_ "Description" SG_ 1059 Ast_2ndAutoRlxEnable "µ¿½Â¼® ½ÃÆ® À§Ä¡¿¡ µû¸¥ 2¿­ ¸±·º¼Ç µ¿ÀÛ °¡´É¿©ºÎ ÆÇ´Ü ½ÅÈ£";
BA_ "GenSigSendType" SG_ 1059 Ast_2ndAutoRlxEnable 4;
BA_ "UserSigValidity" SG_ 1059 Ast_2ndAutoRlxEnable 0;
BA_REL_ "GenSigTimeoutTime" BU_SG_REL_ RLPSU SG_ 1059 Ast_2ndAutoRlxEnable 1500;
BA_REL_ "GenSigTimeoutTime" BU_SG_REL_ RRPSU SG_ 1059 Ast_2ndAutoRlxEnable 1500;
BA_ "NetworkRequest" SG_ 1059 Ast_2ndAutoRlxEnable 0;
BA_ "NetworkRequestHoldingTime" SG_ 1059 Ast_2ndAutoRlxEnable 5000;
BA_ "Version" SG_ 1059 Ast_2ndAutoRlxEnable "21.06.10";
BA_ "Description" SG_ 1059 Ast_AutoRlxSta "µ¿½Â¼® ½ÃÆ® ¿ÀÅä ¸±·º¼Ç µ¿ÀÛ »óÅÂ Á¤º¸";
BA_ "GenSigSendType" SG_ 1059 Ast_AutoRlxSta 4;
BA_ "UserSigValidity" SG_ 1059 Ast_AutoRlxSta 0;
BA_REL_ "GenSigTimeoutTime" BU_SG_REL_ RLPSU SG_ 1059 Ast_AutoRlxSta 1500;
BA_REL_ "GenSigTimeoutTime" BU_SG_REL_ RRPSU SG_ 1059 Ast_AutoRlxSta 1500;
BA_ "NetworkRequest" SG_ 1059 Ast_AutoRlxSta 0;
BA_ "NetworkRequestHoldingTime" SG_ 1059 Ast_AutoRlxSta 5000;
BA_ "Version" SG_ 1059 Ast_AutoRlxSta "21.07.06";
BA_ "Description" SG_ 1059 PSU_EsyAcsGetOnSta "Easy Access Get On Information";
BA_ "GenSigSendType" SG_ 1059 PSU_EsyAcsGetOnSta 4;
BA_ "UserSigValidity" SG_ 1059 PSU_EsyAcsGetOnSta 0;
BA_REL_ "GenSigTimeoutTime" BU_SG_REL_ SLB SG_ 1059 PSU_EsyAcsGetOnSta 1500;
BA_ "NetworkRequest" SG_ 1059 PSU_EsyAcsGetOnSta 0;
BA_ "NetworkRequestHoldingTime" SG_ 1059 PSU_EsyAcsGetOnSta 5000;
BA_ "Version" SG_ 1059 PSU_EsyAcsGetOnSta "21.07.06";
BA_ "Description" SG_ 1059 PSU_EsyAcsGetOffSta "Easy Access Get Off Information";
BA_ "GenSigSendType" SG_ 1059 PSU_EsyAcsGetOffSta 4;
BA_ "UserSigValidity" SG_ 1059 PSU_EsyAcsGetOffSta 0;
BA_REL_ "GenSigTimeoutTime" BU_SG_REL_ SLB SG_ 1059 PSU_EsyAcsGetOffSta 1500;
BA_ "NetworkRequest" SG_ 1059 PSU_EsyAcsGetOffSta 0;
BA_ "NetworkRequestHoldingTime" SG_ 1059 PSU_EsyAcsGetOffSta 5000;
BA_ "Version" SG_ 1059 PSU_EsyAcsGetOffSta "21.07.06";
BA_ "Description" SG_ 1059 PSU_EsyAcsStpSta "Easy Access Stop Information";
BA_ "GenSigSendType" SG_ 1059 PSU_EsyAcsStpSta 4;
BA_ "UserSigValidity" SG_ 1059 PSU_EsyAcsStpSta 0;
BA_REL_ "GenSigTimeoutTime" BU_SG_REL_ SLB SG_ 1059 PSU_EsyAcsStpSta 1500;
BA_ "NetworkRequest" SG_ 1059 PSU_EsyAcsStpSta 0;
BA_ "NetworkRequestHoldingTime" SG_ 1059 PSU_EsyAcsStpSta 5000;
BA_ "Version" SG_ 1059 PSU_EsyAcsStpSta "21.07.06";
BA_ "GenSigSendType" SG_ 1059 PSU_RVal 4;
BA_ "UserSigValidity" SG_ 1059 PSU_RVal 0;
BA_ "NetworkRequest" SG_ 1059 PSU_RVal 0;
BA_ "NetworkRequestHoldingTime" SG_ 1059 PSU_RVal 5000;
BA_ "Version" SG_ 1059 PSU_RVal "21.07.06";
BA_ "GenMsgSendType" BO_ 1086 0;
BA_ "Description" SG_ 1086 RL_CURTAIN_POSITION "2¿­ ÁÂÃø À©µµ¿ì ±Û¶ó½º Ä¿Æ° À§Ä¡ Á¤º¸";
BA_ "GenSigSendType" SG_ 1086 RL_CURTAIN_POSITION 4;
BA_ "UserSigValidity" SG_ 1086 RL_CURTAIN_POSITION 0;
BA_REL_ "GenSigTimeoutTime" BU_SG_REL_ ATS SG_ 1086 RL_CURTAIN_POSITION 1500;
BA_ "NetworkRequest" SG_ 1086 RL_CURTAIN_POSITION 0;
BA_ "NetworkRequestHoldingTime" SG_ 1086 RL_CURTAIN_POSITION 5000;
BA_ "Version" SG_ 1086 RL_CURTAIN_POSITION "18.03.07";
BA_ "Description" SG_ 1086 RDC_SWVerMinor1 "Indicate the RDC software version as follows:

- The software version is displayed in three digits.

- The Major and Minor digits are separated by '.'

- Signal values are transmitted to ASCII codes.



¡Ø Example

RDC_SWVerMajor1 : 0x41 (HEX) -> ASCII CODE : 'A' 

RDC_SWVerMinor1 : 0x30 (HEX) -> ASCII CODE : '0'

RDC_SWVerMinor2 : 0x33 (HEX) -> ASCII CODE : '3'

=> RDC S/W Ver is displayed 'A.03'";
BA_ "GenSigSendType" SG_ 1086 RDC_SWVerMinor1 4;
BA_ "UserSigValidity" SG_ 1086 RDC_SWVerMinor1 0;
BA_ "Version" SG_ 1086 RDC_SWVerMinor1 "18.10.06";
BA_ "Description" SG_ 1086 RDC_SWVerMinor2 "Indicate the RDC software version as follows:

- The software version is displayed in three digits.

- The Major and Minor digits are separated by '.'

- Signal values are transmitted to ASCII codes.



¡Ø Example

RDC_SWVerMajor1 : 0x41 (HEX) -> ASCII CODE : 'A' 

RDC_SWVerMinor1 : 0x30 (HEX) -> ASCII CODE : '0'

RDC_SWVerMinor2 : 0x33 (HEX) -> ASCII CODE : '3'

=> RDC S/W Ver is displayed 'A.03'";
BA_ "GenSigSendType" SG_ 1086 RDC_SWVerMinor2 4;
BA_ "UserSigValidity" SG_ 1086 RDC_SWVerMinor2 0;
BA_ "Version" SG_ 1086 RDC_SWVerMinor2 "18.10.06";
BA_ "Description" SG_ 1086 RR_CURTAIN_POSITION "2¿­ ¿ìÃø À©µµ¿ì ±Û¶ó½º Ä¿Æ° À§Ä¡ Á¤º¸";
BA_ "GenSigSendType" SG_ 1086 RR_CURTAIN_POSITION 4;
BA_ "UserSigValidity" SG_ 1086 RR_CURTAIN_POSITION 0;
BA_REL_ "GenSigTimeoutTime" BU_SG_REL_ ATS SG_ 1086 RR_CURTAIN_POSITION 1500;
BA_ "NetworkRequest" SG_ 1086 RR_CURTAIN_POSITION 0;
BA_ "NetworkRequestHoldingTime" SG_ 1086 RR_CURTAIN_POSITION 5000;
BA_ "Version" SG_ 1086 RR_CURTAIN_POSITION "18.03.07";
BA_ "Description" SG_ 1086 RDC_RLDNInitFlag "Rear Left Door Curtain Down Initialized Finish Flag";
BA_ "GenSigSendType" SG_ 1086 RDC_RLDNInitFlag 4;
BA_ "UserSigValidity" SG_ 1086 RDC_RLDNInitFlag 0;
BA_ "NetworkRequest" SG_ 1086 RDC_RLDNInitFlag 0;
BA_ "NetworkRequestHoldingTime" SG_ 1086 RDC_RLDNInitFlag 5000;
BA_ "Version" SG_ 1086 RDC_RLDNInitFlag "21.01.08";
BA_ "Description" SG_ 1086 RDC_RRDNInitFlag "Rear Right Door Curtain Down Initialized Finish Flag";
BA_ "GenSigSendType" SG_ 1086 RDC_RRDNInitFlag 4;
BA_ "UserSigValidity" SG_ 1086 RDC_RRDNInitFlag 0;
BA_ "NetworkRequest" SG_ 1086 RDC_RRDNInitFlag 0;
BA_ "NetworkRequestHoldingTime" SG_ 1086 RDC_RRDNInitFlag 5000;
BA_ "Version" SG_ 1086 RDC_RRDNInitFlag "21.01.08";
BA_ "Description" SG_ 1086 RDC_RLOpState "Rear Left Door Curtain Operating State Feedback";
BA_ "GenSigSendType" SG_ 1086 RDC_RLOpState 4;
BA_ "UserSigValidity" SG_ 1086 RDC_RLOpState 0;
BA_ "NetworkRequest" SG_ 1086 RDC_RLOpState 0;
BA_ "NetworkRequestHoldingTime" SG_ 1086 RDC_RLOpState 5000;
BA_ "Version" SG_ 1086 RDC_RLOpState "21.01.08";
BA_ "Description" SG_ 1086 RDC_RROpState "Rear Right Door Curtain Operating State Feedback";
BA_ "GenSigSendType" SG_ 1086 RDC_RROpState 4;
BA_ "UserSigValidity" SG_ 1086 RDC_RROpState 0;
BA_ "NetworkRequest" SG_ 1086 RDC_RROpState 0;
BA_ "NetworkRequestHoldingTime" SG_ 1086 RDC_RROpState 5000;
BA_ "Version" SG_ 1086 RDC_RROpState "21.01.08";
BA_ "Description" SG_ 1086 RDC_OptTyp "RDC OPTION SIGNAL";
BA_ "GenSigSendType" SG_ 1086 RDC_OptTyp 4;
BA_ "UserSigValidity" SG_ 1086 RDC_OptTyp 0;
BA_REL_ "GenSigTimeoutTime" BU_SG_REL_ ATS SG_ 1086 RDC_OptTyp 1500;
BA_ "NetworkRequest" SG_ 1086 RDC_OptTyp 0;
BA_ "NetworkRequestHoldingTime" SG_ 1086 RDC_OptTyp 5000;
BA_ "Version" SG_ 1086 RDC_OptTyp "20.01.01";
BA_ "Description" SG_ 1086 RDC_SWVerMajor1 "Indicate the RDC software version as follows:

- The software version is displayed in three digits.

- The Major and Minor digits are separated by '.'

- Signal values are transmitted to ASCII codes.



¡Ø Example

RDC_SWVerMajor1 : 0x41 (HEX) -> ASCII CODE : 'A' 

RDC_SWVerMinor1 : 0x30 (HEX) -> ASCII CODE : '0'

RDC_SWVerMinor2 : 0x33 (HEX) -> ASCII CODE : '3'

=> RDC S/W Ver is displayed 'A.03'";
BA_ "GenSigSendType" SG_ 1086 RDC_SWVerMajor1 4;
BA_ "UserSigValidity" SG_ 1086 RDC_SWVerMajor1 0;
BA_ "Version" SG_ 1086 RDC_SWVerMajor1 "18.10.06";
BA_ "GenMsgSendType" BO_ 1080 0;
BA_ "Description" SG_ 1080 RL_SHVU_SeatOptSta "ÈÄ¼® LH ½ÃÆ®¿¡ Àû¿ëµÈ È÷ÅÍ/ÅëÇ³ ¿É¼Ç »ç¾ç";
BA_ "GenSigSendType" SG_ 1080 RL_SHVU_SeatOptSta 4;
BA_ "UserSigValidity" SG_ 1080 RL_SHVU_SeatOptSta 3;
BA_REL_ "GenSigTimeoutTime" BU_SG_REL_ ATS SG_ 1080 RL_SHVU_SeatOptSta 1500;
BA_REL_ "GenSigTimeoutTime" BU_SG_REL_ CGW_CCU SG_ 1080 RL_SHVU_SeatOptSta 1500;
BA_ "NetworkRequest" SG_ 1080 RL_SHVU_SeatOptSta 0;
BA_ "NetworkRequestHoldingTime" SG_ 1080 RL_SHVU_SeatOptSta 5000;
BA_ "Version" SG_ 1080 RL_SHVU_SeatOptSta "17.12.03";
BA_ "Description" SG_ 1080 RL_SHVU_SeatHtOperSta "ÈÄ¼® LH ½ÃÆ® ÇöÀç ÀÛµ¿ ÁßÀÎ È÷ÅÍ/ÅëÇ³ ´Ü¼ö »óÅÂ";
BA_ "GenSigSendType" SG_ 1080 RL_SHVU_SeatHtOperSta 4;
BA_ "UserSigValidity" SG_ 1080 RL_SHVU_SeatHtOperSta 3;
BA_REL_ "GenSigTimeoutTime" BU_SG_REL_ ATS SG_ 1080 RL_SHVU_SeatHtOperSta 1500;
BA_REL_ "GenSigTimeoutTime" BU_SG_REL_ CGW_CCU SG_ 1080 RL_SHVU_SeatHtOperSta 1500;
BA_ "NetworkRequest" SG_ 1080 RL_SHVU_SeatHtOperSta 0;
BA_ "NetworkRequestHoldingTime" SG_ 1080 RL_SHVU_SeatHtOperSta 5000;
BA_ "Version" SG_ 1080 RL_SHVU_SeatHtOperSta "21.07.06";
BA_ "Description" SG_ 1080 RL_SHVU_HtSwHiIndSta_RHD "RL ½ÃÆ® ¿­¼± ½ºÀ§Ä¡ High Indicator Á¤º¸ (RHD)

-2nd LH Seat heater high Information";
BA_ "GenSigSendType" SG_ 1080 RL_SHVU_HtSwHiIndSta_RHD 4;
BA_ "UserSigValidity" SG_ 1080 RL_SHVU_HtSwHiIndSta_RHD 3;
BA_REL_ "GenSigTimeoutTime" BU_SG_REL_ ATS SG_ 1080 RL_SHVU_HtSwHiIndSta_RHD 1500;
BA_REL_ "GenSigTimeoutTime" BU_SG_REL_ CGW_CCU SG_ 1080 RL_SHVU_HtSwHiIndSta_RHD 1500;
BA_REL_ "GenSigTimeoutTime" BU_SG_REL_ CGW_CCU SG_ 1080 RL_SHVU_HtSwHiIndSta_RHD 1500;
BA_ "NetworkRequest" SG_ 1080 RL_SHVU_HtSwHiIndSta_RHD 0;
BA_ "NetworkRequestHoldingTime" SG_ 1080 RL_SHVU_HtSwHiIndSta_RHD 5000;
BA_ "Version" SG_ 1080 RL_SHVU_HtSwHiIndSta_RHD "19.08.05";
BA_ "Description" SG_ 1080 RL_SHVU_HtSwMidIndSta_RHD "RL ½ÃÆ® ¿­¼± ½ºÀ§Ä¡ Mid Indicator Á¤º¸ (RHD)

-2nd LH Seat heater mid Information";
BA_ "GenSigSendType" SG_ 1080 RL_SHVU_HtSwMidIndSta_RHD 4;
BA_ "UserSigValidity" SG_ 1080 RL_SHVU_HtSwMidIndSta_RHD 3;
BA_REL_ "GenSigTimeoutTime" BU_SG_REL_ ATS SG_ 1080 RL_SHVU_HtSwMidIndSta_RHD 1500;
BA_REL_ "GenSigTimeoutTime" BU_SG_REL_ CGW_CCU SG_ 1080 RL_SHVU_HtSwMidIndSta_RHD 1500;
BA_ "NetworkRequest" SG_ 1080 RL_SHVU_HtSwMidIndSta_RHD 0;
BA_ "NetworkRequestHoldingTime" SG_ 1080 RL_SHVU_HtSwMidIndSta_RHD 5000;
BA_ "Version" SG_ 1080 RL_SHVU_HtSwMidIndSta_RHD "19.08.05";
BA_ "Description" SG_ 1080 RL_SHVU_HtSwLowIndSta_RHD "RL ½ÃÆ® ¿­¼± ½ºÀ§Ä¡ Low Indicator Á¤º¸ (RHD)

-2nd LH Seat heater low Information";
BA_ "GenSigSendType" SG_ 1080 RL_SHVU_HtSwLowIndSta_RHD 4;
BA_ "UserSigValidity" SG_ 1080 RL_SHVU_HtSwLowIndSta_RHD 3;
BA_REL_ "GenSigTimeoutTime" BU_SG_REL_ ATS SG_ 1080 RL_SHVU_HtSwLowIndSta_RHD 1500;
BA_REL_ "GenSigTimeoutTime" BU_SG_REL_ CGW_CCU SG_ 1080 RL_SHVU_HtSwLowIndSta_RHD 1500;
BA_ "NetworkRequest" SG_ 1080 RL_SHVU_HtSwLowIndSta_RHD 0;
BA_ "NetworkRequestHoldingTime" SG_ 1080 RL_SHVU_HtSwLowIndSta_RHD 5000;
BA_ "Version" SG_ 1080 RL_SHVU_HtSwLowIndSta_RHD "19.08.05";
BA_ "Description" SG_ 1080 RL_SHVU_VntSwHiIndSta_RHD "RL ½ÃÆ® ÅëÇ³ ½ºÀ§Ä¡ High Indicator Á¤º¸ (RHD)

-2nd LH Seat vent high Information";
BA_ "GenSigSendType" SG_ 1080 RL_SHVU_VntSwHiIndSta_RHD 4;
BA_ "UserSigValidity" SG_ 1080 RL_SHVU_VntSwHiIndSta_RHD 3;
BA_REL_ "GenSigTimeoutTime" BU_SG_REL_ ATS SG_ 1080 RL_SHVU_VntSwHiIndSta_RHD 1500;
BA_REL_ "GenSigTimeoutTime" BU_SG_REL_ CGW_CCU SG_ 1080 RL_SHVU_VntSwHiIndSta_RHD 1500;
BA_ "NetworkRequest" SG_ 1080 RL_SHVU_VntSwHiIndSta_RHD 0;
BA_ "NetworkRequestHoldingTime" SG_ 1080 RL_SHVU_VntSwHiIndSta_RHD 5000;
BA_ "Version" SG_ 1080 RL_SHVU_VntSwHiIndSta_RHD "19.08.05";
BA_ "Description" SG_ 1080 RL_SHVU_VntSwMidIndSta_RHD "RL ½ÃÆ® ÅëÇ³ ½ºÀ§Ä¡ Mid Indicator Á¤º¸ (RHD)

-2nd LH Seat vent mid Information";
BA_ "GenSigSendType" SG_ 1080 RL_SHVU_VntSwMidIndSta_RHD 4;
BA_ "UserSigValidity" SG_ 1080 RL_SHVU_VntSwMidIndSta_RHD 3;
BA_REL_ "GenSigTimeoutTime" BU_SG_REL_ ATS SG_ 1080 RL_SHVU_VntSwMidIndSta_RHD 1500;
BA_REL_ "GenSigTimeoutTime" BU_SG_REL_ CGW_CCU SG_ 1080 RL_SHVU_VntSwMidIndSta_RHD 1500;
BA_ "NetworkRequest" SG_ 1080 RL_SHVU_VntSwMidIndSta_RHD 0;
BA_ "NetworkRequestHoldingTime" SG_ 1080 RL_SHVU_VntSwMidIndSta_RHD 5000;
BA_ "Version" SG_ 1080 RL_SHVU_VntSwMidIndSta_RHD "19.08.05";
BA_ "Description" SG_ 1080 RL_SHVU_VntSwLowIndSta_RHD "RL ½ÃÆ® ÅëÇ³ ½ºÀ§Ä¡ Low Indicator Á¤º¸ (RHD)

-2nd LH Seat vent low Information";
BA_ "GenSigSendType" SG_ 1080 RL_SHVU_VntSwLowIndSta_RHD 4;
BA_ "UserSigValidity" SG_ 1080 RL_SHVU_VntSwLowIndSta_RHD 3;
BA_REL_ "GenSigTimeoutTime" BU_SG_REL_ ATS SG_ 1080 RL_SHVU_VntSwLowIndSta_RHD 1500;
BA_REL_ "GenSigTimeoutTime" BU_SG_REL_ CGW_CCU SG_ 1080 RL_SHVU_VntSwLowIndSta_RHD 1500;
BA_ "NetworkRequest" SG_ 1080 RL_SHVU_VntSwLowIndSta_RHD 0;
BA_ "NetworkRequestHoldingTime" SG_ 1080 RL_SHVU_VntSwLowIndSta_RHD 5000;
BA_ "Version" SG_ 1080 RL_SHVU_VntSwLowIndSta_RHD "19.08.05";
BA_ "Description" SG_ 1080 RL_SHVU_HtBlcUsmSta_RHD "RL Seat Heater Balance Status(RHD)";
BA_ "GenSigSendType" SG_ 1080 RL_SHVU_HtBlcUsmSta_RHD 4;
BA_ "UserSigValidity" SG_ 1080 RL_SHVU_HtBlcUsmSta_RHD 3;
BA_REL_ "GenSigTimeoutTime" BU_SG_REL_ ATS SG_ 1080 RL_SHVU_HtBlcUsmSta_RHD 1500;
BA_REL_ "GenSigTimeoutTime" BU_SG_REL_ CGW_CCU SG_ 1080 RL_SHVU_HtBlcUsmSta_RHD 1500;
BA_ "NetworkRequest" SG_ 1080 RL_SHVU_HtBlcUsmSta_RHD 0;
BA_ "NetworkRequestHoldingTime" SG_ 1080 RL_SHVU_HtBlcUsmSta_RHD 5000;
BA_ "Version" SG_ 1080 RL_SHVU_HtBlcUsmSta_RHD "20.01.02";
BA_ "GenMsgSendType" BO_ 1073 0;
BA_ "Description" SG_ 1073 USM_ValCmdSta "USM request value of RWPC";
BA_ "GenSigSendType" SG_ 1073 USM_ValCmdSta 4;
BA_ "UserSigValidity" SG_ 1073 USM_ValCmdSta 0;
BA_REL_ "GenSigTimeoutTime" BU_SG_REL_ ATS SG_ 1073 USM_ValCmdSta 1500;
BA_REL_ "GenSigTimeoutTime" BU_SG_REL_ CGW_CCU SG_ 1073 USM_ValCmdSta 1500;
BA_ "NetworkRequest" SG_ 1073 USM_ValCmdSta 0;
BA_ "NetworkRequestHoldingTime" SG_ 1073 USM_ValCmdSta 5000;
BA_ "Version" SG_ 1073 USM_ValCmdSta "17.11.00";
BA_ "Description" SG_ 1073 RWPC_SWVerMinor1 "Indicate the RWPC software version as follows:

- The software version is displayed in three digits.

- The Major and Minor digits are separated by '.'

- Signal values are transmitted to ASCII codes.



¡Ø Example

RWPC_SWVerMajor1 : 0x41 (HEX) -> ASCII CODE : 'A' 

RWPC_SWVerMinor1 : 0x30 (HEX) -> ASCII CODE : '0'

RWPC_SWVerMinor2 : 0x33 (HEX) -> ASCII CODE : '3'

=> RWPC S/W Ver is displayed 'A.03'";
BA_ "GenSigSendType" SG_ 1073 RWPC_SWVerMinor1 4;
BA_ "UserSigValidity" SG_ 1073 RWPC_SWVerMinor1 0;
BA_REL_ "GenSigTimeoutTime" BU_SG_REL_ CGW_CCU SG_ 1073 RWPC_SWVerMinor1 1500;
BA_ "Version" SG_ 1073 RWPC_SWVerMinor1 "18.10.06";
BA_ "Description" SG_ 1073 WPC_PhnLftWrngRWPCSta "Warning by RWPC for User (Phone left in vehicle)";
BA_ "GenSigSendType" SG_ 1073 WPC_PhnLftWrngRWPCSta 4;
BA_ "UserSigValidity" SG_ 1073 WPC_PhnLftWrngRWPCSta 0;
BA_REL_ "GenSigTimeoutTime" BU_SG_REL_ ATS SG_ 1073 WPC_PhnLftWrngRWPCSta 1500;
BA_REL_ "GenSigTimeoutTime" BU_SG_REL_ CGW_CCU SG_ 1073 WPC_PhnLftWrngRWPCSta 1500;
BA_ "NetworkRequest" SG_ 1073 WPC_PhnLftWrngRWPCSta 0;
BA_ "NetworkRequestHoldingTime" SG_ 1073 WPC_PhnLftWrngRWPCSta 5000;
BA_ "Version" SG_ 1073 WPC_PhnLftWrngRWPCSta "19.10.02";
BA_ "Description" SG_ 1073 RWPC_SWVerMinor2 "Indicate the RWPC software version as follows:

- The software version is displayed in three digits.

- The Major and Minor digits are separated by '.'

- Signal values are transmitted to ASCII codes.



¡Ø Example

RWPC_SWVerMajor1 : 0x41 (HEX) -> ASCII CODE : 'A' 

RWPC_SWVerMinor1 : 0x30 (HEX) -> ASCII CODE : '0'

RWPC_SWVerMinor2 : 0x33 (HEX) -> ASCII CODE : '3'

=> RWPC S/W Ver is displayed 'A.03'";
BA_ "GenSigSendType" SG_ 1073 RWPC_SWVerMinor2 4;
BA_ "UserSigValidity" SG_ 1073 RWPC_SWVerMinor2 0;
BA_REL_ "GenSigTimeoutTime" BU_SG_REL_ CGW_CCU SG_ 1073 RWPC_SWVerMinor2 1500;
BA_ "Version" SG_ 1073 RWPC_SWVerMinor2 "18.10.06";
BA_ "Description" SG_ 1073 USM_ValCmdStaforATS "USM request value of RWPC for ATS";
BA_ "GenSigSendType" SG_ 1073 USM_ValCmdStaforATS 4;
BA_ "UserSigValidity" SG_ 1073 USM_ValCmdStaforATS 0;
BA_REL_ "GenSigTimeoutTime" BU_SG_REL_ ATS SG_ 1073 USM_ValCmdStaforATS 1500;
BA_ "NetworkRequest" SG_ 1073 USM_ValCmdStaforATS 0;
BA_ "NetworkRequestHoldingTime" SG_ 1073 USM_ValCmdStaforATS 5000;
BA_ "Version" SG_ 1073 USM_ValCmdStaforATS "20.07.05";
BA_ "Description" SG_ 1073 RWPC_SWVerMajor1 "Indicate the RWPC software version as follows:

- The software version is displayed in three digits.

- The Major and Minor digits are separated by '.'

- Signal values are transmitted to ASCII codes.



¡Ø Example

RWPC_SWVerMajor1 : 0x41 (HEX) -> ASCII CODE : 'A' 

RWPC_SWVerMinor1 : 0x30 (HEX) -> ASCII CODE : '0'

RWPC_SWVerMinor2 : 0x33 (HEX) -> ASCII CODE : '3'

=> RWPC S/W Ver is displayed 'A.03'";
BA_ "GenSigSendType" SG_ 1073 RWPC_SWVerMajor1 4;
BA_ "UserSigValidity" SG_ 1073 RWPC_SWVerMajor1 0;
BA_REL_ "GenSigTimeoutTime" BU_SG_REL_ CGW_CCU SG_ 1073 RWPC_SWVerMajor1 1500;
BA_ "Version" SG_ 1073 RWPC_SWVerMajor1 "18.10.06";
BA_ "GenMsgSendType" BO_ 139 0;
BA_ "Description" SG_ 139 SWRC_Crc5Val "The data area for CRC calculation is based on the data length (DLC) of the message DB.

The CRC shall be calculated over the entire data block (excluding the CRC bytes) including the user data, alive counter and Data ID 

 

- CRC Polynomial (0x1D) , Initial Value : 0x00, XOR value : 0xFF, Data ID Mode : Both, Data ID : Message ID + 0xF800 

- The initial value is for CRC calculation and the message should be sent with the calculated result value. 

The mathematical expression to 8 bit CRC polynomial is given here. G(x) = x8 + x4 + x3 + x2 + 1";
BA_ "GenSigSendType" SG_ 139 SWRC_Crc5Val 4;
BA_ "GenSigStartValue" SG_ 139 SWRC_Crc5Val 255;
BA_ "UserSigValidity" SG_ 139 SWRC_Crc5Val 3;
BA_REL_ "GenSigTimeoutTime" BU_SG_REL_ CGW_CCU SG_ 139 SWRC_Crc5Val 1500;
BA_ "Version" SG_ 139 SWRC_Crc5Val "20.04.06";
BA_ "Description" SG_ 139 SWRC_AlvCnt5Val "For the first transmission request for a data element the counter shall be initialized with 0 and shall be incremented by 1

for every subsequent send request. When the counter reaches the maximum value(0xE), then it shall restart with 0 for the next send request";
BA_ "GenSigSendType" SG_ 139 SWRC_AlvCnt5Val 4;
BA_ "UserSigValidity" SG_ 139 SWRC_AlvCnt5Val 3;
BA_REL_ "GenSigTimeoutTime" BU_SG_REL_ CGW_CCU SG_ 139 SWRC_AlvCnt5Val 1500;
BA_ "Version" SG_ 139 SWRC_AlvCnt5Val "20.04.06";
BA_ "Description" SG_ 139 SWRC_DriveModCWSwSta "Drive Mode Switch Status Clockwise(right)";
BA_ "GenSigSendType" SG_ 139 SWRC_DriveModCWSwSta 4;
BA_ "UserSigValidity" SG_ 139 SWRC_DriveModCWSwSta 0;
BA_REL_ "GenSigTimeoutTime" BU_SG_REL_ CGW_CCU SG_ 139 SWRC_DriveModCWSwSta 1500;
BA_ "NetworkRequest" SG_ 139 SWRC_DriveModCWSwSta 0;
BA_ "NetworkRequestHoldingTime" SG_ 139 SWRC_DriveModCWSwSta 5000;
BA_ "Version" SG_ 139 SWRC_DriveModCWSwSta "20.01.01";
BA_ "Description" SG_ 139 SWRC_DriveModCCWSwSta "Drive Mode Switch Status CounterClockWise (Left)";
BA_ "GenSigSendType" SG_ 139 SWRC_DriveModCCWSwSta 4;
BA_ "UserSigValidity" SG_ 139 SWRC_DriveModCCWSwSta 0;
BA_REL_ "GenSigTimeoutTime" BU_SG_REL_ CGW_CCU SG_ 139 SWRC_DriveModCCWSwSta 1500;
BA_ "NetworkRequest" SG_ 139 SWRC_DriveModCCWSwSta 0;
BA_ "NetworkRequestHoldingTime" SG_ 139 SWRC_DriveModCCWSwSta 5000;
BA_ "Version" SG_ 139 SWRC_DriveModCCWSwSta "20.01.01";
BA_ "Description" SG_ 139 SWRC_BoostSwSta "Boost Switch Status";
BA_ "GenSigSendType" SG_ 139 SWRC_BoostSwSta 4;
BA_ "UserSigValidity" SG_ 139 SWRC_BoostSwSta 0;
BA_REL_ "GenSigTimeoutTime" BU_SG_REL_ CGW_CCU SG_ 139 SWRC_BoostSwSta 1500;
BA_ "NetworkRequest" SG_ 139 SWRC_BoostSwSta 0;
BA_ "NetworkRequestHoldingTime" SG_ 139 SWRC_BoostSwSta 5000;
BA_ "Version" SG_ 139 SWRC_BoostSwSta "19.12.08";
BA_ "Description" SG_ 139 SWRC_DriveModeSwSta "Drive Mode Switch Status (Push Type)";
BA_ "GenSigSendType" SG_ 139 SWRC_DriveModeSwSta 4;
BA_ "UserSigValidity" SG_ 139 SWRC_DriveModeSwSta 0;
BA_REL_ "GenSigTimeoutTime" BU_SG_REL_ CGW_CCU SG_ 139 SWRC_DriveModeSwSta 1500;
BA_ "Version" SG_ 139 SWRC_DriveModeSwSta "20.03.05";
BA_ "Description" SG_ 139 SWRC_TerrainModeSwSta "Terrain Mode Switch Status (Push Type)";
BA_ "GenSigSendType" SG_ 139 SWRC_TerrainModeSwSta 4;
BA_ "UserSigValidity" SG_ 139 SWRC_TerrainModeSwSta 0;
BA_REL_ "GenSigTimeoutTime" BU_SG_REL_ CGW_CCU SG_ 139 SWRC_TerrainModeSwSta 1500;
BA_ "Version" SG_ 139 SWRC_TerrainModeSwSta "21.09.02";
BA_ "Description" SG_ 139 SWRC_N1SwSta "N Vehicle SWRC N1 Switch signal";
BA_ "GenSigSendType" SG_ 139 SWRC_N1SwSta 4;
BA_ "UserSigValidity" SG_ 139 SWRC_N1SwSta 0;
BA_REL_ "GenSigTimeoutTime" BU_SG_REL_ CGW_CCU SG_ 139 SWRC_N1SwSta 1500;
BA_ "NetworkRequest" SG_ 139 SWRC_N1SwSta 0;
BA_ "NetworkRequestHoldingTime" SG_ 139 SWRC_N1SwSta 5000;
BA_ "Version" SG_ 139 SWRC_N1SwSta "21.11.06";
BA_ "Description" SG_ 139 SWRC_N2SwSta "N Vehicle SWRC N2 Switch signal";
BA_ "GenSigSendType" SG_ 139 SWRC_N2SwSta 4;
BA_ "UserSigValidity" SG_ 139 SWRC_N2SwSta 0;
BA_REL_ "GenSigTimeoutTime" BU_SG_REL_ CGW_CCU SG_ 139 SWRC_N2SwSta 1500;
BA_ "NetworkRequest" SG_ 139 SWRC_N2SwSta 0;
BA_ "NetworkRequestHoldingTime" SG_ 139 SWRC_N2SwSta 5000;
BA_ "Version" SG_ 139 SWRC_N2SwSta "21.11.06";
BA_ "GenMsgCycleTime" BO_ 1567 0;
BA_ "GenMsgCycleTimeFast" BO_ 1567 0;
BA_ "GenMsgNrOfRepetition" BO_ 1567 0;
BA_ "GenMsgILSupport" BO_ 1567 0;
BA_ "TpMessage" BO_ 1567 1;
BA_ "TpTxIndex" BO_ 1567 41;
BA_ "Description" SG_ 1567 TP_BLTN_CAM_NAVI_HU_Byte0 "TP Index : 41";
BA_ "UsrSigPurpose" SG_ 1567 TP_BLTN_CAM_NAVI_HU_Byte0 10;
BA_ "UserSigValidity" SG_ 1567 TP_BLTN_CAM_NAVI_HU_Byte0 0;
BA_REL_ "GenSigTimeoutTime" BU_SG_REL_ CGW_CCU SG_ 1567 TP_BLTN_CAM_NAVI_HU_Byte0 0;
BA_ "NetworkRequest" SG_ 1567 TP_BLTN_CAM_NAVI_HU_Byte0 0;
BA_ "NetworkRequestHoldingTime" SG_ 1567 TP_BLTN_CAM_NAVI_HU_Byte0 5000;
BA_ "Version" SG_ 1567 TP_BLTN_CAM_NAVI_HU_Byte0 "21.05.04";
BA_ "Description" SG_ 1567 TP_BLTN_CAM_NAVI_HU_Byte2 "TP Index : 41";
BA_ "UsrSigPurpose" SG_ 1567 TP_BLTN_CAM_NAVI_HU_Byte2 10;
BA_ "UserSigValidity" SG_ 1567 TP_BLTN_CAM_NAVI_HU_Byte2 0;
BA_REL_ "GenSigTimeoutTime" BU_SG_REL_ CGW_CCU SG_ 1567 TP_BLTN_CAM_NAVI_HU_Byte2 0;
BA_ "NetworkRequest" SG_ 1567 TP_BLTN_CAM_NAVI_HU_Byte2 0;
BA_ "NetworkRequestHoldingTime" SG_ 1567 TP_BLTN_CAM_NAVI_HU_Byte2 5000;
BA_ "Version" SG_ 1567 TP_BLTN_CAM_NAVI_HU_Byte2 "21.05.04";
BA_ "Description" SG_ 1567 TP_BLTN_CAM_NAVI_HU_Byte3 "TP Index : 41";
BA_ "UsrSigPurpose" SG_ 1567 TP_BLTN_CAM_NAVI_HU_Byte3 10;
BA_ "UserSigValidity" SG_ 1567 TP_BLTN_CAM_NAVI_HU_Byte3 0;
BA_REL_ "GenSigTimeoutTime" BU_SG_REL_ CGW_CCU SG_ 1567 TP_BLTN_CAM_NAVI_HU_Byte3 0;
BA_ "NetworkRequest" SG_ 1567 TP_BLTN_CAM_NAVI_HU_Byte3 0;
BA_ "NetworkRequestHoldingTime" SG_ 1567 TP_BLTN_CAM_NAVI_HU_Byte3 5000;
BA_ "Version" SG_ 1567 TP_BLTN_CAM_NAVI_HU_Byte3 "21.05.04";
BA_ "Description" SG_ 1567 TP_BLTN_CAM_NAVI_HU_Byte4 "TP Index : 41";
BA_ "UsrSigPurpose" SG_ 1567 TP_BLTN_CAM_NAVI_HU_Byte4 10;
BA_ "UserSigValidity" SG_ 1567 TP_BLTN_CAM_NAVI_HU_Byte4 0;
BA_REL_ "GenSigTimeoutTime" BU_SG_REL_ CGW_CCU SG_ 1567 TP_BLTN_CAM_NAVI_HU_Byte4 0;
BA_ "NetworkRequest" SG_ 1567 TP_BLTN_CAM_NAVI_HU_Byte4 0;
BA_ "NetworkRequestHoldingTime" SG_ 1567 TP_BLTN_CAM_NAVI_HU_Byte4 5000;
BA_ "Version" SG_ 1567 TP_BLTN_CAM_NAVI_HU_Byte4 "21.05.04";
BA_ "Description" SG_ 1567 TP_BLTN_CAM_NAVI_HU_Byte5 "TP Index : 41";
BA_ "UsrSigPurpose" SG_ 1567 TP_BLTN_CAM_NAVI_HU_Byte5 10;
BA_ "UserSigValidity" SG_ 1567 TP_BLTN_CAM_NAVI_HU_Byte5 0;
BA_REL_ "GenSigTimeoutTime" BU_SG_REL_ CGW_CCU SG_ 1567 TP_BLTN_CAM_NAVI_HU_Byte5 0;
BA_ "NetworkRequest" SG_ 1567 TP_BLTN_CAM_NAVI_HU_Byte5 0;
BA_ "NetworkRequestHoldingTime" SG_ 1567 TP_BLTN_CAM_NAVI_HU_Byte5 5000;
BA_ "Version" SG_ 1567 TP_BLTN_CAM_NAVI_HU_Byte5 "21.05.04";
BA_ "Description" SG_ 1567 TP_BLTN_CAM_NAVI_HU_Byte6 "TP Index : 41";
BA_ "UsrSigPurpose" SG_ 1567 TP_BLTN_CAM_NAVI_HU_Byte6 10;
BA_ "UserSigValidity" SG_ 1567 TP_BLTN_CAM_NAVI_HU_Byte6 0;
BA_REL_ "GenSigTimeoutTime" BU_SG_REL_ CGW_CCU SG_ 1567 TP_BLTN_CAM_NAVI_HU_Byte6 0;
BA_ "NetworkRequest" SG_ 1567 TP_BLTN_CAM_NAVI_HU_Byte6 0;
BA_ "NetworkRequestHoldingTime" SG_ 1567 TP_BLTN_CAM_NAVI_HU_Byte6 5000;
BA_ "Version" SG_ 1567 TP_BLTN_CAM_NAVI_HU_Byte6 "21.05.04";
BA_ "Description" SG_ 1567 TP_BLTN_CAM_NAVI_HU_Byte7 "TP Index : 41";
BA_ "UsrSigPurpose" SG_ 1567 TP_BLTN_CAM_NAVI_HU_Byte7 10;
BA_ "UserSigValidity" SG_ 1567 TP_BLTN_CAM_NAVI_HU_Byte7 0;
BA_REL_ "GenSigTimeoutTime" BU_SG_REL_ CGW_CCU SG_ 1567 TP_BLTN_CAM_NAVI_HU_Byte7 0;
BA_ "NetworkRequest" SG_ 1567 TP_BLTN_CAM_NAVI_HU_Byte7 0;
BA_ "NetworkRequestHoldingTime" SG_ 1567 TP_BLTN_CAM_NAVI_HU_Byte7 5000;
BA_ "Version" SG_ 1567 TP_BLTN_CAM_NAVI_HU_Byte7 "21.05.04";
BA_ "Description" SG_ 1567 TP_BLTN_CAM_NAVI_HU_Byte1 "TP Index : 41";
BA_ "UsrSigPurpose" SG_ 1567 TP_BLTN_CAM_NAVI_HU_Byte1 10;
BA_ "UserSigValidity" SG_ 1567 TP_BLTN_CAM_NAVI_HU_Byte1 0;
BA_REL_ "GenSigTimeoutTime" BU_SG_REL_ CGW_CCU SG_ 1567 TP_BLTN_CAM_NAVI_HU_Byte1 0;
BA_ "NetworkRequest" SG_ 1567 TP_BLTN_CAM_NAVI_HU_Byte1 0;
BA_ "NetworkRequestHoldingTime" SG_ 1567 TP_BLTN_CAM_NAVI_HU_Byte1 5000;
BA_ "Version" SG_ 1567 TP_BLTN_CAM_NAVI_HU_Byte1 "21.05.04";
BA_ "GenMsgCycleTime" BO_ 1566 0;
BA_ "GenMsgCycleTimeFast" BO_ 1566 0;
BA_ "GenMsgNrOfRepetition" BO_ 1566 0;
BA_ "GenMsgILSupport" BO_ 1566 0;
BA_ "TpMessage" BO_ 1566 1;
BA_ "TpTxIndex" BO_ 1566 41;
BA_ "Description" SG_ 1566 TP_HU_NAVI_BLTN_CAM_Byte0 "TP Index : 41";
BA_ "UsrSigPurpose" SG_ 1566 TP_HU_NAVI_BLTN_CAM_Byte0 10;
BA_ "UserSigValidity" SG_ 1566 TP_HU_NAVI_BLTN_CAM_Byte0 0;
BA_REL_ "GenSigTimeoutTime" BU_SG_REL_ BLTN_CAM SG_ 1566 TP_HU_NAVI_BLTN_CAM_Byte0 0;
BA_ "NetworkRequest" SG_ 1566 TP_HU_NAVI_BLTN_CAM_Byte0 0;
BA_ "NetworkRequestHoldingTime" SG_ 1566 TP_HU_NAVI_BLTN_CAM_Byte0 5000;
BA_ "Version" SG_ 1566 TP_HU_NAVI_BLTN_CAM_Byte0 "21.05.04";
BA_ "Description" SG_ 1566 TP_HU_NAVI_BLTN_CAM_Byte2 "TP Index : 41";
BA_ "UsrSigPurpose" SG_ 1566 TP_HU_NAVI_BLTN_CAM_Byte2 10;
BA_ "UserSigValidity" SG_ 1566 TP_HU_NAVI_BLTN_CAM_Byte2 0;
BA_REL_ "GenSigTimeoutTime" BU_SG_REL_ BLTN_CAM SG_ 1566 TP_HU_NAVI_BLTN_CAM_Byte2 0;
BA_ "NetworkRequest" SG_ 1566 TP_HU_NAVI_BLTN_CAM_Byte2 0;
BA_ "NetworkRequestHoldingTime" SG_ 1566 TP_HU_NAVI_BLTN_CAM_Byte2 5000;
BA_ "Version" SG_ 1566 TP_HU_NAVI_BLTN_CAM_Byte2 "21.05.04";
BA_ "Description" SG_ 1566 TP_HU_NAVI_BLTN_CAM_Byte3 "TP Index : 41";
BA_ "UsrSigPurpose" SG_ 1566 TP_HU_NAVI_BLTN_CAM_Byte3 10;
BA_ "UserSigValidity" SG_ 1566 TP_HU_NAVI_BLTN_CAM_Byte3 0;
BA_REL_ "GenSigTimeoutTime" BU_SG_REL_ BLTN_CAM SG_ 1566 TP_HU_NAVI_BLTN_CAM_Byte3 0;
BA_ "NetworkRequest" SG_ 1566 TP_HU_NAVI_BLTN_CAM_Byte3 0;
BA_ "NetworkRequestHoldingTime" SG_ 1566 TP_HU_NAVI_BLTN_CAM_Byte3 5000;
BA_ "Version" SG_ 1566 TP_HU_NAVI_BLTN_CAM_Byte3 "21.05.04";
BA_ "Description" SG_ 1566 TP_HU_NAVI_BLTN_CAM_Byte4 "TP Index : 41";
BA_ "UsrSigPurpose" SG_ 1566 TP_HU_NAVI_BLTN_CAM_Byte4 10;
BA_ "UserSigValidity" SG_ 1566 TP_HU_NAVI_BLTN_CAM_Byte4 0;
BA_REL_ "GenSigTimeoutTime" BU_SG_REL_ BLTN_CAM SG_ 1566 TP_HU_NAVI_BLTN_CAM_Byte4 0;
BA_ "NetworkRequest" SG_ 1566 TP_HU_NAVI_BLTN_CAM_Byte4 0;
BA_ "NetworkRequestHoldingTime" SG_ 1566 TP_HU_NAVI_BLTN_CAM_Byte4 5000;
BA_ "Version" SG_ 1566 TP_HU_NAVI_BLTN_CAM_Byte4 "21.05.04";
BA_ "Description" SG_ 1566 TP_HU_NAVI_BLTN_CAM_Byte5 "TP Index : 41";
BA_ "UsrSigPurpose" SG_ 1566 TP_HU_NAVI_BLTN_CAM_Byte5 10;
BA_ "UserSigValidity" SG_ 1566 TP_HU_NAVI_BLTN_CAM_Byte5 0;
BA_REL_ "GenSigTimeoutTime" BU_SG_REL_ BLTN_CAM SG_ 1566 TP_HU_NAVI_BLTN_CAM_Byte5 0;
BA_ "NetworkRequest" SG_ 1566 TP_HU_NAVI_BLTN_CAM_Byte5 0;
BA_ "NetworkRequestHoldingTime" SG_ 1566 TP_HU_NAVI_BLTN_CAM_Byte5 5000;
BA_ "Version" SG_ 1566 TP_HU_NAVI_BLTN_CAM_Byte5 "21.05.04";
BA_ "Description" SG_ 1566 TP_HU_NAVI_BLTN_CAM_Byte6 "TP Index : 41";
BA_ "UsrSigPurpose" SG_ 1566 TP_HU_NAVI_BLTN_CAM_Byte6 10;
BA_ "UserSigValidity" SG_ 1566 TP_HU_NAVI_BLTN_CAM_Byte6 0;
BA_REL_ "GenSigTimeoutTime" BU_SG_REL_ BLTN_CAM SG_ 1566 TP_HU_NAVI_BLTN_CAM_Byte6 0;
BA_ "NetworkRequest" SG_ 1566 TP_HU_NAVI_BLTN_CAM_Byte6 0;
BA_ "NetworkRequestHoldingTime" SG_ 1566 TP_HU_NAVI_BLTN_CAM_Byte6 5000;
BA_ "Version" SG_ 1566 TP_HU_NAVI_BLTN_CAM_Byte6 "21.05.04";
BA_ "Description" SG_ 1566 TP_HU_NAVI_BLTN_CAM_Byte7 "TP Index : 41";
BA_ "UsrSigPurpose" SG_ 1566 TP_HU_NAVI_BLTN_CAM_Byte7 10;
BA_ "UserSigValidity" SG_ 1566 TP_HU_NAVI_BLTN_CAM_Byte7 0;
BA_REL_ "GenSigTimeoutTime" BU_SG_REL_ BLTN_CAM SG_ 1566 TP_HU_NAVI_BLTN_CAM_Byte7 0;
BA_ "NetworkRequest" SG_ 1566 TP_HU_NAVI_BLTN_CAM_Byte7 0;
BA_ "NetworkRequestHoldingTime" SG_ 1566 TP_HU_NAVI_BLTN_CAM_Byte7 5000;
BA_ "Version" SG_ 1566 TP_HU_NAVI_BLTN_CAM_Byte7 "21.05.04";
BA_ "Description" SG_ 1566 TP_HU_NAVI_BLTN_CAM_Byte1 "TP Index : 41";
BA_ "UsrSigPurpose" SG_ 1566 TP_HU_NAVI_BLTN_CAM_Byte1 10;
BA_ "UserSigValidity" SG_ 1566 TP_HU_NAVI_BLTN_CAM_Byte1 0;
BA_REL_ "GenSigTimeoutTime" BU_SG_REL_ BLTN_CAM SG_ 1566 TP_HU_NAVI_BLTN_CAM_Byte1 0;
BA_ "NetworkRequest" SG_ 1566 TP_HU_NAVI_BLTN_CAM_Byte1 0;
BA_ "NetworkRequestHoldingTime" SG_ 1566 TP_HU_NAVI_BLTN_CAM_Byte1 5000;
BA_ "Version" SG_ 1566 TP_HU_NAVI_BLTN_CAM_Byte1 "21.05.04";
BA_ "GenMsgSendType" BO_ 2160080129 0;
BA_ "GenMsgCycleTime" BO_ 2160080129 50;
BA_ "GenMsgCycleTimeFast" BO_ 2160080129 0;
BA_ "GenMsgNrOfRepetition" BO_ 2160080129 0;
BA_ "VFrameFormat" BO_ 2160080129 1;
BA_ "Description" SG_ 2160080129 VCU_Crc1Val "The data area for CRC calculation is based on the data length (DLC) of the message DB.

The CRC shall be calculated over the entire data block (excluding the CRC bytes) including the user data, alive counter and Data ID

 

- CRC Polynomial (0x1021) , Initial Value : 0xFFFF, XOR value : 0x0000, Data ID : Message ID + 0xF800 

- The initial value is for CRC calculation and the message should be sent with the calculated result value. 

- The mathematical expression to 16 bit CRC polynomial is given here. G(x) = x16 + x12 + x5 + 1";
BA_ "GenSigStartValue" SG_ 2160080129 VCU_Crc1Val 65535;
BA_ "UserSigValidity" SG_ 2160080129 VCU_Crc1Val 7;
BA_ "RoutingFactor" SG_ 2160080129 VCU_Crc1Val 5;
BA_ "Version" SG_ 2160080129 VCU_Crc1Val "20.07.05";
BA_ "Description" SG_ 2160080129 VCU_AlvCnt1Val "For the first transmission request for a data element the counter shall be initialized with 0 and shall be incremented by 1 for every subsequent send request. 

When the counter reaches the maximum value(0xFF), then it shall restart with 0 for the next send request";
BA_ "UserSigValidity" SG_ 2160080129 VCU_AlvCnt1Val 7;
BA_ "RoutingFactor" SG_ 2160080129 VCU_AlvCnt1Val 5;
BA_ "Version" SG_ 2160080129 VCU_AlvCnt1Val "20.07.05";
BA_ "Description" SG_ 2160080129 VCU_RdySta "VCU Ready";
BA_ "UserSigValidity" SG_ 2160080129 VCU_RdySta 7;
BA_ "RoutingFactor" SG_ 2160080129 VCU_RdySta 5;
BA_ "Version" SG_ 2160080129 VCU_RdySta "20.04.05";
BA_ "Description" SG_ 2160080129 VCU_StartKeyHoldSta "Start Key Hold Signal";
BA_ "UserSigValidity" SG_ 2160080129 VCU_StartKeyHoldSta 7;
BA_ "RoutingFactor" SG_ 2160080129 VCU_StartKeyHoldSta 5;
BA_ "Version" SG_ 2160080129 VCU_StartKeyHoldSta "20.04.05";
BA_ "Description" SG_ 2160080129 VCU_EvDrvRdySta "EV Ready";
BA_ "UserSigValidity" SG_ 2160080129 VCU_EvDrvRdySta 7;
BA_ "RoutingFactor" SG_ 2160080129 VCU_EvDrvRdySta 5;
BA_ "Version" SG_ 2160080129 VCU_EvDrvRdySta "20.04.05";
BA_ "Description" SG_ 2160080129 VCU_MotPwrEnReq "Motor Power Enable";
BA_ "UserSigValidity" SG_ 2160080129 VCU_MotPwrEnReq 7;
BA_ "RoutingFactor" SG_ 2160080129 VCU_MotPwrEnReq 5;
BA_ "Version" SG_ 2160080129 VCU_MotPwrEnReq "20.04.05";
BA_ "Description" SG_ 2160080129 VCU_GearPosSta "Gear Position Status";
BA_ "GenSigStartValue" SG_ 2160080129 VCU_GearPosSta 9;
BA_ "UserSigValidity" SG_ 2160080129 VCU_GearPosSta 7;
BA_ "RoutingFactor" SG_ 2160080129 VCU_GearPosSta 5;
BA_ "Version" SG_ 2160080129 VCU_GearPosSta "21.05.01";
BA_ "Description" SG_ 2160080129 VCU_LdcInhReq "LDC Output Inhibit Request";
BA_ "GenSigStartValue" SG_ 2160080129 VCU_LdcInhReq 1;
BA_ "UserSigValidity" SG_ 2160080129 VCU_LdcInhReq 7;
BA_ "RoutingFactor" SG_ 2160080129 VCU_LdcInhReq 5;
BA_ "Version" SG_ 2160080129 VCU_LdcInhReq "20.04.05";
BA_ "Description" SG_ 2160080129 VCU_MainRlyOffReq "Main Relay Cut off Request";
BA_ "UserSigValidity" SG_ 2160080129 VCU_MainRlyOffReq 7;
BA_ "RoutingFactor" SG_ 2160080129 VCU_MainRlyOffReq 5;
BA_ "Version" SG_ 2160080129 VCU_MainRlyOffReq "20.04.05";
BA_ "Description" SG_ 2160080129 VCU_AccPedDepVal "Accelerator Pedal Depth Value";
BA_ "UserSigValidity" SG_ 2160080129 VCU_AccPedDepVal 7;
BA_ "RoutingFactor" SG_ 2160080129 VCU_AccPedDepVal 5;
BA_ "Version" SG_ 2160080129 VCU_AccPedDepVal "20.04.05";
BA_ "Description" SG_ 2160080129 VCU_FatcOperPermSta "Climate Operating Permission";
BA_ "UserSigValidity" SG_ 2160080129 VCU_FatcOperPermSta 7;
BA_ "RoutingFactor" SG_ 2160080129 VCU_FatcOperPermSta 5;
BA_ "Version" SG_ 2160080129 VCU_FatcOperPermSta "20.04.05";
BA_ "Description" SG_ 2160080129 VCU_DrvCycSta "Driving Cycle Status";
BA_ "UserSigValidity" SG_ 2160080129 VCU_DrvCycSta 7;
BA_ "RoutingFactor" SG_ 2160080129 VCU_DrvCycSta 5;
BA_ "Version" SG_ 2160080129 VCU_DrvCycSta "20.04.05";
BA_ "Description" SG_ 2160080129 VCU_CltActOpSta "Clutch Actuator Operating Status";
BA_ "UserSigValidity" SG_ 2160080129 VCU_CltActOpSta 7;
BA_ "RoutingFactor" SG_ 2160080129 VCU_CltActOpSta 5;
BA_ "Version" SG_ 2160080129 VCU_CltActOpSta "20.04.05";
BA_ "Description" SG_ 2160080129 VCU_WhlSpdSnsrAlvReq "Alive Request for Wheel Speed Sensors";
BA_ "UserSigValidity" SG_ 2160080129 VCU_WhlSpdSnsrAlvReq 7;
BA_ "RoutingFactor" SG_ 2160080129 VCU_WhlSpdSnsrAlvReq 5;
BA_ "Version" SG_ 2160080129 VCU_WhlSpdSnsrAlvReq "20.04.05";
BA_ "Description" SG_ 2160080129 VCU_DrvModOpSta "VCU's operating drive mode according to CLU and DMIC signals";
BA_ "UserSigValidity" SG_ 2160080129 VCU_DrvModOpSta 7;
BA_ "RoutingFactor" SG_ 2160080129 VCU_DrvModOpSta 5;
BA_ "Version" SG_ 2160080129 VCU_DrvModOpSta "20.08.07";
BA_ "Description" SG_ 2160080129 VCU_IgOffGearPosStaDispReq "Gear position display request @ Ig Off (to CLU )";
BA_ "UserSigValidity" SG_ 2160080129 VCU_IgOffGearPosStaDispReq 7;
BA_ "RoutingFactor" SG_ 2160080129 VCU_IgOffGearPosStaDispReq 5;
BA_ "Version" SG_ 2160080129 VCU_IgOffGearPosStaDispReq "20.12.04";
BA_ "GenMsgSendType" BO_ 2160080130 0;
BA_ "GenMsgCycleTime" BO_ 2160080130 50;
BA_ "GenMsgCycleTimeFast" BO_ 2160080130 0;
BA_ "GenMsgNrOfRepetition" BO_ 2160080130 0;
BA_ "VFrameFormat" BO_ 2160080130 1;
BA_ "Description" SG_ 2160080130 VCU_FatcPwrUseVal "Predicted HVAC Power Consumption";
BA_ "UserSigValidity" SG_ 2160080130 VCU_FatcPwrUseVal 7;
BA_ "RoutingFactor" SG_ 2160080130 VCU_FatcPwrUseVal 5;
BA_ "Version" SG_ 2160080130 VCU_FatcPwrUseVal "20.04.05";
BA_ "Description" SG_ 2160080130 VCU_McuAntiJerkInhFrntSta "Anti-jerk Inhibition";
BA_ "GenSigStartValue" SG_ 2160080130 VCU_McuAntiJerkInhFrntSta 1;
BA_ "UserSigValidity" SG_ 2160080130 VCU_McuAntiJerkInhFrntSta 7;
BA_ "RoutingFactor" SG_ 2160080130 VCU_McuAntiJerkInhFrntSta 5;
BA_ "Version" SG_ 2160080130 VCU_McuAntiJerkInhFrntSta "20.04.05";
BA_ "Description" SG_ 2160080130 VCU_McuAntiJerkInhRearSta "Anti-jerk Inhibition";
BA_ "GenSigStartValue" SG_ 2160080130 VCU_McuAntiJerkInhRearSta 1;
BA_ "UserSigValidity" SG_ 2160080130 VCU_McuAntiJerkInhRearSta 7;
BA_ "RoutingFactor" SG_ 2160080130 VCU_McuAntiJerkInhRearSta 5;
BA_ "Version" SG_ 2160080130 VCU_McuAntiJerkInhRearSta "20.04.05";
BA_ "Description" SG_ 2160080130 VCU_McuPwrLatchHoldReq "Mcu Power Latch Hold Request";
BA_ "UserSigValidity" SG_ 2160080130 VCU_McuPwrLatchHoldReq 7;
BA_ "RoutingFactor" SG_ 2160080130 VCU_McuPwrLatchHoldReq 5;
BA_ "Version" SG_ 2160080130 VCU_McuPwrLatchHoldReq "20.04.05";
BA_ "Description" SG_ 2160080130 VCU_ScuParkReq "Parking Command Request";
BA_ "UserSigValidity" SG_ 2160080130 VCU_ScuParkReq 7;
BA_ "RoutingFactor" SG_ 2160080130 VCU_ScuParkReq 5;
BA_ "Version" SG_ 2160080130 VCU_ScuParkReq "20.04.05";
BA_ "Description" SG_ 2160080130 VCU_MotTqCmdFrntVal "Torque Command for Front Motor";
BA_ "UserSigValidity" SG_ 2160080130 VCU_MotTqCmdFrntVal 7;
BA_ "RoutingFactor" SG_ 2160080130 VCU_MotTqCmdFrntVal 5;
BA_ "Version" SG_ 2160080130 VCU_MotTqCmdFrntVal "20.04.05";
BA_ "Description" SG_ 2160080130 VCU_ScuKeepWakeReq "SCU Keep Wake Request";
BA_ "UserSigValidity" SG_ 2160080130 VCU_ScuKeepWakeReq 7;
BA_ "RoutingFactor" SG_ 2160080130 VCU_ScuKeepWakeReq 5;
BA_ "Version" SG_ 2160080130 VCU_ScuKeepWakeReq "20.04.05";
BA_ "Description" SG_ 2160080130 VCU_MotTqCmdRearVal "Torque Command for Rear Motor";
BA_ "UserSigValidity" SG_ 2160080130 VCU_MotTqCmdRearVal 7;
BA_ "RoutingFactor" SG_ 2160080130 VCU_MotTqCmdRearVal 5;
BA_ "Version" SG_ 2160080130 VCU_MotTqCmdRearVal "20.04.05";
BA_ "Description" SG_ 2160080130 VCU_FmcuZeroTqOfsReq "Fmcu Zero Torque Offset Request";
BA_ "UserSigValidity" SG_ 2160080130 VCU_FmcuZeroTqOfsReq 7;
BA_ "RoutingFactor" SG_ 2160080130 VCU_FmcuZeroTqOfsReq 5;
BA_ "Version" SG_ 2160080130 VCU_FmcuZeroTqOfsReq "20.04.05";
BA_ "Description" SG_ 2160080130 VCU_WhlDemTqVal "Driver's Demand Torque Restricted by Battery Limit and HHT Temperature";
BA_ "UserSigValidity" SG_ 2160080130 VCU_WhlDemTqVal 7;
BA_ "RoutingFactor" SG_ 2160080130 VCU_WhlDemTqVal 5;
BA_ "Version" SG_ 2160080130 VCU_WhlDemTqVal "20.04.05";
BA_ "GenMsgSendType" BO_ 2160080131 0;
BA_ "GenMsgCycleTime" BO_ 2160080131 50;
BA_ "GenMsgCycleTimeFast" BO_ 2160080131 0;
BA_ "GenMsgNrOfRepetition" BO_ 2160080131 0;
BA_ "VFrameFormat" BO_ 2160080131 1;
BA_ "Description" SG_ 2160080131 VCU_EcmSeqSta "This signal is VCU System Status Information.";
BA_ "UserSigValidity" SG_ 2160080131 VCU_EcmSeqSta 7;
BA_ "RoutingFactor" SG_ 2160080131 VCU_EcmSeqSta 5;
BA_ "Version" SG_ 2160080131 VCU_EcmSeqSta "20.04.05";
BA_ "Description" SG_ 2160080131 VCU_CltActDiagSta "Clutch Actuator Diag Code";
BA_ "UserSigValidity" SG_ 2160080131 VCU_CltActDiagSta 7;
BA_ "RoutingFactor" SG_ 2160080131 VCU_CltActDiagSta 5;
BA_ "Version" SG_ 2160080131 VCU_CltActDiagSta "20.04.05";
BA_ "Description" SG_ 2160080131 VCU_CltActDrvCrntVal "Clutch Actuator Drive Current";
BA_ "UserSigValidity" SG_ 2160080131 VCU_CltActDrvCrntVal 7;
BA_ "RoutingFactor" SG_ 2160080131 VCU_CltActDrvCrntVal 5;
BA_ "Version" SG_ 2160080131 VCU_CltActDrvCrntVal "20.04.05";
BA_ "Description" SG_ 2160080131 VCU_CltActPosStrokeVal "Clutch Actuator Position Stroke";
BA_ "UserSigValidity" SG_ 2160080131 VCU_CltActPosStrokeVal 7;
BA_ "RoutingFactor" SG_ 2160080131 VCU_CltActPosStrokeVal 5;
BA_ "Version" SG_ 2160080131 VCU_CltActPosStrokeVal "20.04.05";
BA_ "Description" SG_ 2160080131 VCU_MainBattTypeSta "Main Battery Type";
BA_ "UserSigValidity" SG_ 2160080131 VCU_MainBattTypeSta 7;
BA_ "RoutingFactor" SG_ 2160080131 VCU_MainBattTypeSta 5;
BA_ "Version" SG_ 2160080131 VCU_MainBattTypeSta "20.08.07";
BA_ "Description" SG_ 2160080131 VCU_MainBattTypeLrnSta "Learn Status of Main Batt. Type";
BA_ "UserSigValidity" SG_ 2160080131 VCU_MainBattTypeLrnSta 7;
BA_ "RoutingFactor" SG_ 2160080131 VCU_MainBattTypeLrnSta 5;
BA_ "Version" SG_ 2160080131 VCU_MainBattTypeLrnSta "20.04.05";
BA_ "Description" SG_ 2160080131 VCU_WarmupCycSta "Warm-up Cycle Status Flag for FRF output to other ECU's";
BA_ "UserSigValidity" SG_ 2160080131 VCU_WarmupCycSta 7;
BA_ "RoutingFactor" SG_ 2160080131 VCU_WarmupCycSta 5;
BA_ "Version" SG_ 2160080131 VCU_WarmupCycSta "20.04.05";
BA_ "Description" SG_ 2160080131 VCU_FatcPermPwrVal "Climate Permission Power";
BA_ "UserSigValidity" SG_ 2160080131 VCU_FatcPermPwrVal 7;
BA_ "RoutingFactor" SG_ 2160080131 VCU_FatcPermPwrVal 5;
BA_ "Version" SG_ 2160080131 VCU_FatcPermPwrVal "20.04.05";
BA_ "UserSigValidity" SG_ 2160080131 VCU_EcmDiagSta 7;
BA_ "RoutingFactor" SG_ 2160080131 VCU_EcmDiagSta 5;
BA_ "Version" SG_ 2160080131 VCU_EcmDiagSta "20.04.05";
BA_ "GenMsgSendType" BO_ 2160080132 0;
BA_ "GenMsgCycleTime" BO_ 2160080132 50;
BA_ "GenMsgCycleTimeFast" BO_ 2160080132 0;
BA_ "GenMsgNrOfRepetition" BO_ 2160080132 0;
BA_ "VFrameFormat" BO_ 2160080132 1;
BA_ "Description" SG_ 2160080132 VCU_GearPosStaDisp "Gear Position Status for CLU display";
BA_ "GenSigStartValue" SG_ 2160080132 VCU_GearPosStaDisp 9;
BA_ "UserSigValidity" SG_ 2160080132 VCU_GearPosStaDisp 7;
BA_ "RoutingFactor" SG_ 2160080132 VCU_GearPosStaDisp 5;
BA_ "Version" SG_ 2160080132 VCU_GearPosStaDisp "20.12.04";
BA_ "UserSigValidity" SG_ 2160080132 VCU_PdwLmtOperSta 7;
BA_ "RoutingFactor" SG_ 2160080132 VCU_PdwLmtOperSta 5;
BA_ "Version" SG_ 2160080132 VCU_PdwLmtOperSta "21.12.00";
BA_ "UserSigValidity" SG_ 2160080132 VCU_PdwLmtBrkRequest 7;
BA_ "RoutingFactor" SG_ 2160080132 VCU_PdwLmtBrkRequest 5;
BA_ "Version" SG_ 2160080132 VCU_PdwLmtBrkRequest "21.12.00";
BA_ "Description" SG_ 2160080132 VCU_VgsVirSoundBackFireIndex "Virtual sound back fire noise index for VGS mode";
BA_ "UserSigValidity" SG_ 2160080132 VCU_VgsVirSoundBackFireIndex 7;
BA_ "RoutingFactor" SG_ 2160080132 VCU_VgsVirSoundBackFireIndex 5;
BA_ "Version" SG_ 2160080132 VCU_VgsVirSoundBackFireIndex "21.12.02";
BA_ "Description" SG_ 2160080132 VCU_VgsVirEngSpdRpmVal "Virtual engine speed for VGS mode";
BA_ "UserSigValidity" SG_ 2160080132 VCU_VgsVirEngSpdRpmVal 7;
BA_ "RoutingFactor" SG_ 2160080132 VCU_VgsVirEngSpdRpmVal 5;
BA_ "Version" SG_ 2160080132 VCU_VgsVirEngSpdRpmVal "21.12.02";
BA_ "Description" SG_ 2160080132 VCU_VgsVirSoundVolume "Virtual engine sound volume for VGS mode[%]";
BA_ "UserSigValidity" SG_ 2160080132 VCU_VgsVirSoundVolume 7;
BA_ "RoutingFactor" SG_ 2160080132 VCU_VgsVirSoundVolume 5;
BA_ "Version" SG_ 2160080132 VCU_VgsVirSoundVolume "21.12.02";
BA_ "Description" SG_ 2160080132 VCU_VgsVirGearStep "Shift gear when entering VGS mode";
BA_ "UserSigValidity" SG_ 2160080132 VCU_VgsVirGearStep 7;
BA_ "RoutingFactor" SG_ 2160080132 VCU_VgsVirGearStep 5;
BA_ "Version" SG_ 2160080132 VCU_VgsVirGearStep "21.12.02";
VAL_ 140 ATS_DATC_FrPsModeSet 0 "Reserved" 1 "Vent" 2 "BL" 3 "Floor" 4 "Reserved" 5 "Reserved" 6 "Reserved" 7 "Reserved" 8 "Reserved" 9 "Reserved" 10 "Reserved" 11 "Reserved" 12 "Reserved" 13 "Reserved" 14 "Reserved" 15 "Invalid" ;
VAL_ 140 ATS_DATC_FrPsAutoSet 0 "reserved" 1 "AUTO ON" 2 "reserved" 3 "Invalid" ;
VAL_ 140 ATS_DATC_FrPsBlowerSet 0 "DATC Off" 1 "0 level (Do not use)" 2 "1 level" 3 "2 level" 4 "3 level" 5 "4 level" 6 "5 level" 7 "6 level" 8 "7 level" 9 "8 level" 15 "Invalid" ;
VAL_ 140 ATS_DATC_FrPsBlowerUpDn 0 "Reserved" 1 "Up" 2 "Down" 3 "Invalid" ;
VAL_ 140 ATS_DATC_FrDrMultiAutoBlower 0 "Reserved" 1 "Low" 2 "Medium" 3 "High" 4 "Reserved" 5 "Reserved" 6 "Reserved" 7 "Invalid" ;
VAL_ 140 ATS_DATC_FrPsMultiAutoBlower 0 "Reserved" 1 "Low" 2 "Medium" 3 "High" 4 "Reserved" 5 "Reserved" 6 "Reserved" 7 "Invalid" ;
VAL_ 140 ATS_DATC_RrDrMultiAutoBlower 0 "Reserved" 1 "Low" 2 "Medium" 3 "High" 4 "Reserved" 5 "Reserved" 6 "Reserved" 7 "Invalid" ;
VAL_ 140 ATS_DATC_FragranceStrhSet 0 "Default" 1 "Off" 2 "Low" 3 "Medium" 4 "High" 5 "Reserved" 6 "Reserved" 7 "Invalid" ;
VAL_ 140 ATS_DATC_FragranceKindSet 0 "Default" 1 "First" 2 "Second" 3 "Reserved" 4 "Reserved" 5 "Reserved" 6 "Reserved" 7 "Invalid" ;
VAL_ 140 ATS_DATC_FragranceBttnMnlSet 0 "Default" 1 "Off" 2 "On" 3 "Invalid" ;
VAL_ 140 ATS_DATC_TempUnitSet 0 "Off" 1 "¢ªC (Centigrade)" 2 "¢ªF (Fahrenheit)" 3 "Invalid" ;
VAL_ 591 ATS_RLStSldFwdBtn 0 "Default" 1 "Off" 2 "On" 3 "Reserved" ;
VAL_ 591 ATS_RLStSldBwdBtn 0 "Default" 1 "Off" 2 "On" 3 "Reserved" ;
VAL_ 591 ATS_RLStRclFwdBtn 0 "Default" 1 "Off" 2 "On" 3 "Reserved" ;
VAL_ 591 ATS_RLStRclBwdBtn 0 "Default" 1 "Off" 2 "On" 3 "Reserved" ;
VAL_ 591 ATS_RLStTltUpBtn 0 "Default" 1 "Off" 2 "On" 3 "Reserved" ;
VAL_ 591 ATS_RLStTltDnBtn 0 "Default" 1 "Off" 2 "On" 3 "Reserved" ;
VAL_ 591 ATS_RLStHRestUpBtn 0 "Default" 1 "Off" 2 "On" 3 "Reserved" ;
VAL_ 591 ATS_RLStHRestDnBtn 0 "Default" 1 "Off" 2 "On" 3 "Reserved" ;
VAL_ 591 ATS_RLStHRestFwdBtn 0 "Default" 1 "Off" 2 "On" 3 "Reserved" ;
VAL_ 591 ATS_RLStHRestBwdBtn 0 "Default" 1 "Off" 2 "On" 3 "Reserved" ;
VAL_ 591 ATS_RLStLegRestUpBtn 0 "Default" 1 "Off" 2 "On" 3 "Reserved" ;
VAL_ 591 ATS_RStLegRestDnBtn 0 "Default" 1 "Off" 2 "On" 3 "Reserved" ;
VAL_ 591 ATS_RLStLegRestExtUpBtn 0 "Default" 1 "Off" 2 "On" 3 "Reserved" ;
VAL_ 591 ATS_RLStLegRestExtDnBtn 0 "Default" 1 "Off" 2 "On" 3 "Reserved" ;
VAL_ 591 ATS_RLStShoulderADJFwdBtn 0 "Default" 1 "Off" 2 "On" 3 "Reserved" ;
VAL_ 591 ATS_RLStShoulderADJBwdBtn 0 "Default" 1 "Off" 2 "On" 3 "Reserved" ;
VAL_ 607 ATS_RRStSldFwdBtn 0 "Default" 1 "Off" 2 "On" 3 "Reserved" ;
VAL_ 607 ATS_RRStSldBwdBtn 0 "Default" 1 "Off" 2 "On" 3 "Reserved" ;
VAL_ 607 ATS_RRStRclFwdBtn 0 "Default" 1 "Off" 2 "On" 3 "Reserved" ;
VAL_ 607 ATS_RRStRclBwdBtn 0 "Default" 1 "Off" 2 "On" 3 "Reserved" ;
VAL_ 607 ATS_RRStTltUpBtn 0 "Default" 1 "Off" 2 "On" 3 "Reserved" ;
VAL_ 607 ATS_RRStTltDnBtn 0 "Default" 1 "Off" 2 "On" 3 "Reserved" ;
VAL_ 607 ATS_RRStLegRestPopBtn 0 "Default" 1 "Off" 2 "On" 3 "Reserved" ;
VAL_ 607 ATS_RRStFRestPopBtn 0 "Default" 1 "Off" 2 "On" 3 "Reserved" ;
VAL_ 607 ATS_RRStAstPopBtn 0 "Default" 1 "Off" 2 "On" 3 "Reserved" ;
VAL_ 607 ATS_RRFauCondiBtn 0 "Default" 1 "Off" 2 "On" 3 "Reserved" ;
VAL_ 607 ATS_RRStHRestUpBtn 0 "Default" 1 "Off" 2 "On" 3 "Reserved" ;
VAL_ 607 ATS_RRStHRestDnBtn 0 "Default" 1 "Off" 2 "On" 3 "Reserved" ;
VAL_ 607 ATS_RRStHRestFwdBtn 0 "Default" 1 "Off" 2 "On" 3 "Reserved" ;
VAL_ 607 ATS_RRStHRestBwdBtn 0 "Default" 1 "Off" 2 "On" 3 "Reserved" ;
VAL_ 607 ATS_RRStShoulderADJFwdBtn 0 "Default" 1 "Off" 2 "On" 3 "Reserved" ;
VAL_ 607 ATS_RRStShoulderADJBwdBtn 0 "Default" 1 "Off" 2 "On" 3 "Reserved" ;
VAL_ 607 ATS_RRStLegRestUpBtn 0 "Default" 1 "Off" 2 "On" 3 "Reserved" ;
VAL_ 607 ATS_RRStLegRestDnBtn 0 "Default" 1 "Off" 2 "On" 3 "Reserved" ;
VAL_ 607 ATS_RRStLegRestExtUpBtn 0 "Default" 1 "Off" 2 "On" 3 "Reserved" ;
VAL_ 607 ATS_RRStLegRestExtDnBtn 0 "Default" 1 "Off" 2 "On" 3 "Reserved" ;
VAL_ 1216 PHEV_FuelDrReleaseSwSta 0 "Off" 1 "On" 2 "Not Used" 3 "Error Indicator" ;
VAL_ 1216 StrWhlWrmr_MKBDBpReq 0 "Beep Off" 1 "Beep On" 2 "Not Used" 3 "Error Indicator" ;
VAL_ 1216 BckGls_RrGlsHtdMKBDBpReq 0 "Beep Off" 1 "Beep On" 2 "Not Used" 3 "Error Indicator" ;
VAL_ 1216 Wndshld_FrtGlsHtdMKBDBpReq 0 "Beep Off" 1 "Beep On" 2 "Not Used" 3 "Error Indicator" ;
VAL_ 1216 BAlarm_AutoLockrReq 0 "Off" 1 "Lock" 2 "Not Used" 3 "Error Indicator" ;
VAL_ 1216 TiltTele_SmrtIMSDBNum 0 "None" 1 "0x1~0x97E:SmartIMS DB Number (1~2430)" 2430 "0x1~0x97E:SmartIMS DB Number (1~2430)" 4095 "Error indicator" ;
VAL_ 1216 Tilt_IMSMemoryCmd 0 "None" 1 "Memory 1" 2 "Memory 2" 3 "Memory 3" ;
VAL_ 1216 Tele_IMSMemoryCmd 0 "None" 1 "Memory 1" 2 "Memory 2" 3 "Memory 3" ;
VAL_ 2357404929 BMS_Crc6Val 65535 "Signal Invalid (Message with unused CRC. CRC signal is transmitted fixed value)" ;
VAL_ 2357404929 BMS_AlvCnt6Val 255 "Signal Invalid (Message with unused Alive counter. Alive counter signal is transmitted fixed value)" ;
VAL_ 2357404929 CHRG_StndChrgConnSta_120V 0 "Not Connected" 1 "Connected" 2 "Not used" 3 "Error indicator" ;
VAL_ 2357404929 CHRG_StndChrgSta 0 "None" 1 "Standard Charging" 2 "Not used" 3 "Error indicator" ;
VAL_ 2357404929 CHRG_ChrgCycStrtSta 0 "Charging Cycle Start Disable" 1 "Charging Cycle Start Enable" 2 "Not used" 3 "Error indicator" ;
VAL_ 2357404929 CHRG_FulChrgSta 0 "None" 1 "Fully Charged" 2 "Not used" 3 "Error indicator" ;
VAL_ 2357404929 CHRG_ChrgSta 0 "None" 1 "Charging" 2 "Not used" 3 "Error indicator" ;
VAL_ 2357404929 CHRG_SpplmntChrgSta 0 "Not operating" 1 "operation" 2 "complete" 3 "fail" ;
VAL_ 2357404929 CHRG_LdcInhbtReq 0 "Noraml" 1 "LDC Inhibit" 2 "Not used" 3 "Error indicator" ;
VAL_ 2357404929 CHRG_NorChgFnshSta 0 "normal" 1 "abnormal finish by OBC" 2 "abnormal finish by BMS" 3 "abnormal finish by others" ;
VAL_ 2357404929 CHRG_ChrgFnshSta 0 "Normal" 1 "Charge finished" 2 "Not used" 3 "Error indicator" ;
VAL_ 2357404929 CHRG_Ig3RlyOffReq 0 "Not Request" 1 "Request" 2 "Not used" 3 "Error indicator" ;
VAL_ 2357404929 CHRG_PShftChgSta 0 "Normal" 1 "P Shift For Charging" 2 "Not used" 3 "Error indicator" ;
VAL_ 2357404929 CHRG_PilotFlSta 0 "Normal" 1 "Notify Pilotline Fail" 2 "Not used" 3 "Error indicator" ;
VAL_ 2357404930 CHRG_ObcRlyOnSta 0 "Off" 1 "On" 2 "Not used" 3 "Error indicator" ;
VAL_ 2357404930 CHRG_NrmlOpSta 0 "Normal(repetitive change), Abnormal(fixed)" 1 "Normal(repetitive change), Abnormal(fixed)" ;
VAL_ 2357404930 CHRG_ChgLamp_1EA 0 "no connection" 1 "charging" 2 "charge completion" 3 "charging fail" 4 "reservation mode" ;
VAL_ 2357404932 CHRG_ChrgLmp_3EA 0 "Normal" 1 "Main Rly On Status On" 2 "SOC 0~35%" 3 "SOC 35~65%" 4 "SOC 65%~" 5 "Chargnig Complete" 6 "Charging Fail" 7 "Reservation Charging,OBC standby mode" ;
VAL_ 1079 CTM_TrailerAct 0 "Not Connected" 1 "Connected" 2 "Reserved" 3 "Invaild" ;
VAL_ 1079 CTM_ExtTailLmpLftOpnSta 0 "Normal" 1 "Open Status" 2 "Not Used" 3 "Error Indicator" ;
VAL_ 1079 CTM_ExtTailLmpRtOpnSta 0 "Normal" 1 "Open Status" 2 "Not Used" 3 "Error Indicator" ;
VAL_ 1079 CTM_Exra_EbrakSta 0 "Off" 1 "On" 2 "Not Used" 3 "Error Indicator" ;
VAL_ 1079 CTM_RearfogAct 0 "Off" 1 "On" 2 "Reserved" 3 "Invaild" ;
VAL_ 1079 CTM_StpLmpOpnSta 0 "Normal" 1 "Open Status" 2 "Not Used" 3 "Error Indicator" ;
VAL_ 1079 CTM_TrnSigLmpLftOpnSta 0 "Normal" 1 "Open Status" 2 "Not Used" 3 "Error Indicator" ;
VAL_ 1079 CTM_TrnSigLmpRtOpnSta 0 "Normal" 1 "Open Status" 2 "Not Used" 3 "Error Indicator" ;
VAL_ 2382594049 DATC_DrvTempCDis 0 "Blank Display" 1 "'LO' Display" 254 "'HI' Display" 255 "Error Indicator" ;
VAL_ 2382594049 DATC_DrvTempFDis 0 "Blank Display" 1 "'LO' Display" 254 "'HI' Display" 255 "Error Indicator" ;
VAL_ 2382594049 DATC_PassTempCDis 0 "Blank Display" 1 "'LO' Display" 254 "'HI' Display" 255 "Error Indicator" ;
VAL_ 2382594049 DATC_PassTempFDis 0 "Blank Display" 1 "'LO' Display" 254 "'HI' Display" 255 "Error Indicator" ;
VAL_ 2382594049 DATC_TempDispSta 0 "OLD Set Temp Display range" 1 "NEW Set Temp Display Range" 2 "Not used" 3 "Error Indicator" ;
VAL_ 2382594049 DATC_PreEngOnReq2 0 "Default" 1 "Off" 2 "PreEngineOn Request" 3 "Error Indicator" ;
VAL_ 1085 DLBCU_ActiveDis 0 "Default" 1 "Off" 2 "Mode1" 3 "Mode2" 4 "Mode3" 5 "Reserved" 6 "Reserved" 7 "Invalid" ;
VAL_ 1085 DLBCU_CushSoftSta 0 "Default" 1 "High(Soft)" 2 "Middle(Mid)" 3 "Low(Hard)" 4 "Reserved" 5 "Reserved" 6 "Off" 7 "Invalid" ;
VAL_ 1085 DLBCU_CellOpt 0 "Default" 1 "3Cell" 2 "5Cell" 3 "7Cell" 4 "Invalid" 5 "Invalid" 6 "Invalid" 7 "Invalid" ;
VAL_ 1085 DLBCU_BodySpprtSta 0 "Default" 1 "Off" 2 "On" 3 "Invalid" ;
VAL_ 1085 DLBCU_BodySpprtDis 0 "Default" 1 "Off" 2 "On" 3 "Invalid" ;
VAL_ 1085 DLBCU_SmartCtrl_Set_Rvalue 0 "Init" 1 "Off" 2 "10min" 3 "20min" 4 "30min" 5 "40min" 6 "50min" 7 "60min" 8 "Unused" 9 "Unused" 10 "Unused" 11 "Unused" 12 "Unused" 13 "Unused" 14 "Unused" 15 "Invalid" ;
VAL_ 1085 DLBCU_DrvModUSMSta 0 "Default" 1 "Off" 2 "On" 3 "Invalid" ;
VAL_ 1085 DLBCU_ActiveStrSta 0 "Default" 1 "Normal" 2 "Intensity" 3 "Invalid" ;
VAL_ 1085 DLBCU_ActiveTimeSta 0 "Default" 1 "10min" 2 "15min" 3 "20min" 4 "Reserved" 5 "Reserved" 6 "Reserved" 7 "Invalid" ;
VAL_ 687 HOD_Dir_Status 0 "HANDS OFF" 1 "HAND TOUCH (SOFT)" 2 "HAND TOUCH (STRONG)" 3 "HAND GRIP (SOFT)" 4 "HAND GRIP (STRONG)" 5 "Reserved" 6 "Reserved" 7 "INVALID" ;
VAL_ 687 HOD_Option 0 "HOD-Option-OFF" 1 "HOD-Option-On" ;
VAL_ 2164278529 HTCU_TrgtGearSta 0 "If N or P are detected(No frictional conncetion)" 1 "1st speed" 2 "2nd speed" 3 "3rd speed" 4 "4th speed" 5 "5th speed" 6 "6th speed" 7 "Reverse" 15 "--" ;
VAL_ 2164278529 HTCU_RdySta 0 "Not ready" 1 "Ready" 2 "Not used" 3 "Error Indicator" ;
VAL_ 2164278529 HTCU_GearChgSta 0 "Inactive" 1 "Active" 2 "Not used" 3 "Error Indicator" ;
VAL_ 2164278529 HTCU_FltSta 0 "No fault" 1 "TCU Diagnostic failure" 2 "Not used" 3 "TCU Diagnostic failure & Limphome activated" 4 "OPU/EOP Diagnostic failure" 5 "TCU & OPU/EOP Diagnostic failure" 6 "Not used" 7 "TCU/OPU Diagnostic failure & Limphome activated" ;
VAL_ 2164278529 HTCU_GearSlctrDis 0 "P" 1 "L" 2 "2" 3 "3" 4 "DS Mode" 5 "D" 6 "N" 7 "R" 8 "Sports mode / Manual Shift" 9 "Not display at Cluster" 10 "Sub-Rom Communication" 11 "Sub-Rom Communication Error" 12 "Paddle shift (D-Position)" 13 "Not used" 14 "Intermediate Position" 15 "Fault" ;
VAL_ 2164278529 HTCU_FanCtrlReq 0 "Not Request" 1 "Request" 2 "Not Used" 3 "Error Indicator" ;
VAL_ 2164278530 HTCU_TrgtShftClsCCanSta 0 "NO SHIFT" 1 "PON UP" 2 "POF UP" 3 "PON DN@HIGH SPEED(Not Used)" 4 "PON DN@LOW SPEED" 5 "POF DN" 6 "NSTP TO 5/4/3/2" 7 "NSTP TO 1" 8 "LOW_VSP SFT12" 9 "N-D 12" 10 "N-D 3456" 11 "N-D5(NOT USED)" 12 "N-R" 13 "N-N" 14 "PON DN WOT SHIFT (NOT USED)" 15 "PON DN SEMI SHIFT" 16 "D-N/R-N" 17 "RESERVED" 18 "RESERVED" 19 "RESERVED" 20 "FAILSAFE 2-3-4 SHIFT" 21 "RESERVED" 22 "RESERVED" 23 "RESERVED" 24 "RESERVED" 25 "RESERVED" 26 "RESERVED" 27 "RESERVED" 28 "RESERVED" 29 "RESERVED" 30 "RESERVED" 31 "RESERVED" ;
VAL_ 2164278530 HTCU_CtrlablSta 0 "Not ready" 1 "TCU Controllable" 2 "Not Used" 3 "Error Indicator" ;
VAL_ 2164278530 HTCU_PrgrmSta 0 "PR_NML" 1 "PR_MED" 2 "PR_SPTY" 3 "PR_LD1" 4 "PR_LD2" 5 "PR_LD3" 6 "PR_DLD" 7 "PR_LD1_H" 8 "PR_LD2_H" 9 "PR_LD3_H" 10 "PR_PRT" 11 "PR_WRM_UP" 12 "PR_BLUE" 13 "PR_ECO_ATC" 14 "PR_LD_ATC" 15 "PR_LD_ATC_H" 16 "PR_HWY" 17 "PR_SOL_L" 18 "PR_SOL_M" 19 "PR_SOL_H" 20 "PR_REGEN" 21 "PR_TF_LO" 22 "PR_TCS" 23 "PR_LD_TCS" 24 "PR_DS" 25 "PR_EV_BLUE" 26 "PR_EV_NML" 27 "PR_EV_SOC_H" 28 "PR_EV_SOC_L" 29 "PR_EV_HWY" 30 "PR_SOS" 31 "PR_ECO_ATC_EV" 32 "PR_LD_ATC_EV" 33 "PR_LD_ATC_HI_EV" 34 "PR_LD2_ATC" 35 "PR_LD3_ATC" 36 "PR_LD2_ATC_H" 37 "PR_LD3_ATC_H" 38 "PR_EC_PRT" ;
VAL_ 2164278530 HTCU_FsCltchLmphmActvSta 0 "Inactive" 1 "Active" 2 "Not used" 3 "Error Indicator" ;
VAL_ 2164278531 HTCU_RapidKDReq 0 "Inactive" 1 "Active" 2 "Not used" 3 "Error Indicator" ;
VAL_ 2164278531 HTCU_CurrGearSta 0 "If N or P are detected(No frictional conncetion)" 1 "1st speed" 2 "2nd speed" 3 "3rd speed" 4 "4th speed" 5 "5th speed" 6 "6th speed" 7 "Reverse" 8 "--" 15 "--" ;
VAL_ 2164278531 HTCU_GearShftUpDisGSI 0 "Gear Shiftup Display Off" 1 "Gear Shiftup Display On" 2 "Not used" 3 "Error Indicator" ;
VAL_ 2164278531 HTCU_GearShftDnDisGSI 0 "Gear Shiftdown Display Off" 1 "Gear Shiftdown Display On" 2 "Not used" 3 "Error Indicator" ;
VAL_ 2164278531 HTCU_TrgtGearStaGSI 0 "--" 1 "1st speed" 2 "2nd speed" 3 "3rd speed" 4 "4th speed" 5 "5th speed" 6 "6th speed" 7 "--" 8 "--" 9 "--" ;
VAL_ 2164278531 HTCU_SolBSta 0 "OFF" 1 "ON" 2 "Not used" 3 "Error Indicator" ;
VAL_ 1219 BLTN_CAM_Rec_OWD_NvalueSet 0 "Default" 1 "Off" 2 "On" 3 "Invalid" ;
VAL_ 1219 BLTN_CAM_Time_Stm_NvalueSet 0 "Default" 1 "Off" 2 "On" 3 "Invalid" ;
VAL_ 1219 BLTN_CAM_Spd_Stm_NvalueSet 0 "Default" 1 "Off" 2 "On" 3 "Invalid" ;
VAL_ 1219 BLTN_CAM_Locatn_Stm_NvalueSet 0 "Default" 1 "Off" 2 "On" 3 "Invalid" ;
VAL_ 1219 BLTN_CAM_TrnSig_Stm_NvalueSet 0 "Default" 1 "Off" 2 "On" 3 "Invalid" ;
VAL_ 1219 BLTN_CAM_AclBrk_Stm_NvalueSet 0 "Default" 1 "Off" 2 "On" 3 "Invalid" ;
VAL_ 1219 BLTN_CAM_Rec_DEV_NvalueSet 0 "Default" 1 "Off" 2 "On" 3 "Invalid" ;
VAL_ 1219 BLTN_CAM_GearPos_Stm_NvalueSet 0 "Default" 1 "Off" 2 "On" 3 "Invalid" ;
VAL_ 1219 BLTN_CAM_EVSen_Stm_NvalueSet 0 "Default" 1 "Off" 2 "On" 3 "Invalid" ;
VAL_ 1219 BLTN_CAM_Strangl_Stm_NvalueSet 0 "Default" 1 "Off" 2 "On" 3 "Invalid" ;
VAL_ 1219 BLTN_CAM_PrkTime_NvalueSet 0 "Default" 1 "0x01~0xFB:1~ 251  hr" 251 "0x01~0xFB:1~ 251  hr" 252 "RESERVED" 253 "RESERVED" 254 "Not Supported" 255 "Invalid" ;
VAL_ 1219 BLTN_CAM_EV_BfrTime_NvalueSet 0 "10~20 sec" 1 "10~20 sec" 2 "10~20 sec" 3 "10~20 sec" 4 "10~20 sec" 5 "10~20 sec" 6 "10~20 sec" 7 "10~20 sec" 8 "10~20 sec" 9 "10~20 sec" 10 "10~20 sec" 11 "Reserved" 12 "Reserved" 13 "Reserved" 14 "Reserved" 15 "Reserved" 16 "Reserved" 17 "Reserved" 18 "Reserved" 19 "Reserved" 20 "Reserved" 21 "Reserved" 22 "Reserved" 23 "Reserved" 24 "Reserved" 25 "Reserved" 26 "Reserved" 27 "Reserved" 28 "Reserved" 29 "Reserved" 30 "Reserved" 31 "Invalid" ;
VAL_ 1219 BLTN_CAM_Rec_OWP_NvalueSet 0 "Default" 1 "Off" 2 "On" 3 "Invalid" ;
VAL_ 1219 BLTN_CAM_EV_AftTime_NvalueSet 0 "10~20 sec" 1 "10~20 sec" 2 "10~20 sec" 3 "10~20 sec" 4 "10~20 sec" 5 "10~20 sec" 6 "10~20 sec" 7 "10~20 sec" 8 "10~20 sec" 9 "10~20 sec" 10 "10~20 sec" 11 "Reserved" 12 "Reserved" 13 "Reserved" 14 "Reserved" 15 "Reserved" 16 "Reserved" 17 "Reserved" 18 "Reserved" 19 "Reserved" 20 "Reserved" 21 "Reserved" 22 "Reserved" 23 "Reserved" 24 "Reserved" 25 "Reserved" 26 "Reserved" 27 "Reserved" 28 "Reserved" 29 "Reserved" 30 "Reserved" 31 "Invalid" ;
VAL_ 1219 BLTN_CAM_TML_Int_NvalueSet 0 "Default" 1 "1~ 10 sec" 2 "1~ 10 sec" 3 "1~ 10 sec" 4 "1~ 10 sec" 5 "1~ 10 sec" 6 "1~ 10 sec" 7 "1~ 10 sec" 8 "1~ 10 sec" 9 "1~ 10 sec" 10 "1~ 10 sec" 11 "Reserved" 12 "Reserved" 13 "Reserved" 14 "Reserved" 15 "Invalid" ;
VAL_ 1219 BLTN_CAM_Sen_DEV_NvalueSet 0 "Default" 1 "Level 1" 2 "Level 2" 3 "Level 3" 4 "Level 4" 5 "Level 5" 6 "Reserved" 7 "Reserved" 8 "Reserved" 9 "Reserved" 10 "Reserved" 11 "Reserved" 12 "Reserved" 13 "Reserved" 14 "Reserved" 15 "Invalid" ;
VAL_ 1219 BLTN_CAM_Sen_PEV_NvalueSet 0 "Default" 1 "Level 1" 2 "Level 2" 3 "Level 3" 4 "Level 4" 5 "Level 5" 6 "Reserved" 7 "Reserved" 8 "Reserved" 9 "Reserved" 10 "Reserved" 11 "Reserved" 12 "Reserved" 13 "Reserved" 14 "Reserved" 15 "Invalid" ;
VAL_ 1219 BLTN_CAM_Rec_PEV_NvalueSet 0 "Default" 1 "Off" 2 "On" 3 "Invalid" ;
VAL_ 1219 BLTN_CAM_AudRec_NvalueSet 0 "Default" 1 "Off" 2 "On" 3 "Invalid" ;
VAL_ 1221 HU_ChgInCurrModSet 0 "Default" 1 "Maximum" 2 "Decreasing" 3 "Minimum" 4 "Reserved" 5 "Reserved" 6 "Reserved" 7 "Invalid" ;
VAL_ 1221 SWRC_Sensitivity_SET 0 "Medium(default)" 1 "Low" 2 "High" 3 "Invalid" ;
VAL_ 1221 HU_EV_WinterMode 0 "Winter mode Off" 1 "Winter mode On" 2 "Reserved" 3 "Invalid" ;
VAL_ 1221 HU_TgSoc_ScChg_Set 0 "0x0x0~0xC8:PHY = HEX * 0.5" 200 "0x0x0~0xC8:PHY = HEX * 0.5" 201 "Reserved" 202 "Reserved" 203 "Reserved" 204 "Reserved" 205 "Reserved" 206 "Reserved" 207 "Reserved" 208 "Reserved" 209 "Reserved" 210 "Reserved" 211 "Reserved" 212 "Reserved" 213 "Reserved" 214 "Reserved" 215 "Reserved" 216 "Reserved" 217 "Reserved" 218 "Reserved" 219 "Reserved" 220 "Reserved" 221 "Reserved" 222 "Reserved" 223 "Reserved" 224 "Reserved" 225 "Reserved" 226 "Reserved" 227 "Reserved" 228 "Reserved" 229 "Reserved" 230 "Reserved" 231 "Reserved" 232 "Reserved" 233 "Reserved" 234 "Reserved" 235 "Reserved" 236 "Reserved" 237 "Reserved" 238 "Reserved" 239 "Reserved" 240 "Reserved" 241 "Reserved" 242 "Reserved" 243 "Reserved" 244 "Reserved" 245 "Reserved" 246 "Reserved" 247 "Reserved" 248 "Reserved" 249 "Reserved" 250 "Reserved" 251 "Reserved" 252 "Reserved" 253 "Reserved" 254 "Reserved" 255 "Invalid" ;
VAL_ 1221 HU_TgSoc_QcChg_Set 0 "0x0x0~0xC8:PHY = HEX * 0.5" 200 "0x0x0~0xC8:PHY = HEX * 0.5" 201 "Reserved" 202 "Reserved" 203 "Reserved" 204 "Reserved" 205 "Reserved" 206 "Reserved" 207 "Reserved" 208 "Reserved" 209 "Reserved" 210 "Reserved" 211 "Reserved" 212 "Reserved" 213 "Reserved" 214 "Reserved" 215 "Reserved" 216 "Reserved" 217 "Reserved" 218 "Reserved" 219 "Reserved" 220 "Reserved" 221 "Reserved" 222 "Reserved" 223 "Reserved" 224 "Reserved" 225 "Reserved" 226 "Reserved" 227 "Reserved" 228 "Reserved" 229 "Reserved" 230 "Reserved" 231 "Reserved" 232 "Reserved" 233 "Reserved" 234 "Reserved" 235 "Reserved" 236 "Reserved" 237 "Reserved" 238 "Reserved" 239 "Reserved" 240 "Reserved" 241 "Reserved" 242 "Reserved" 243 "Reserved" 244 "Reserved" 245 "Reserved" 246 "Reserved" 247 "Reserved" 248 "Reserved" 249 "Reserved" 250 "Reserved" 251 "Reserved" 252 "Reserved" 253 "Reserved" 254 "Reserved" 255 "Invalid" ;
VAL_ 1221 HU_UserApproval 0 "Initial Value" 1 "Approve" 2 "Reject" 3 "Start Trigger" 4 "Unrecognized Reject" 5 "Reserved" 6 "Reserved" 7 "Reserved" 8 "Reserved" 9 "Reserved" 10 "Reserved" 11 "Reserved" 12 "Reserved" 13 "Reserved" 14 "Reserved" 15 "Invalid" ;
VAL_ 1221 HU_OtaInfomationReq 0 "Initial" 1 "Vehicle S/W Version" 2 "What's New (Text Only)" 3 "Download progress" 4 "Update progress" 5 "Reserved" 6 "Reserved" 7 "Reserved" 8 "Reserved" 9 "Reserved" 10 "Reserved" 11 "Reserved" 12 "Reserved" 13 "Reserved" 14 "Reserved" 15 "Invalid" ;
VAL_ 1076 IAU_ProfileIDRVal 0 "Default" 1 "Guest" 2 "Profile1" 3 "Profile2" 4 "Reserved" 5 "Reserved" 6 "Reserved" 7 "Reserved" 8 "Reserved" 9 "Reserved" 10 "Reserved" 11 "Reserved" 12 "Reserved" 13 "Reserved" 14 "Reserved" 15 "Invalid" ;
VAL_ 1076 IAU_DigitalKeyProcessingSta 0 "None" 1 "DeviceOnWPC" 2 "DeviceRegistering" 3 "PhoneRegistered" 4 "All Phone Key Deleted" 5 "NFCCard1Registered" 6 "Server Registering" 7 "NFCCard1Deleted" 8 "BLE Searching" 9 "Owner Phone key Deleted" 10 "Valet Off Searching" 11 "Server Registering Fail" 12 "Reserved" 13 "Reserved" 14 "Reserved" 15 "Invalid" ;
VAL_ 1076 IAU_DigitalKeyExit 0 "Normal" 1 "Check System" 2 "NFC Not Detected" 3 "Fob Not Detected" 4 "Canceled by User (Timeout)" 5 "Device not Available" 6 "ProcessFail" 7 "Check Card Save" 8 "Certificate Update" 9 "Valet Off Fail" 10 "CardNotAvailable" 11 "DigitalKeyDisabled" 12 "KeyNotSaved" 13 "Reserved" 14 "Reserved" 15 "Invalid" ;
VAL_ 1076 IAU_DigitalKeyEnblRVal 0 "Default" 1 "Disable" 2 "Enable" 3 "Invalid" ;
VAL_ 1076 IAU_OwnerPhnRegRVal 0 "Default" 1 "Disable" 2 "Enable" 3 "Invalid" ;
VAL_ 1076 IAU_NFCCard1RegRVal 0 "Default" 1 "Disable" 2 "Enable" 3 "Invalid" ;
VAL_ 1076 IAU_NFCCard2RegRVal 0 "Default" 1 "Disable" 2 "Enable" 3 "Invalid" ;
VAL_ 1076 IAU_DISPWrng 0 "None" 1 "Auth_Fail2 (DigitalKey)" 2 "ReAuth_Warning" 3 "IAU Error" 4 "DigitalKey Saved" 5 "Auth_Fail2 (FP)" 6 "Auth_Fail2 (DigitalKey or FP)" 7 "BiometricKey Saved" 8 "DigitalKey and BiometricKey Saved" 9 "Reserved" 10 "Reserved" 11 "Reserved" 12 "Reserved" 13 "Reserved" 14 "Reserved" 15 "Invalid" ;
VAL_ 1076 IAU_DigitalKey2Opt 0 "Default (Not applied)" 1 "Digital Key Light (NFC)" 2 "Digital Key Medium (NFC/BLE)" 3 "Digital Key Full (NFC/BLE/UWB)" 4 "Reserved" 5 "Reserved" 6 "Reserved" 7 "invalid" ;
VAL_ 1076 IAUwFRULearnState 0 "Default (Normal)" 1 "Learning" 2 "Neutralizing" 3 "Invalid" ;
VAL_ 1076 IAUwFPMLearnState 0 "Default(Normal)" 1 "Learning" 2 "Neutralizing" 3 "Invalid" ;
VAL_ 1059 PSU_DiagSta 0 "Stop Diag" 1 "Start Diag" 2 "RESERVED" 3 "Error Indicator" ;
VAL_ 1059 Ast_2ndAutoRlxEnable 0 "Default" 1 "Enable" 2 "Disable" 3 "Invalid" ;
VAL_ 1059 Ast_AutoRlxSta 0 "Default" 1 "Auto Relaxion Moving" 2 "RESERVED" 3 "Invalid" ;
VAL_ 1059 PSU_EsyAcsGetOnSta 0 "off" 1 "on" 2 "RESERVED" 3 "Error Indicator" ;
VAL_ 1059 PSU_EsyAcsGetOffSta 0 "off" 1 "on" 2 "RESERVED" 3 "Error Indicator" ;
VAL_ 1059 PSU_EsyAcsStpSta 0 "off" 1 "on" 2 "RESERVED" 3 "Error Indicator" ;
VAL_ 1059 PSU_RVal 0 "Default Value" 1 "Off(Disable)" 2 "Enable" 3 "RESERVED" 4 "RESERVED" 5 "RESERVED" 6 "RESERVED" 7 "Invalid" ;
VAL_ 1086 RL_CURTAIN_POSITION 0 "Bottom" 1 "Middle" 2 "Top" 3 "Unknown(Curtain not Initialized)" ;
VAL_ 1086 RDC_SWVerMinor1 0 "0x0x0~0x7F:ASCII Code Value (HEX)" 127 "0x0x0~0x7F:ASCII Code Value (HEX)" ;
VAL_ 1086 RDC_SWVerMinor2 0 "0x0x0~0x7F:ASCII Code Value (HEX)" 127 "0x0x0~0x7F:ASCII Code Value (HEX)" ;
VAL_ 1086 RR_CURTAIN_POSITION 0 "Bottom" 1 "Middle" 2 "Top" 3 "Unknown(Curtain not Initialized)" ;
VAL_ 1086 RDC_RLDNInitFlag 0 "Off" 1 "On" 2 "Not Used" 3 "Error Indicator" ;
VAL_ 1086 RDC_RRDNInitFlag 0 "Off" 1 "On" 2 "Not Used" 3 "Error Indicator" ;
VAL_ 1086 RDC_RLOpState 0 "Off" 1 "On" 2 "Not Used" 3 "Error Indicator" ;
VAL_ 1086 RDC_RROpState 0 "Off" 1 "On" 2 "Not Used" 3 "Error Indicator" ;
VAL_ 1086 RDC_OptTyp 0 "Default" 1 "RDC Option" 2 "Not Used" 3 "Error Indicator" ;
VAL_ 1086 RDC_SWVerMajor1 0 "ASCII Code Value (HEX)" 1 "ASCII Code Value (HEX)" 2 "ASCII Code Value (HEX)" 3 "ASCII Code Value (HEX)" 4 "ASCII Code Value (HEX)" 5 "ASCII Code Value (HEX)" 6 "ASCII Code Value (HEX)" 7 "ASCII Code Value (HEX)" 8 "ASCII Code Value (HEX)" 9 "ASCII Code Value (HEX)" 10 "ASCII Code Value (HEX)" 11 "ASCII Code Value (HEX)" 12 "ASCII Code Value (HEX)" 13 "ASCII Code Value (HEX)" 14 "ASCII Code Value (HEX)" 15 "ASCII Code Value (HEX)" ;
VAL_ 1080 RL_SHVU_SeatOptSta 0 "Init" 1 "Heater only 2step" 2 "Heater only 3step" 3 "Vent only 2step" 4 "Vent only 3step" 5 "Heater and Vent 2step" 6 "Heater and Vent 3step" 7 "Invalid" ;
VAL_ 1080 RL_SHVU_SeatHtOperSta 0 "Init" 1 "RESERVED" 2 "Heater & Vent OFF" 3 "Vent Low" 4 "Vent Mid" 5 "Vent High" 6 "Heater Low" 7 "Heater Mid" 8 "Heater High" 9 "RESERVED" 10 "RESERVED" 11 "RESERVED" 12 "RESERVED" 13 "RESERVED" 14 "RESERVED" 15 "Invalid" ;
VAL_ 1080 RL_SHVU_HtSwHiIndSta_RHD 0 "OFF" 1 "ON" 2 "Not used" 3 "Error Indicator" ;
VAL_ 1080 RL_SHVU_HtSwMidIndSta_RHD 0 "OFF" 1 "ON" 2 "Not used" 3 "Error Indicator" ;
VAL_ 1080 RL_SHVU_HtSwLowIndSta_RHD 0 "OFF" 1 "ON" 2 "Not used" 3 "Error Indicator" ;
VAL_ 1080 RL_SHVU_VntSwHiIndSta_RHD 0 "OFF" 1 "ON" 2 "Not used" 3 "Error Indicator" ;
VAL_ 1080 RL_SHVU_VntSwMidIndSta_RHD 0 "OFF" 1 "ON" 2 "Not used" 3 "Error Indicator" ;
VAL_ 1080 RL_SHVU_VntSwLowIndSta_RHD 0 "OFF" 1 "ON" 2 "Not used" 3 "Error Indicator" ;
VAL_ 1080 RL_SHVU_HtBlcUsmSta_RHD 0 "Default" 1 "Normal" 2 "Back 1" 3 "Back 2" 4 "Back 3" 5 "Cush 1" 6 "Cush 2" 7 "Cush 3" 8 "Reserved" 9 "Reserved" 10 "Reserved" 11 "Reserved" 12 "Reserved" 13 "Reserved" 14 "Reserved" 15 "Invaild" ;
VAL_ 1073 USM_ValCmdSta 0 "Default" 1 "Off(Disable)" 2 "On(Enable)" 3 "Invalid" ;
VAL_ 1073 RWPC_SWVerMinor1 0 "0x0x0~0x7F:ASCII Code Value (HEX)" 127 "0x0x0~0x7F:ASCII Code Value (HEX)" ;
VAL_ 1073 WPC_PhnLftWrngRWPCSta 0 "Off" 1 "Cellphone on the pad" 2 "Charging" 3 "Charging complete" 4 "Cellphone reminder" 5 "Error" 6 "Reserved" 7 "Invalid" ;
VAL_ 1073 RWPC_SWVerMinor2 0 "0x0x0~0x7F:ASCII Code Value (HEX)" 127 "0x0x0~0x7F:ASCII Code Value (HEX)" ;
VAL_ 1073 USM_ValCmdStaforATS 0 "Default" 1 "Off(Disable)" 2 "On(Enable)" 3 "Invalid" ;
VAL_ 1073 RWPC_SWVerMajor1 0 "ASCII Code Value (HEX)" 1 "ASCII Code Value (HEX)" 2 "ASCII Code Value (HEX)" 3 "ASCII Code Value (HEX)" 4 "ASCII Code Value (HEX)" 5 "ASCII Code Value (HEX)" 6 "ASCII Code Value (HEX)" 7 "ASCII Code Value (HEX)" 8 "ASCII Code Value (HEX)" 9 "ASCII Code Value (HEX)" 10 "ASCII Code Value (HEX)" 11 "ASCII Code Value (HEX)" 12 "ASCII Code Value (HEX)" 13 "ASCII Code Value (HEX)" 14 "ASCII Code Value (HEX)" 15 "ASCII Code Value (HEX)" ;
VAL_ 139 SWRC_DriveModCWSwSta 0 "Off" 1 "On" 2 "Reserved" 3 "Invalid" ;
VAL_ 139 SWRC_DriveModCCWSwSta 0 "Off" 1 "On" 2 "Reserved" 3 "Invalid" ;
VAL_ 139 SWRC_BoostSwSta 0 "Off" 1 "Key On" 2 "Reserved" 3 "Invalid" ;
VAL_ 139 SWRC_DriveModeSwSta 0 "Off" 1 "On" 2 "Reserved" 3 "Invalid" ;
VAL_ 139 SWRC_TerrainModeSwSta 0 "Off" 1 "On" 2 "Reserved" 3 "Invalid" ;
VAL_ 139 SWRC_N1SwSta 0 "Off" 1 "Key On" 2 "RESERVED" 3 "Invalid" ;
VAL_ 139 SWRC_N2SwSta 0 "Off" 1 "Key On" 2 "RESERVED" 3 "Invalid" ;
VAL_ 2160080129 VCU_RdySta 0 "None" 1 "VCU Control Board Ready" 2 "Not used" 3 "Error Indicator" ;
VAL_ 2160080129 VCU_StartKeyHoldSta 0 "None" 1 "Start" 2 "Not used" 3 "Error Indicator" ;
VAL_ 2160080129 VCU_EvDrvRdySta 0 "None" 1 "EV Drivable" 2 "Not used" 3 "Error Indicator" ;
VAL_ 2160080129 VCU_MotPwrEnReq 0 "None" 1 "Allow Motor System to Control" 2 "Not used" 3 "Error Indicator" ;
VAL_ 2160080129 VCU_GearPosSta 0 "P" 1 "B" 2 "Not Used" 3 "Not Used" 4 "Not Used" 5 "D" 6 "N" 7 "R" 8 "Not Used" 9 "Not Display at Cluster" 10 "Reserved" 11 "Reserved" 12 "Reserved" 13 "Reserved" 14 "Intermediate Position" 15 "Fault" ;
VAL_ 2160080129 VCU_LdcInhReq 0 "None" 1 "LDC Off Request" 2 "Not used" 3 "Error Indicator" ;
VAL_ 2160080129 VCU_MainRlyOffReq 0 "None" 1 "Relay Cut Off" 2 "Not used" 3 "Error Indicator" ;
VAL_ 2160080129 VCU_AccPedDepVal 255 "Error Indicator" ;
VAL_ 2160080129 VCU_FatcOperPermSta 0 "Not Permiited" 1 "Permitted" 2 "Not used" 3 "Error Indicator" ;
VAL_ 2160080129 VCU_DrvCycSta 0 "No Driving Cycle Active" 1 "Driving Cycle Active" 2 "Not used" 3 "Error Indicator" ;
VAL_ 2160080129 VCU_CltActOpSta 0 "Neutral" 1 "Actuating" 2 "In Gear" 3 "Referencing" 4 "Fault" ;
VAL_ 2160080129 VCU_WhlSpdSnsrAlvReq 0 "No Request" 1 "Alive Request" 2 "Not used" 3 "Error Indicator" ;
VAL_ 2160080129 VCU_DrvModOpSta 0 "Eco" 1 "Normal" 2 "Sport" 3 "Reserved" 4 "Reserved" 5 "Snow" 6 "Sand" 7 "Mud" 8 "Reserved" 9 "Reserved" 10 "Reserved" 11 "Reserved" 12 "Reserved" 13 "Reserved" 14 "Reserved" 15 "Reserved" ;
VAL_ 2160080129 VCU_IgOffGearPosStaDispReq 0 "No Request" 1 "Request" 2 "Not used" 3 "Error indicator" ;
VAL_ 2160080130 VCU_McuAntiJerkInhFrntSta 0 "Anti-jerk Not Inhibit" 1 "Anti-jerk Inhibit" 2 "Not used" 3 "Error Indicator" ;
VAL_ 2160080130 VCU_McuAntiJerkInhRearSta 0 "Anti-jerk Not Inhibit" 1 "Anti-jerk Inhibit" 2 "Not used" 3 "Error Indicator" ;
VAL_ 2160080130 VCU_McuPwrLatchHoldReq 0 "No Request" 1 "Power Latch Hold Request" 2 "Not used" 3 "Error Indicator" ;
VAL_ 2160080130 VCU_ScuParkReq 0 "Wait Command" 1 "Not used" 2 "Parking Command" 3 "Not Parking Command" ;
VAL_ 2160080130 VCU_ScuKeepWakeReq 0 "None" 1 "Keep Wake Request" 2 "Not used" 3 "Error Indicator" ;
VAL_ 2160080130 VCU_FmcuZeroTqOfsReq 0 "No Request" 1 "Request" 2 "Not used" 3 "Error Indicator" ;
VAL_ 2160080131 VCU_EcmSeqSta 0 "IG Off" 1 "IG On_PowerLatch" 2 "IG On Init" 3 "IG On_Rdy" 4 "IG On_Drivalble" 5 "IG On_PD" 6 "IGON_NonDrivable" ;
VAL_ 2160080131 VCU_MainBattTypeSta 0 "Short Range Type" 1 "Standard Range Type" 2 "Long Range Type" 3 "Not Used" ;
VAL_ 2160080131 VCU_MainBattTypeLrnSta 0 "Unlearnt" 1 "Learnt" 2 "Not used" 3 "Error Indicator" ;
VAL_ 2160080131 VCU_WarmupCycSta 0 "None" 1 "Warm-up Cycle Completed" 2 "Not used" 3 "Error Indicator" ;
VAL_ 2160080132 VCU_GearPosStaDisp 0 "P" 1 "B" 2 "Not Used" 3 "Not Used" 4 "Not Used" 5 "D" 6 "N" 7 "R" 8 "Not Used" 9 "Not Display at Cluster" 10 "Reserved" 11 "Reserved" 12 "Manual Shift Mode on Retromode" 13 "Reserved" 14 "Intermediate Position" 15 "Fault" ;
VAL_ 2160080132 VCU_PdwLmtOperSta 0 "Off" 1 "On" 2 "Reserved" 3 "Reserved" ;
VAL_ 2160080132 VCU_PdwLmtBrkRequest 0 "Off" 1 "On" 2 "Reserved" 3 "Reserved" ;
VAL_ 2160080132 VCU_VgsVirSoundBackFireIndex 0 "No Action Status" 1 "Tip-Out Back Fire Lv1 ~ Lv8" 2 "Tip-Out Back Fire Lv1 ~ Lv8" 3 "Tip-Out Back Fire Lv1 ~ Lv8" 4 "Tip-Out Back Fire Lv1 ~ Lv8" 5 "Tip-Out Back Fire Lv1 ~ Lv8" 6 "Tip-Out Back Fire Lv1 ~ Lv8" 7 "Tip-Out Back Fire Lv1 ~ Lv8" 8 "Tip-Out Back Fire Lv1 ~ Lv8" 17 "Bubbling Sound Lv1 ~ Lv8" 18 "Bubbling Sound Lv1 ~ Lv8" 19 "Bubbling Sound Lv1 ~ Lv8" 20 "Bubbling Sound Lv1 ~ Lv8" 21 "Bubbling Sound Lv1 ~ Lv8" 22 "Bubbling Sound Lv1 ~ Lv8" 23 "Bubbling Sound Lv1 ~ Lv8" 24 "Bubbling Sound Lv1 ~ Lv8" 9 "Upshift BANG Sound Lv1 ~ Lv8" 10 "Upshift BANG Sound Lv1 ~ Lv8" 11 "Upshift BANG Sound Lv1 ~ Lv8" 12 "Upshift BANG Sound Lv1 ~ Lv8" 13 "Upshift BANG Sound Lv1 ~ Lv8" 14 "Upshift BANG Sound Lv1 ~ Lv8" 15 "Upshift BANG Sound Lv1 ~ Lv8" 16 "Upshift BANG Sound Lv1 ~ Lv8" ;
VAL_ 2160080132 VCU_VgsVirEngSpdRpmVal 0 "0x0x0~0x7FFE:RPM" 32766 "0x0x0~0x7FFE:RPM" 32767 "Error Indicator" ;
VAL_ 2160080132 VCU_VgsVirSoundVolume 0 "0x0x0~0xFE:0~100%" 254 "0x0x0~0xFE:0~100%" 0 "0x0~0xFF:Invalid Error" 255 "0x0~0xFF:Invalid Error" ;
VAL_ 2160080132 VCU_VgsVirGearStep 0 "Not Used" 1 "1gear" 2 "2gear" 3 "3gear" 4 "4gear" 5 "5gear" 6 "6gear" 7 "7gear" 8 "8gear" 9 "Reserved" 10 "Reserved" 11 "Reserved" 12 "Reserved" 13 "Reserved" 14 "Reserved" 15 "Reserved" ;
